VERSION ""

NS_ :

BS_:

BU_: SR_RR SR_RF SR_LR SR_LF DACU

BO_ 277 DACU_EgoMotionRaw_Vic4: 32 DACU
 SG_ EgoMotionRaw_RAxleLeftWSpeed : 72|16@1+ (0.00390625,0) [0|255.99609375] "Km_per_h"  SR_LF,SR_LR,SR_RR,SR_RF
 SG_ EgoMotionRaw_RelLvlRrAxleLeft : 160|16@1+ (0.1,-3200) [-3200|3353.5] "mm"  SR_RF,SR_LR,SR_LF,SR_RR
 SG_ EgoMotionRaw_RelLvlFrAxleRight : 208|16@1+ (0.1,-3200) [-3200|3353.5] "mm"  SR_LF,SR_RF,SR_LR,SR_RR
 SG_ EgoMotionRaw_AccPedalPos : 128|8@1+ (0.4,0) [0|102] "Percent"  SR_RF,SR_LF,SR_RR,SR_LR
 SG_ EgoMotionRaw_BrakePedalPosition : 120|8@1+ (0.4,0) [0|102] "Percent"  SR_LR,SR_RR,SR_RF,SR_LF
 SG_ EgoMotionRaw_FrAxleLeftWSpeed : 24|16@1+ (0.00390625,0) [0|255.99609375] "Km_per_h"  SR_LF,SR_RR,SR_LR,SR_RF
 SG_ EgoMotionRaw_FrontWheelAngle : 56|16@1+ (5E-005,-1.6) [-1.6|1.67675] "rad"  SR_LF,SR_LR,SR_RF,SR_RR
 SG_ EgoMotionRaw_ASREngineA : 152|2@1+ (1,0) [0|0] ""  SR_RR,SR_RF,SR_LF,SR_LR
 SG_ EgoMotionRaw_ASRBrakeA : 156|2@1+ (1,0) [0|0] ""  SR_LR,SR_RR,SR_RF,SR_LF
 SG_ EgoMotionRaw_ABSActive : 144|2@1+ (1,0) [0|0] ""  SR_RR,SR_LR,SR_RF,SR_LF
 SG_ EgoMotionRaw_VDCFullyOperational : 146|2@1+ (1,0) [0|0] ""  SR_LR,SR_RF,SR_RR,SR_LF
 SG_ EgoMotionRaw_ROPEngineActive : 148|2@1+ (1,0) [0|0] ""  SR_LF,SR_LR,SR_RR,SR_RF
 SG_ EgoMotionRaw_YCBrakeActive : 154|2@1+ (1,0) [0|0] ""  SR_LR,SR_RF,SR_RR,SR_LF
 SG_ EgoMotionRaw_GrossCombVehWeight : 224|16@1+ (10,0) [0|655350] "kg"  SR_LF,SR_RF,SR_RR,SR_LR
 SG_ EgoMotionRaw_RelLvlFrAxleLeft : 192|16@1+ (0.1,-3200) [-3200|3353.5] "mm"  SR_RF,SR_LF,SR_LR,SR_RR
 SG_ EgoMotionRaw_Counter : 16|8@1+ (1,0) [0|255] "Count"  SR_RF,SR_RR,SR_LR,SR_LF
 SG_ EgoMotionRaw_RAxleRightWSpeed : 88|16@1+ (0.00390625,0) [0|255.99609375] "Km_per_h"  SR_LF,SR_LR,SR_RF,SR_RR
 SG_ EgoMotionRaw_TrailerConStatus : 240|4@1+ (1,0) [0|0] ""  SR_RF,SR_LR,SR_RR,SR_LF
 SG_ EgoMotionRaw_FrAxleRightWSpeed : 40|16@1+ (0.00390625,0) [0|255.99609375] "Km_per_h"  SR_RF,SR_LR,SR_LF,SR_RR
 SG_ EgoMotionRaw_SteeringWheelAngle : 104|16@1+ (0.0009765625,-31.374) [-31.374|32.6250234375] "rad"  SR_LF,SR_RF,SR_RR,SR_LR
 SG_ EgoMotionRaw_ABSOp : 244|2@1+ (1,0) [0|0] ""  SR_RF,SR_LR,SR_LF,SR_RR
 SG_ EgoMotionRaw_CRC : 0|16@1+ (1,0) [0|65535] "NotApplicable"  SR_RR,SR_RF,SR_LR,SR_LF
 SG_ EgoMotionRaw_ROPBrakeActive : 150|2@1+ (1,0) [0|0] ""  SR_LF,SR_LR,SR_RF,SR_RR
 SG_ EgoMotionRaw_RelLvlRrAxleRight : 176|16@1+ (0.1,-3200) [-3200|3353.5] "mm"  SR_LR,SR_RR,SR_RF,SR_LF
 SG_ EgoMotionRaw_YCEngineActive : 142|2@1+ (1,0) [0|0] ""  SR_LR,SR_RR,SR_RF,SR_LF
 SG_ EgoMotionRaw_SteeringWheelRatio : 136|6@1+ (1,0) [0|63] "NotApplicable"  SR_LF,SR_RF,SR_RR,SR_LR
 SG_ EgoMotionRaw_AccKckDwn : 158|2@1+ (1,0) [0|0] ""  SR_RF,SR_LF,SR_RR,SR_LR

BO_ 1984 DACU_Debug29_Vic4: 64 DACU
 SG_ Debug_29_DACU : 0|512@1+ (1,0) [0|0] "" Vector__XXX

BO_ 1983 DACU_Debug28_Vic4: 64 DACU
 SG_ Debug_28_DACU : 0|512@1+ (1,0) [0|0] "" Vector__XXX

BO_ 1982 DACU_Debug27_Vic4: 64 DACU
 SG_ Debug_27_DACU : 0|512@1+ (1,0) [0|0] "" Vector__XXX

BO_ 1981 DACU_Debug26_Vic4: 64 DACU
 SG_ Debug_26_DACU : 0|512@1+ (1,0) [0|0] "" Vector__XXX

BO_ 1980 DACU_Debug25_Vic4: 64 DACU
 SG_ Debug_25_DACU : 0|512@1+ (1,0) [0|0] "" Vector__XXX

BO_ 1979 DACU_Debug24_Vic4: 64 DACU
 SG_ Debug_24_DACU : 0|512@1+ (1,0) [0|0] "" Vector__XXX

BO_ 1978 DACU_Debug23_Vic4: 64 DACU
 SG_ Debug_23_DACU : 0|512@1+ (1,0) [0|0] "" Vector__XXX

BO_ 1977 DACU_Debug22_Vic4: 64 DACU
 SG_ Debug_22_DACU : 0|512@1+ (1,0) [0|0] "" Vector__XXX

BO_ 1541 DACU_07P_Vic4: 48 DACU
 SG_ Trailer5Data_TotAxleCount : 256|8@1+ (1,0) [0|255] "NotApplicable"  SR_RR,SR_LR,SR_LF,SR_RF
 SG_ Trailer1Data_Validity : 56|2@1+ (1,0) [0|0] ""  SR_LF,SR_RR,SR_LR,SR_RF
 SG_ Trailer4Data_Validity : 248|2@1+ (1,0) [0|0] ""  SR_RR,SR_RF,SR_LF,SR_LR
 SG_ Trailer3Data_FrAxleCount : 136|8@1+ (1,0) [0|255] "NotApplicable"  SR_RR,SR_LF,SR_LR,SR_RF
 SG_ Trailer1Data_Length : 16|8@1+ (0.1,0) [0|25.5] "m"  SR_LF,SR_LR,SR_RR,SR_RF
 SG_ Trailer1Data_Wheelbase : 32|8@1+ (0.1,0) [0|25.5] "m"  SR_RR,SR_LF,SR_RF,SR_LR
 SG_ Trailer2Data_DistToCouplingP : 104|8@1+ (0.1,0) [0|25.5] "m"  SR_RR,SR_LR,SR_RF,SR_LF
 SG_ Trailer4Data_Type : 240|8@1+ (1,0) [0|255] "NotApplicable"  SR_RF,SR_RR,SR_LF,SR_LR
 SG_ Trailer5Data_DistToCouplingP : 296|8@1+ (0.1,0) [0|25.5] "m"  SR_RF,SR_LR,SR_RR,SR_LF
 SG_ Trailer2Data_Wheelbase : 96|8@1+ (0.1,0) [0|25.5] "m"  SR_LR,SR_RF,SR_RR,SR_LF
 SG_ Trailer5Data_Type : 304|8@1+ (1,0) [0|255] "NotApplicable"  SR_RF,SR_LF,SR_RR,SR_LR
 SG_ Trailer4Data_TotAxleCount : 192|8@1+ (1,0) [0|255] "NotApplicable"  SR_LF,SR_RR,SR_LR,SR_RF
 SG_ Trailer4Data_Length : 208|8@1+ (0.1,0) [0|25.5] "m"  SR_LF,SR_LR,SR_RR,SR_RF
 SG_ Trailer5Data_Validity : 312|2@1+ (1,0) [0|0] ""  SR_LR,SR_RR,SR_LF,SR_RF
 SG_ Trailer3Data_Wheelbase : 160|8@1+ (0.1,0) [0|25.5] "m"  SR_LF,SR_LR,SR_RR,SR_RF
 SG_ Trailer3Data_Length : 144|8@1+ (0.1,0) [0|25.5] "m"  SR_RR,SR_RF,SR_LR,SR_LF
 SG_ Trailer3Data_DistToCouplingP : 168|8@1+ (0.1,0) [0|25.5] "m"  SR_LR,SR_RF,SR_LF,SR_RR
 SG_ Trailer3Data_DrawbarLength : 152|8@1+ (0.1,0) [0|25.5] "m"  SR_LF,SR_RR,SR_RF,SR_LR
 SG_ Trailer5Data_FrAxleCount : 264|8@1+ (1,0) [0|255] "NotApplicable"  SR_RR,SR_RF,SR_LF,SR_LR
 SG_ Trailer2Data_DrawbarLength : 88|8@1+ (0.1,0) [0|25.5] "m"  SR_LF,SR_LR,SR_RR,SR_RF
 SG_ Trailer5Data_Wheelbase : 288|8@1+ (0.1,0) [0|25.5] "m"  SR_RR,SR_LR,SR_LF,SR_RF
 SG_ Trailer2Data_TotAxleCount : 64|8@1+ (1,0) [0|255] "NotApplicable"  SR_LF,SR_RF,SR_RR,SR_LR
 SG_ Trailer4Data_Wheelbase : 224|8@1+ (0.1,0) [0|25.5] "m"  SR_RF,SR_LF,SR_LR,SR_RR
 SG_ Trailer3Data_Validity : 184|2@1+ (1,0) [0|0] ""  SR_RR,SR_LR,SR_LF,SR_RF
 SG_ Trailer2Data_Validity : 120|2@1+ (1,0) [0|0] ""  SR_RF,SR_LF,SR_LR,SR_RR
 SG_ Trailer2Data_FrAxleCount : 72|8@1+ (1,0) [0|255] "NotApplicable"  SR_LF,SR_LR,SR_RF,SR_RR
 SG_ Trailer1Data_TotAxleCount : 0|8@1+ (1,0) [0|255] "NotApplicable"  SR_LF,SR_RF,SR_LR,SR_RR
 SG_ Trailer1Data_DistToCouplingP : 40|8@1+ (0.1,0) [0|25.5] "m"  SR_RR,SR_LR,SR_RF,SR_LF
 SG_ Trailer5Data_Length : 272|8@1+ (0.1,0) [0|25.5] "m"  SR_LF,SR_RR,SR_RF,SR_LR
 SG_ Trailer4Data_DistToCouplingP : 232|8@1+ (0.1,0) [0|25.5] "m"  SR_RF,SR_LF,SR_LR,SR_RR
 SG_ Trailer3Data_TotAxleCount : 128|8@1+ (1,0) [0|255] "NotApplicable"  SR_LR,SR_RR,SR_LF,SR_RF
 SG_ Trailer3Data_Type : 176|8@1+ (1,0) [0|255] "NotApplicable"  SR_RF,SR_LF,SR_RR,SR_LR
 SG_ Trailer2Data_Type : 112|8@1+ (1,0) [0|255] "NotApplicable"  SR_RR,SR_LR,SR_LF,SR_RF
 SG_ Trailer1Data_FrAxleCount : 8|8@1+ (1,0) [0|255] "NotApplicable"  SR_RR,SR_LR,SR_LF,SR_RF
 SG_ Trailer5Data_DrawbarLength : 280|8@1+ (0.1,0) [0|25.5] "m"  SR_RR,SR_RF,SR_LR,SR_LF
 SG_ Trailer1Data_Type : 48|8@1+ (1,0) [0|255] "NotApplicable"  SR_LR,SR_RR,SR_LF,SR_RF
 SG_ Trailer1Data_DrawbarLength : 24|8@1+ (0.1,0) [0|25.5] "m"  SR_LF,SR_LR,SR_RF,SR_RR
 SG_ Trailer4Data_FrAxleCount : 200|8@1+ (1,0) [0|255] "NotApplicable"  SR_LF,SR_LR,SR_RR,SR_RF
 SG_ Trailer2Data_Length : 80|8@1+ (0.1,0) [0|25.5] "m"  SR_RF,SR_LF,SR_RR,SR_LR
 SG_ Trailer4Data_DrawbarLength : 216|8@1+ (0.1,0) [0|25.5] "m"  SR_LR,SR_RR,SR_RF,SR_LF

BO_ 1543 DACU_06P_Vic4: 20 DACU
 SG_ VIN_DACU_Byte06 : 48|8@1+ (1,0) [0|0] ""  SR_LR,SR_LF,SR_RR,SR_RF
 SG_ VIN_DACU_Byte08 : 64|8@1+ (1,0) [0|0] ""  SR_RR,SR_LR,SR_LF,SR_RF
 SG_ VIN_DACU_Byte00 : 0|8@1+ (1,0) [0|0] ""  SR_RR,SR_RF,SR_LF,SR_LR
 SG_ VIN_DACU_Byte16 : 128|8@1+ (1,0) [0|0] ""  SR_LF,SR_LR,SR_RF,SR_RR
 SG_ VIN_DACU_Byte04 : 32|8@1+ (1,0) [0|0] ""  SR_RR,SR_LR,SR_RF,SR_LF
 SG_ VIN_DACU_Byte10 : 80|8@1+ (1,0) [0|0] ""  SR_LR,SR_LF,SR_RF,SR_RR
 SG_ VIN_DACU_Byte14 : 112|8@1+ (1,0) [0|0] ""  SR_LF,SR_RR,SR_LR,SR_RF
 SG_ VIN_DACU_Byte12 : 96|8@1+ (1,0) [0|0] ""  SR_LF,SR_RF,SR_LR,SR_RR
 SG_ VIN_DACU_Byte07 : 56|8@1+ (1,0) [0|0] ""  SR_RF,SR_LF,SR_LR,SR_RR
 SG_ VIN_DACU_Byte15 : 120|8@1+ (1,0) [0|0] ""  SR_RR,SR_LR,SR_LF,SR_RF
 SG_ VIN_DACU_Byte09 : 72|8@1+ (1,0) [0|0] ""  SR_LR,SR_RR,SR_LF,SR_RF
 SG_ VIN_DACU_Byte05 : 40|8@1+ (1,0) [0|0] ""  SR_LF,SR_RR,SR_LR,SR_RF
 SG_ VIN_DACU_Byte02 : 16|8@1+ (1,0) [0|0] ""  SR_LR,SR_LF,SR_RR,SR_RF
 SG_ VIN_DACU_Byte11 : 88|8@1+ (1,0) [0|0] ""  SR_LR,SR_RF,SR_LF,SR_RR
 SG_ VIN_DACU_Byte01 : 8|8@1+ (1,0) [0|0] ""  SR_RR,SR_RF,SR_LF,SR_LR
 SG_ VIN_DACU_Byte03 : 24|8@1+ (1,0) [0|0] ""  SR_RF,SR_LF,SR_LR,SR_RR
 SG_ VIN_DACU_Byte13 : 104|8@1+ (1,0) [0|0] ""  SR_LR,SR_RR,SR_LF,SR_RF

BO_ 1265 DACU_04P_Vic4: 48 DACU
 SG_ MinutesUTC : 32|8@1+ (1,0) [0|255] "min"  SR_LR,SR_LF,SR_RF,SR_RR
 SG_ Trailer1GeometricData_Content : 192|8@1+ (1,0) [0|255] ""  SR_RR,SR_LR,SR_RF,SR_LF
 SG_ DayUTC : 16|8@1+ (0.25,0) [0|63.75] "Days"  SR_RR,SR_LR,SR_LF,SR_RF
 SG_ Trailer2GeometricData_Content : 208|8@1+ (1,0) [0|255] ""  SR_RF,SR_LF,SR_RR,SR_LR
 SG_ TotalVehicleDistanceHighRes : 160|32@1+ (5,0) [0|21474836475] "m"  SR_RF,SR_LR,SR_RR,SR_LF
 SG_ Trailer4GeometricData_Content : 240|8@1+ (1,0) [0|255] ""  SR_RR,SR_LF,SR_RF,SR_LR
 SG_ TertiaryDriveAxleLoad_UB : 278|1@1+ (1,0) [0|0] ""  SR_LF,SR_RF,SR_RR,SR_LR
 SG_ FrontAxle2Load_UB : 273|1@1+ (1,0) [0|0] ""  SR_LR,SR_RR,SR_RF,SR_LF
 SG_ PusherAxleLoad : 112|16@1+ (0.5,0) [0|32767.5] "kg"  SR_RF,SR_LF,SR_LR,SR_RR
 SG_ DriveAxleLoad : 80|16@1+ (0.5,0) [0|32767.5] "kg"  SR_LF,SR_RR,SR_RF,SR_LR
 SG_ FrontAxle1Load : 48|16@1+ (0.5,0) [0|32767.5] "kg"  SR_LR,SR_RF,SR_LF,SR_RR
 SG_ TagAxleLoad_UB : 276|1@1+ (1,0) [0|0] ""  SR_LF,SR_LR,SR_RF,SR_RR
 SG_ YearUTC : 0|8@1+ (1,1985) [1985|2240] "Years"  SR_LF,SR_RF,SR_RR,SR_LR
 SG_ TertiaryDriveAxleLoad : 288|16@1+ (0.5,0) [0|32767.5] "kg"  SR_LF,SR_RR,SR_RF,SR_LR
 SG_ SecondsUTC : 40|8@1+ (0.25,0) [0|63.75] "s"  SR_RR,SR_LF,SR_LR,SR_RF
 SG_ Trailer1GeometricData_Index : 200|8@1+ (1,0) [0|0] ""  SR_RF,SR_LR,SR_LF,SR_RR
 SG_ DriveAxleLoad_UB : 274|1@1+ (1,0) [0|0] ""  SR_RF,SR_LR,SR_LF,SR_RR
 SG_ HoursUTC : 24|8@1+ (1,0) [0|255] "h"  SR_RF,SR_LF,SR_LR,SR_RR
 SG_ FrontAxle2Load : 64|16@1+ (0.5,0) [0|32767.5] "kg"  SR_RR,SR_RF,SR_LF,SR_LR
 SG_ MonthUTC : 8|8@1+ (1,0) [0|255] "Months"  SR_RR,SR_LF,SR_RF,SR_LR
 SG_ Trailer5GeometricData_Index : 264|8@1+ (1,0) [0|0] ""  SR_LR,SR_LF,SR_RR,SR_RF
 SG_ FrontAxle1Load_UB : 272|1@1+ (1,0) [0|0] ""  SR_RF,SR_RR,SR_LF,SR_LR
 SG_ Trailer3GeometricData_Content : 232|8@1+ (1,0) [0|255] ""  SR_RF,SR_LF,SR_RR,SR_LR
 SG_ Trailer5GeometricData_Content : 256|8@1+ (1,0) [0|255] ""  SR_LF,SR_RF,SR_LR,SR_RR
 SG_ TagAxleLoad : 128|16@1+ (0.5,0) [0|32767.5] "kg"  SR_LR,SR_LF,SR_RR,SR_RF
 SG_ AmbientAirTemperature : 144|16@1+ (0.03125,-273) [-273|1774.96875] "DegreeC"  SR_RR,SR_LF,SR_LR,SR_RF
 SG_ Trailer4GeometricData_Index : 248|8@1+ (1,0) [0|0] ""  SR_RF,SR_LR,SR_RR,SR_LF
 SG_ SecondaryDriveAxleLoad_UB : 275|1@1+ (1,0) [0|0] ""  SR_RF,SR_RR,SR_LR,SR_LF
 SG_ Trailer2GeometricData_Index : 216|8@1+ (1,0) [0|0] ""  SR_LF,SR_RF,SR_LR,SR_RR
 SG_ SecondaryDriveAxleLoad : 96|16@1+ (0.5,0) [0|32767.5] "kg"  SR_RR,SR_LR,SR_RF,SR_LF
 SG_ BendingAngle : 280|8@1+ (0.5,-62.5) [-62.5|65] "deg"  SR_RF,SR_LF,SR_RR,SR_LR
 SG_ PusherAxleLoad_UB : 277|1@1+ (1,0) [0|0] ""  SR_RF,SR_LR,SR_RR,SR_LF
 SG_ Trailer3GeometricData_Index : 224|8@1+ (1,0) [0|0] ""  SR_LF,SR_RF,SR_RR,SR_LR

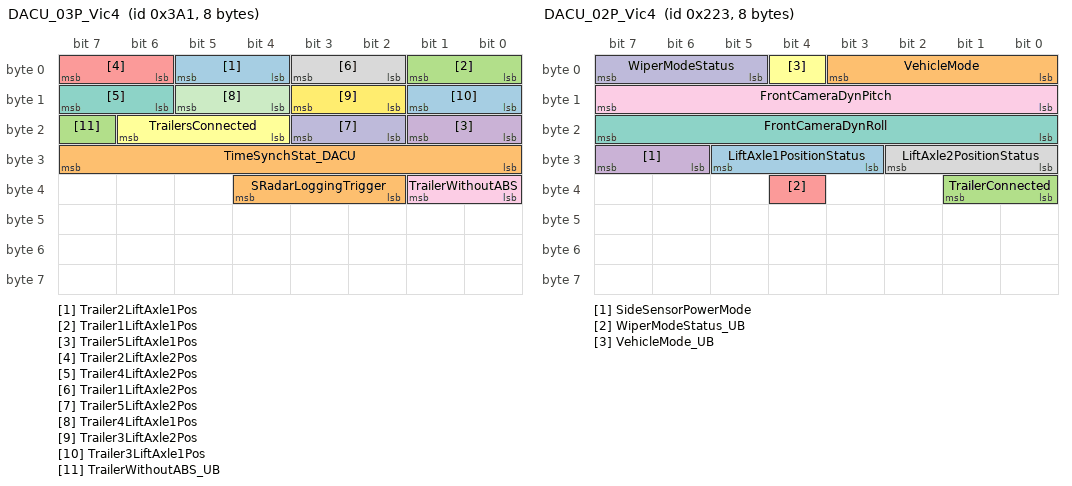
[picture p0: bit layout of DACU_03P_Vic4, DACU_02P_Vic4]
BO_ 929 DACU_03P_Vic4: 8 DACU
 SG_ Trailer2LiftAxle1Pos : 4|2@1+ (1,0) [0|0] ""  SR_RR,SR_LF,SR_RF,SR_LR
 SG_ TimeSynchStat_DACU : 24|8@1+ (1,0) [0|0] ""  SR_LF,SR_RR,SR_LR,SR_RF
 SG_ Trailer1LiftAxle1Pos : 0|2@1+ (1,0) [0|0] ""  SR_LR,SR_RR,SR_RF,SR_LF
 SG_ Trailer5LiftAxle1Pos : 16|2@1+ (1,0) [0|0] ""  SR_LR,SR_LF,SR_RF,SR_RR
 SG_ Trailer2LiftAxle2Pos : 6|2@1+ (1,0) [0|0] ""  SR_RR,SR_RF,SR_LR,SR_LF
 SG_ TrailersConnected : 20|3@1+ (1,0) [0|7] "Count"  SR_RR,SR_LR,SR_RF,SR_LF
 SG_ Trailer4LiftAxle2Pos : 14|2@1+ (1,0) [0|0] ""  SR_RF,SR_RR,SR_LR,SR_LF
 SG_ Trailer1LiftAxle2Pos : 2|2@1+ (1,0) [0|0] ""  SR_LR,SR_LF,SR_RF,SR_RR
 SG_ TrailerWithoutABS : 32|2@1+ (1,0) [0|0] ""  SR_LR,SR_LF,SR_RF,SR_RR
 SG_ Trailer5LiftAxle2Pos : 18|2@1+ (1,0) [0|0] ""  SR_RR,SR_LR,SR_LF,SR_RF
 SG_ Trailer4LiftAxle1Pos : 12|2@1+ (1,0) [0|0] ""  SR_LR,SR_RF,SR_LF,SR_RR
 SG_ Trailer3LiftAxle2Pos : 10|2@1+ (1,0) [0|0] ""  SR_RF,SR_LF,SR_LR,SR_RR
 SG_ Trailer3LiftAxle1Pos : 8|2@1+ (1,0) [0|0] ""  SR_RR,SR_LR,SR_LF,SR_RF
 SG_ SRadarLoggingTrigger : 34|3@1+ (1,0) [0|0] ""  SR_RR,SR_RF,SR_LR,SR_LF
 SG_ TrailerWithoutABS_UB : 23|1@1+ (1,0) [0|0] ""  SR_RR,SR_LF,SR_LR,SR_RF

BO_ 547 DACU_02P_Vic4: 8 DACU
 SG_ LiftAxle1PositionStatus : 27|3@1+ (1,0) [0|0] ""  SR_RF,SR_RR,SR_LR,SR_LF
 SG_ VehicleMode : 0|4@1+ (1,0) [0|0] ""  SR_RF,SR_LR,SR_LF,SR_RR
 SG_ TrailerConnected : 32|2@1+ (1,0) [0|0] ""  SR_LF,SR_RF,SR_LR,SR_RR
 SG_ SideSensorPowerMode : 30|2@1+ (1,0) [0|0] ""  SR_LR,SR_RF,SR_LF,SR_RR
 SG_ WiperModeStatus_UB : 36|1@1+ (1,0) [0|0] ""  SR_LF,SR_LR,SR_RR,SR_RF
 SG_ VehicleMode_UB : 4|1@1+ (1,0) [0|0] ""  SR_LR,SR_RR,SR_RF,SR_LF
 SG_ FrontCameraDynRoll : 16|8@1+ (0.0013,-0.12) [-0.12|0.2115] "rad"  SR_RF,SR_RR,SR_LR,SR_LF
 SG_ LiftAxle2PositionStatus : 24|3@1+ (1,0) [0|0] ""  SR_RF,SR_RR,SR_LR,SR_LF
 SG_ FrontCameraDynPitch : 8|8@1+ (0.0013,-0.12) [-0.12|0.2115] "rad"  SR_RF,SR_LF,SR_RR,SR_LR
 SG_ WiperModeStatus : 5|3@1+ (1,0) [0|0] ""  SR_LR,SR_RF,SR_RR,SR_LF

BO_ 1552 DACUSwVersion_Vic4: 64 DACU
 SG_ DACUSwVersion_Substring3 : 192|64@1+ (1,0) [0|0] ""  SR_RR,SR_LF,SR_RF,SR_LR
 SG_ DACUSwVersion_Substring1 : 64|64@1+ (1,0) [0|0] ""  SR_RR,SR_LR,SR_LF,SR_RF
 SG_ DACUSwVersion_Substring4 : 256|64@1+ (1,0) [0|0] ""  SR_RF,SR_LF,SR_RR,SR_LR
 SG_ DACUSwVersion_Substring7 : 448|64@1+ (1,0) [0|0] ""  SR_LR,SR_LF,SR_RR,SR_RF
 SG_ DACUSwVersion_Substring0 : 0|64@1+ (1,0) [0|0] ""  SR_LF,SR_RF,SR_LR,SR_RR
 SG_ DACUSwVersion_Substring6 : 384|64@1+ (1,0) [0|0] ""  SR_LR,SR_RF,SR_LF,SR_RR
 SG_ DACUSwVersion_Substring2 : 128|64@1+ (1,0) [0|0] ""  SR_LF,SR_RF,SR_LR,SR_RR
 SG_ DACUSwVersion_Substring5 : 320|64@1+ (1,0) [0|0] ""  SR_RF,SR_LR,SR_RR,SR_LF

CM_ BO_ 277 "Default 20 msec. TriggeredBy Application";
CM_ SG_ 1265 MinutesUTC "254 Error ; 255 Not available";
CM_ SG_ 1265 Trailer1GeometricData_Content "254 Error ; 255 Not Available";
CM_ SG_ 1265 DayUTC "254 Error ; 255 Not available";
CM_ SG_ 1265 Trailer2GeometricData_Content "254 Error ; 255 Not Available";
CM_ SG_ 1265 TotalVehicleDistanceHighRes "4261412864 - 4278190079 Error ; 4278190080 - 4294967295 Not available";
CM_ SG_ 1265 Trailer4GeometricData_Content "254 Error ; 255 Not Available";
CM_ SG_ 1265 PusherAxleLoad "65024 - 65279 Error ; 65280 - 65535 Not available";
CM_ SG_ 1265 DriveAxleLoad "65024 - 65279 Error ; 65280 - 65535 Not available";
CM_ SG_ 1265 FrontAxle1Load "65024 - 65279 Error ; 65280 - 65535 Not available";
CM_ SG_ 1265 YearUTC "254 Error ; 255 Not available";
CM_ SG_ 1265 SecondsUTC "254 Error ; 255 Not available";
CM_ SG_ 1265 HoursUTC "254 Error ; 255 Not available";
CM_ SG_ 1265 FrontAxle2Load "65024 - 65279 Error ; 65280 - 65535 Not available";
CM_ SG_ 1265 MonthUTC "254 Error ; 255 Not available";
CM_ SG_ 1265 Trailer3GeometricData_Content "254 Error ; 255 Not Available";
CM_ SG_ 1265 Trailer5GeometricData_Content "254 Error ; 255 Not Available";
CM_ SG_ 1265 TagAxleLoad "65024 - 65279 Error ; 65280 - 65535 Not available";
CM_ SG_ 1265 AmbientAirTemperature "65024 - 65279 Error ; 65280 - 65535 Not available";
CM_ SG_ 1265 SecondaryDriveAxleLoad "65024 - 65279 Error ; 65280 - 65535 Not available";
CM_ SG_ 929 TrailersConnected "6 Error ; 7 Not available";
BA_DEF_ BO_  "GenMsgStartDelayTime" INT 0 0;
BA_DEF_ BO_  "GenMsgDelayTime" INT 0 0;
BA_DEF_ BO_  "GenMsgCycleTime" INT 0 0;
BA_DEF_ BO_  "GenMsgSendType" ENUM  "Cyclic","NotUsed","NotUsed","NotUsed","NotUsed","NotUsed","NotUsed","IfActive","NoMsgSendType","NotUsed";
BA_DEF_ SG_  "GenSigStartValue" INT 0 0;
BA_DEF_ SG_  "GenSigCycleTimeActive" INT 0 0;
BA_DEF_ SG_  "GenSigCycleTime" INT 0 0;
BA_DEF_ SG_  "GenSigSendType" ENUM  "Cyclic","OnWrite","OnWriteWithRepetition","OnChange","OnChangeWithRepetition","IfActive","IfActiveWithRepetition","NoSigSendType","NotUsed","NotUsed","NotUsed","NotUsed","NotUsed";
BA_DEF_ BO_  "VFrameFormat" ENUM  "StandardCAN","ExtendedCAN","reserved","J1939PG","reserved","reserved","reserved","reserved","reserved","reserved","reserved","reserved","reserved","reserved","StandardCAN_FD","ExtendedCAN_FD";
BA_DEF_ SG_  "SigType" ENUM  "Default","Range","RangeSigned","ASCII","Discrete","Control","ReferencePGN","DTC","StringDelimiter","StringLength","StringLengthControl";
BA_DEF_ SG_  "SeToolVersion_SIGNAL" STRING ;
BA_DEF_ SG_  "SeToolUniqueID_SIGNAL" STRING ;
BA_DEF_ SG_  "SeToolName_SIGNAL" STRING ;
BA_DEF_ SG_  "SeToolItemID_SIGNAL" STRING ;
BA_DEF_ SG_  "SeToolAncestorID_SIGNAL" STRING ;
BA_DEF_ SG_  "Platform_VMCU1_Sig" ENUM  "No","Yes";
BA_DEF_ SG_  "NeedsUpdateBit" ENUM  "No","Yes";
BA_DEF_ SG_  "GenSigMaxLatency" INT 0 65535;
BA_DEF_ SG_  "GenSigILSupport" ENUM  "Yes","No";
BA_DEF_ BO_  "GenMsgILSupport" ENUM  "No","Yes";
BA_DEF_ SG_  "E2EProfile" STRING ;
BA_DEF_ SG_  "E2EDataLength" INT 0 65535;
BA_DEF_ SG_  "E2EDataId" INT 0 65535;
BA_DEF_ BO_  "DiagUUDTResponse" ENUM  "No","Yes";
BA_DEF_ BO_  "DiagState" ENUM  "No","Yes";
BA_DEF_ BO_  "DiagResponse" ENUM  "No","Yes";
BA_DEF_ BO_  "DiagRequest" ENUM  "No","Yes";
BA_DEF_ BO_  "DiagConnection" HEX 0 65535;
BA_DEF_ BO_  "CanTpFcFrameId" HEX 0 2147483647;
BA_DEF_ BO_  "CanTpBs" INT 0 255;
BA_DEF_ BO_  "CANFD_BRS" ENUM  "0","1";
BA_DEF_REL_ BU_SG_REL_  "GenSigTimeoutTime" INT 0 65535;
BA_DEF_REL_ BU_SG_REL_  "GenSigFirstTimeoutTime" INT 0 65535;
BA_DEF_DEF_  "GenMsgStartDelayTime" 0;
BA_DEF_DEF_  "GenMsgDelayTime" 0;
BA_DEF_DEF_  "GenMsgCycleTime" 0;
BA_DEF_DEF_  "GenMsgSendType" "Cyclic";
BA_DEF_DEF_  "GenSigStartValue" 0;
BA_DEF_DEF_  "GenSigCycleTimeActive" 0;
BA_DEF_DEF_  "GenSigCycleTime" 0;
BA_DEF_DEF_  "GenSigSendType" "Cyclic";
BA_DEF_DEF_  "VFrameFormat" "ExtendedCAN";
BA_DEF_DEF_  "SigType" "Default";
BA_DEF_DEF_  "SeToolVersion_SIGNAL" "";
BA_DEF_DEF_  "SeToolUniqueID_SIGNAL" "";
BA_DEF_DEF_  "SeToolName_SIGNAL" "";
BA_DEF_DEF_  "SeToolItemID_SIGNAL" "";
BA_DEF_DEF_  "SeToolAncestorID_SIGNAL" "";
BA_DEF_DEF_  "Platform_VMCU1_Sig" "No";
BA_DEF_DEF_  "NeedsUpdateBit" "No";
BA_DEF_DEF_  "GenSigMaxLatency" 0;
BA_DEF_DEF_  "GenSigILSupport" "Yes";
BA_DEF_DEF_  "GenMsgILSupport" "Yes";
BA_DEF_DEF_  "E2EProfile" "none";
BA_DEF_DEF_  "E2EDataLength" 0;
BA_DEF_DEF_  "E2EDataId" 0;
BA_DEF_DEF_  "DiagUUDTResponse" "No";
BA_DEF_DEF_  "DiagState" "No";
BA_DEF_DEF_  "DiagResponse" "No";
BA_DEF_DEF_  "DiagRequest" "No";
BA_DEF_DEF_  "DiagConnection" 0;
BA_DEF_DEF_  "CanTpFcFrameId" 2147483647;
BA_DEF_DEF_  "CanTpBs" 255;
BA_DEF_DEF_  "CANFD_BRS" "0";
BA_DEF_DEF_REL_ "GenSigTimeoutTime" 0;
BA_DEF_DEF_REL_ "GenSigFirstTimeoutTime" 0;
BA_ "CANFD_BRS" BO_ 277 1;
BA_ "GenMsgSendType" BO_ 277 8;
BA_ "GenMsgStartDelayTime" BO_ 277 10;
BA_ "VFrameFormat" BO_ 277 14;
BA_ "CANFD_BRS" BO_ 1984 1;
BA_ "GenMsgSendType" BO_ 1984 8;
BA_ "GenMsgDelayTime" BO_ 1984 10;
BA_ "VFrameFormat" BO_ 1984 14;
BA_ "CANFD_BRS" BO_ 1983 1;
BA_ "GenMsgSendType" BO_ 1983 8;
BA_ "GenMsgDelayTime" BO_ 1983 10;
BA_ "VFrameFormat" BO_ 1983 14;
BA_ "CANFD_BRS" BO_ 1982 1;
BA_ "GenMsgSendType" BO_ 1982 8;
BA_ "GenMsgDelayTime" BO_ 1982 10;
BA_ "VFrameFormat" BO_ 1982 14;
BA_ "CANFD_BRS" BO_ 1981 1;
BA_ "GenMsgSendType" BO_ 1981 8;
BA_ "GenMsgDelayTime" BO_ 1981 10;
BA_ "VFrameFormat" BO_ 1981 14;
BA_ "CANFD_BRS" BO_ 1980 1;
BA_ "GenMsgSendType" BO_ 1980 8;
BA_ "GenMsgDelayTime" BO_ 1980 10;
BA_ "VFrameFormat" BO_ 1980 14;
BA_ "CANFD_BRS" BO_ 1979 1;
BA_ "GenMsgSendType" BO_ 1979 8;
BA_ "GenMsgDelayTime" BO_ 1979 10;
BA_ "VFrameFormat" BO_ 1979 14;
BA_ "CANFD_BRS" BO_ 1978 1;
BA_ "GenMsgSendType" BO_ 1978 8;
BA_ "GenMsgDelayTime" BO_ 1978 10;
BA_ "VFrameFormat" BO_ 1978 14;
BA_ "CANFD_BRS" BO_ 1977 1;
BA_ "GenMsgSendType" BO_ 1977 8;
BA_ "GenMsgDelayTime" BO_ 1977 10;
BA_ "VFrameFormat" BO_ 1977 14;
BA_ "CANFD_BRS" BO_ 1541 1;
BA_ "GenMsgCycleTime" BO_ 1541 5000;
BA_ "GenMsgStartDelayTime" BO_ 1541 230;
BA_ "VFrameFormat" BO_ 1541 14;
BA_ "CANFD_BRS" BO_ 1543 1;
BA_ "GenMsgCycleTime" BO_ 1543 5000;
BA_ "GenMsgStartDelayTime" BO_ 1543 115;
BA_ "VFrameFormat" BO_ 1543 14;
BA_ "CANFD_BRS" BO_ 1265 1;
BA_ "GenMsgCycleTime" BO_ 1265 250;
BA_ "GenMsgStartDelayTime" BO_ 1265 45;
BA_ "VFrameFormat" BO_ 1265 14;
BA_ "CANFD_BRS" BO_ 929 1;
BA_ "GenMsgCycleTime" BO_ 929 100;
BA_ "GenMsgStartDelayTime" BO_ 929 15;
BA_ "VFrameFormat" BO_ 929 14;
BA_ "CANFD_BRS" BO_ 547 1;
BA_ "GenMsgCycleTime" BO_ 547 20;
BA_ "GenMsgStartDelayTime" BO_ 547 5;
BA_ "VFrameFormat" BO_ 547 14;
BA_ "CANFD_BRS" BO_ 1552 1;
BA_ "GenMsgCycleTime" BO_ 1552 10000;
BA_ "GenMsgStartDelayTime" BO_ 1552 530;
BA_ "VFrameFormat" BO_ 1552 14;
BA_ "GenSigSendType" SG_ 277 EgoMotionRaw_RAxleLeftWSpeed 1;
BA_ "GenSigStartValue" SG_ 277 EgoMotionRaw_RAxleLeftWSpeed 65535;
BA_ "GenSigSendType" SG_ 277 EgoMotionRaw_RelLvlRrAxleLeft 1;
BA_ "GenSigStartValue" SG_ 277 EgoMotionRaw_RelLvlRrAxleLeft 65535;
BA_ "GenSigSendType" SG_ 277 EgoMotionRaw_RelLvlFrAxleRight 1;
BA_ "GenSigStartValue" SG_ 277 EgoMotionRaw_RelLvlFrAxleRight 65535;
BA_ "GenSigSendType" SG_ 277 EgoMotionRaw_AccPedalPos 1;
BA_ "GenSigStartValue" SG_ 277 EgoMotionRaw_AccPedalPos 255;
BA_ "GenSigSendType" SG_ 277 EgoMotionRaw_BrakePedalPosition 1;
BA_ "GenSigStartValue" SG_ 277 EgoMotionRaw_BrakePedalPosition 255;
BA_ "GenSigSendType" SG_ 277 EgoMotionRaw_FrAxleLeftWSpeed 1;
BA_ "GenSigStartValue" SG_ 277 EgoMotionRaw_FrAxleLeftWSpeed 65535;
BA_ "GenSigSendType" SG_ 277 EgoMotionRaw_FrontWheelAngle 1;
BA_ "GenSigStartValue" SG_ 277 EgoMotionRaw_FrontWheelAngle 65535;
BA_ "GenSigSendType" SG_ 277 EgoMotionRaw_ASREngineA 1;
BA_ "GenSigStartValue" SG_ 277 EgoMotionRaw_ASREngineA 3;
BA_ "GenSigSendType" SG_ 277 EgoMotionRaw_ASRBrakeA 1;
BA_ "GenSigStartValue" SG_ 277 EgoMotionRaw_ASRBrakeA 3;
BA_ "GenSigSendType" SG_ 277 EgoMotionRaw_ABSActive 1;
BA_ "GenSigStartValue" SG_ 277 EgoMotionRaw_ABSActive 3;
BA_ "GenSigSendType" SG_ 277 EgoMotionRaw_VDCFullyOperational 1;
BA_ "GenSigStartValue" SG_ 277 EgoMotionRaw_VDCFullyOperational 3;
BA_ "GenSigSendType" SG_ 277 EgoMotionRaw_ROPEngineActive 1;
BA_ "GenSigStartValue" SG_ 277 EgoMotionRaw_ROPEngineActive 3;
BA_ "GenSigSendType" SG_ 277 EgoMotionRaw_YCBrakeActive 1;
BA_ "GenSigStartValue" SG_ 277 EgoMotionRaw_YCBrakeActive 3;
BA_ "GenSigSendType" SG_ 277 EgoMotionRaw_GrossCombVehWeight 1;
BA_ "GenSigStartValue" SG_ 277 EgoMotionRaw_GrossCombVehWeight 65535;
BA_ "GenSigSendType" SG_ 277 EgoMotionRaw_RelLvlFrAxleLeft 1;
BA_ "GenSigStartValue" SG_ 277 EgoMotionRaw_RelLvlFrAxleLeft 65535;
BA_ "GenSigSendType" SG_ 277 EgoMotionRaw_Counter 1;
BA_ "GenSigStartValue" SG_ 277 EgoMotionRaw_Counter 255;
BA_ "GenSigSendType" SG_ 277 EgoMotionRaw_RAxleRightWSpeed 1;
BA_ "GenSigStartValue" SG_ 277 EgoMotionRaw_RAxleRightWSpeed 65535;
BA_ "GenSigSendType" SG_ 277 EgoMotionRaw_TrailerConStatus 1;
BA_ "GenSigStartValue" SG_ 277 EgoMotionRaw_TrailerConStatus 15;
BA_ "GenSigSendType" SG_ 277 EgoMotionRaw_FrAxleRightWSpeed 1;
BA_ "GenSigStartValue" SG_ 277 EgoMotionRaw_FrAxleRightWSpeed 65535;
BA_ "GenSigSendType" SG_ 277 EgoMotionRaw_SteeringWheelAngle 1;
BA_ "GenSigStartValue" SG_ 277 EgoMotionRaw_SteeringWheelAngle 65535;
BA_ "GenSigSendType" SG_ 277 EgoMotionRaw_ABSOp 1;
BA_ "GenSigStartValue" SG_ 277 EgoMotionRaw_ABSOp 3;
BA_ "GenSigSendType" SG_ 277 EgoMotionRaw_CRC 1;
BA_ "GenSigStartValue" SG_ 277 EgoMotionRaw_CRC 65535;
BA_ "E2EDataId" SG_ 277 EgoMotionRaw_CRC 74;
BA_ "E2EDataLength" SG_ 277 EgoMotionRaw_CRC 248;
BA_ "E2EProfile" SG_ 277 EgoMotionRaw_CRC "P05";
BA_ "GenSigSendType" SG_ 277 EgoMotionRaw_ROPBrakeActive 1;
BA_ "GenSigStartValue" SG_ 277 EgoMotionRaw_ROPBrakeActive 3;
BA_ "GenSigSendType" SG_ 277 EgoMotionRaw_RelLvlRrAxleRight 1;
BA_ "GenSigStartValue" SG_ 277 EgoMotionRaw_RelLvlRrAxleRight 65535;
BA_ "GenSigSendType" SG_ 277 EgoMotionRaw_YCEngineActive 1;
BA_ "GenSigStartValue" SG_ 277 EgoMotionRaw_YCEngineActive 3;
BA_ "GenSigSendType" SG_ 277 EgoMotionRaw_SteeringWheelRatio 1;
BA_ "GenSigStartValue" SG_ 277 EgoMotionRaw_SteeringWheelRatio 63;
BA_ "GenSigSendType" SG_ 277 EgoMotionRaw_AccKckDwn 1;
BA_ "GenSigStartValue" SG_ 277 EgoMotionRaw_AccKckDwn 3;
BA_ "GenSigSendType" SG_ 1984 Debug_29_DACU 1;
BA_ "GenSigSendType" SG_ 1983 Debug_28_DACU 1;
BA_ "GenSigSendType" SG_ 1982 Debug_27_DACU 1;
BA_ "GenSigSendType" SG_ 1981 Debug_26_DACU 1;
BA_ "GenSigSendType" SG_ 1980 Debug_25_DACU 1;
BA_ "GenSigSendType" SG_ 1979 Debug_24_DACU 1;
BA_ "GenSigSendType" SG_ 1978 Debug_23_DACU 1;
BA_ "GenSigSendType" SG_ 1977 Debug_22_DACU 1;
BA_ "GenSigCycleTime" SG_ 1541 Trailer5Data_TotAxleCount 100;
BA_ "GenSigCycleTimeActive" SG_ 1541 Trailer5Data_TotAxleCount 100;
BA_ "GenSigStartValue" SG_ 1541 Trailer5Data_TotAxleCount 255;
BA_ "GenSigCycleTime" SG_ 1541 Trailer1Data_Validity 100;
BA_ "GenSigCycleTimeActive" SG_ 1541 Trailer1Data_Validity 100;
BA_ "GenSigStartValue" SG_ 1541 Trailer1Data_Validity 3;
BA_ "GenSigCycleTime" SG_ 1541 Trailer4Data_Validity 100;
BA_ "GenSigCycleTimeActive" SG_ 1541 Trailer4Data_Validity 100;
BA_ "GenSigStartValue" SG_ 1541 Trailer4Data_Validity 3;
BA_ "GenSigCycleTime" SG_ 1541 Trailer3Data_FrAxleCount 100;
BA_ "GenSigCycleTimeActive" SG_ 1541 Trailer3Data_FrAxleCount 100;
BA_ "GenSigStartValue" SG_ 1541 Trailer3Data_FrAxleCount 255;
BA_ "GenSigCycleTime" SG_ 1541 Trailer1Data_Length 100;
BA_ "GenSigCycleTimeActive" SG_ 1541 Trailer1Data_Length 100;
BA_ "GenSigStartValue" SG_ 1541 Trailer1Data_Length 255;
BA_ "GenSigCycleTime" SG_ 1541 Trailer1Data_Wheelbase 100;
BA_ "GenSigCycleTimeActive" SG_ 1541 Trailer1Data_Wheelbase 100;
BA_ "GenSigStartValue" SG_ 1541 Trailer1Data_Wheelbase 255;
BA_ "GenSigCycleTime" SG_ 1541 Trailer2Data_DistToCouplingP 100;
BA_ "GenSigCycleTimeActive" SG_ 1541 Trailer2Data_DistToCouplingP 100;
BA_ "GenSigStartValue" SG_ 1541 Trailer2Data_DistToCouplingP 255;
BA_ "GenSigCycleTime" SG_ 1541 Trailer4Data_Type 100;
BA_ "GenSigCycleTimeActive" SG_ 1541 Trailer4Data_Type 100;
BA_ "GenSigStartValue" SG_ 1541 Trailer4Data_Type 255;
BA_ "GenSigCycleTime" SG_ 1541 Trailer5Data_DistToCouplingP 100;
BA_ "GenSigCycleTimeActive" SG_ 1541 Trailer5Data_DistToCouplingP 100;
BA_ "GenSigStartValue" SG_ 1541 Trailer5Data_DistToCouplingP 255;
BA_ "GenSigCycleTime" SG_ 1541 Trailer2Data_Wheelbase 100;
BA_ "GenSigCycleTimeActive" SG_ 1541 Trailer2Data_Wheelbase 100;
BA_ "GenSigStartValue" SG_ 1541 Trailer2Data_Wheelbase 255;
BA_ "GenSigCycleTime" SG_ 1541 Trailer5Data_Type 100;
BA_ "GenSigCycleTimeActive" SG_ 1541 Trailer5Data_Type 100;
BA_ "GenSigStartValue" SG_ 1541 Trailer5Data_Type 255;
BA_ "GenSigCycleTime" SG_ 1541 Trailer4Data_TotAxleCount 100;
BA_ "GenSigCycleTimeActive" SG_ 1541 Trailer4Data_TotAxleCount 100;
BA_ "GenSigStartValue" SG_ 1541 Trailer4Data_TotAxleCount 255;
BA_ "GenSigCycleTime" SG_ 1541 Trailer4Data_Length 100;
BA_ "GenSigCycleTimeActive" SG_ 1541 Trailer4Data_Length 100;
BA_ "GenSigStartValue" SG_ 1541 Trailer4Data_Length 255;
BA_ "GenSigCycleTime" SG_ 1541 Trailer5Data_Validity 100;
BA_ "GenSigCycleTimeActive" SG_ 1541 Trailer5Data_Validity 100;
BA_ "GenSigStartValue" SG_ 1541 Trailer5Data_Validity 3;
BA_ "GenSigCycleTime" SG_ 1541 Trailer3Data_Wheelbase 100;
BA_ "GenSigCycleTimeActive" SG_ 1541 Trailer3Data_Wheelbase 100;
BA_ "GenSigStartValue" SG_ 1541 Trailer3Data_Wheelbase 255;
BA_ "GenSigCycleTime" SG_ 1541 Trailer3Data_Length 100;
BA_ "GenSigCycleTimeActive" SG_ 1541 Trailer3Data_Length 100;
BA_ "GenSigStartValue" SG_ 1541 Trailer3Data_Length 255;
BA_ "GenSigCycleTime" SG_ 1541 Trailer3Data_DistToCouplingP 100;
BA_ "GenSigCycleTimeActive" SG_ 1541 Trailer3Data_DistToCouplingP 100;
BA_ "GenSigStartValue" SG_ 1541 Trailer3Data_DistToCouplingP 255;
BA_ "GenSigCycleTime" SG_ 1541 Trailer3Data_DrawbarLength 100;
BA_ "GenSigCycleTimeActive" SG_ 1541 Trailer3Data_DrawbarLength 100;
BA_ "GenSigStartValue" SG_ 1541 Trailer3Data_DrawbarLength 255;
BA_ "GenSigCycleTime" SG_ 1541 Trailer5Data_FrAxleCount 100;
BA_ "GenSigCycleTimeActive" SG_ 1541 Trailer5Data_FrAxleCount 100;
BA_ "GenSigStartValue" SG_ 1541 Trailer5Data_FrAxleCount 255;
BA_ "GenSigCycleTime" SG_ 1541 Trailer2Data_DrawbarLength 100;
BA_ "GenSigCycleTimeActive" SG_ 1541 Trailer2Data_DrawbarLength 100;
BA_ "GenSigStartValue" SG_ 1541 Trailer2Data_DrawbarLength 255;
BA_ "GenSigCycleTime" SG_ 1541 Trailer5Data_Wheelbase 100;
BA_ "GenSigCycleTimeActive" SG_ 1541 Trailer5Data_Wheelbase 100;
BA_ "GenSigStartValue" SG_ 1541 Trailer5Data_Wheelbase 255;
BA_ "GenSigCycleTime" SG_ 1541 Trailer2Data_TotAxleCount 100;
BA_ "GenSigCycleTimeActive" SG_ 1541 Trailer2Data_TotAxleCount 100;
BA_ "GenSigStartValue" SG_ 1541 Trailer2Data_TotAxleCount 255;
BA_ "GenSigCycleTime" SG_ 1541 Trailer4Data_Wheelbase 100;
BA_ "GenSigCycleTimeActive" SG_ 1541 Trailer4Data_Wheelbase 100;
BA_ "GenSigStartValue" SG_ 1541 Trailer4Data_Wheelbase 255;
BA_ "GenSigCycleTime" SG_ 1541 Trailer3Data_Validity 100;
BA_ "GenSigCycleTimeActive" SG_ 1541 Trailer3Data_Validity 100;
BA_ "GenSigStartValue" SG_ 1541 Trailer3Data_Validity 3;
BA_ "GenSigCycleTime" SG_ 1541 Trailer2Data_Validity 100;
BA_ "GenSigCycleTimeActive" SG_ 1541 Trailer2Data_Validity 100;
BA_ "GenSigStartValue" SG_ 1541 Trailer2Data_Validity 3;
BA_ "GenSigCycleTime" SG_ 1541 Trailer2Data_FrAxleCount 100;
BA_ "GenSigCycleTimeActive" SG_ 1541 Trailer2Data_FrAxleCount 100;
BA_ "GenSigStartValue" SG_ 1541 Trailer2Data_FrAxleCount 255;
BA_ "GenSigCycleTime" SG_ 1541 Trailer1Data_TotAxleCount 100;
BA_ "GenSigCycleTimeActive" SG_ 1541 Trailer1Data_TotAxleCount 100;
BA_ "GenSigStartValue" SG_ 1541 Trailer1Data_TotAxleCount 255;
BA_ "GenSigCycleTime" SG_ 1541 Trailer1Data_DistToCouplingP 100;
BA_ "GenSigCycleTimeActive" SG_ 1541 Trailer1Data_DistToCouplingP 100;
BA_ "GenSigStartValue" SG_ 1541 Trailer1Data_DistToCouplingP 255;
BA_ "GenSigCycleTime" SG_ 1541 Trailer5Data_Length 100;
BA_ "GenSigCycleTimeActive" SG_ 1541 Trailer5Data_Length 100;
BA_ "GenSigStartValue" SG_ 1541 Trailer5Data_Length 255;
BA_ "GenSigCycleTime" SG_ 1541 Trailer4Data_DistToCouplingP 100;
BA_ "GenSigCycleTimeActive" SG_ 1541 Trailer4Data_DistToCouplingP 100;
BA_ "GenSigStartValue" SG_ 1541 Trailer4Data_DistToCouplingP 255;
BA_ "GenSigCycleTime" SG_ 1541 Trailer3Data_TotAxleCount 100;
BA_ "GenSigCycleTimeActive" SG_ 1541 Trailer3Data_TotAxleCount 100;
BA_ "GenSigStartValue" SG_ 1541 Trailer3Data_TotAxleCount 255;
BA_ "GenSigCycleTime" SG_ 1541 Trailer3Data_Type 100;
BA_ "GenSigCycleTimeActive" SG_ 1541 Trailer3Data_Type 100;
BA_ "GenSigStartValue" SG_ 1541 Trailer3Data_Type 255;
BA_ "GenSigCycleTime" SG_ 1541 Trailer2Data_Type 100;
BA_ "GenSigCycleTimeActive" SG_ 1541 Trailer2Data_Type 100;
BA_ "GenSigStartValue" SG_ 1541 Trailer2Data_Type 255;
BA_ "GenSigCycleTime" SG_ 1541 Trailer1Data_FrAxleCount 100;
BA_ "GenSigCycleTimeActive" SG_ 1541 Trailer1Data_FrAxleCount 100;
BA_ "GenSigStartValue" SG_ 1541 Trailer1Data_FrAxleCount 255;
BA_ "GenSigCycleTime" SG_ 1541 Trailer5Data_DrawbarLength 100;
BA_ "GenSigCycleTimeActive" SG_ 1541 Trailer5Data_DrawbarLength 100;
BA_ "GenSigStartValue" SG_ 1541 Trailer5Data_DrawbarLength 255;
BA_ "GenSigCycleTime" SG_ 1541 Trailer1Data_Type 100;
BA_ "GenSigCycleTimeActive" SG_ 1541 Trailer1Data_Type 100;
BA_ "GenSigStartValue" SG_ 1541 Trailer1Data_Type 255;
BA_ "GenSigCycleTime" SG_ 1541 Trailer1Data_DrawbarLength 100;
BA_ "GenSigCycleTimeActive" SG_ 1541 Trailer1Data_DrawbarLength 100;
BA_ "GenSigStartValue" SG_ 1541 Trailer1Data_DrawbarLength 255;
BA_ "GenSigCycleTime" SG_ 1541 Trailer4Data_FrAxleCount 100;
BA_ "GenSigCycleTimeActive" SG_ 1541 Trailer4Data_FrAxleCount 100;
BA_ "GenSigStartValue" SG_ 1541 Trailer4Data_FrAxleCount 255;
BA_ "GenSigCycleTime" SG_ 1541 Trailer2Data_Length 100;
BA_ "GenSigCycleTimeActive" SG_ 1541 Trailer2Data_Length 100;
BA_ "GenSigStartValue" SG_ 1541 Trailer2Data_Length 255;
BA_ "GenSigCycleTime" SG_ 1541 Trailer4Data_DrawbarLength 100;
BA_ "GenSigCycleTimeActive" SG_ 1541 Trailer4Data_DrawbarLength 100;
BA_ "GenSigStartValue" SG_ 1541 Trailer4Data_DrawbarLength 255;
BA_ "GenSigCycleTime" SG_ 1543 VIN_DACU_Byte06 100;
BA_ "GenSigCycleTimeActive" SG_ 1543 VIN_DACU_Byte06 100;
BA_ "GenSigCycleTime" SG_ 1543 VIN_DACU_Byte08 100;
BA_ "GenSigCycleTimeActive" SG_ 1543 VIN_DACU_Byte08 100;
BA_ "GenSigCycleTime" SG_ 1543 VIN_DACU_Byte00 100;
BA_ "GenSigCycleTimeActive" SG_ 1543 VIN_DACU_Byte00 100;
BA_ "GenSigCycleTime" SG_ 1543 VIN_DACU_Byte16 100;
BA_ "GenSigCycleTimeActive" SG_ 1543 VIN_DACU_Byte16 100;
BA_ "GenSigCycleTime" SG_ 1543 VIN_DACU_Byte04 100;
BA_ "GenSigCycleTimeActive" SG_ 1543 VIN_DACU_Byte04 100;
BA_ "GenSigCycleTime" SG_ 1543 VIN_DACU_Byte10 100;
BA_ "GenSigCycleTimeActive" SG_ 1543 VIN_DACU_Byte10 100;
BA_ "GenSigCycleTime" SG_ 1543 VIN_DACU_Byte14 100;
BA_ "GenSigCycleTimeActive" SG_ 1543 VIN_DACU_Byte14 100;
BA_ "GenSigCycleTime" SG_ 1543 VIN_DACU_Byte12 100;
BA_ "GenSigCycleTimeActive" SG_ 1543 VIN_DACU_Byte12 100;
BA_ "GenSigCycleTime" SG_ 1543 VIN_DACU_Byte07 100;
BA_ "GenSigCycleTimeActive" SG_ 1543 VIN_DACU_Byte07 100;
BA_ "GenSigCycleTime" SG_ 1543 VIN_DACU_Byte15 100;
BA_ "GenSigCycleTimeActive" SG_ 1543 VIN_DACU_Byte15 100;
BA_ "GenSigCycleTime" SG_ 1543 VIN_DACU_Byte09 100;
BA_ "GenSigCycleTimeActive" SG_ 1543 VIN_DACU_Byte09 100;
BA_ "GenSigCycleTime" SG_ 1543 VIN_DACU_Byte05 100;
BA_ "GenSigCycleTimeActive" SG_ 1543 VIN_DACU_Byte05 100;
BA_ "GenSigCycleTime" SG_ 1543 VIN_DACU_Byte02 100;
BA_ "GenSigCycleTimeActive" SG_ 1543 VIN_DACU_Byte02 100;
BA_ "GenSigCycleTime" SG_ 1543 VIN_DACU_Byte11 100;
BA_ "GenSigCycleTimeActive" SG_ 1543 VIN_DACU_Byte11 100;
BA_ "GenSigCycleTime" SG_ 1543 VIN_DACU_Byte01 100;
BA_ "GenSigCycleTimeActive" SG_ 1543 VIN_DACU_Byte01 100;
BA_ "GenSigCycleTime" SG_ 1543 VIN_DACU_Byte03 100;
BA_ "GenSigCycleTimeActive" SG_ 1543 VIN_DACU_Byte03 100;
BA_ "GenSigCycleTime" SG_ 1543 VIN_DACU_Byte13 100;
BA_ "GenSigCycleTimeActive" SG_ 1543 VIN_DACU_Byte13 100;
BA_ "GenSigCycleTime" SG_ 1265 MinutesUTC 100;
BA_ "GenSigCycleTimeActive" SG_ 1265 MinutesUTC 100;
BA_ "GenSigStartValue" SG_ 1265 MinutesUTC 255;
BA_ "GenSigMaxLatency" SG_ 1265 MinutesUTC 250;
BA_ "SeToolAncestorID_SIGNAL" SG_ 1265 MinutesUTC "x0000001D0412FAC0";
BA_ "SeToolItemID_SIGNAL" SG_ 1265 MinutesUTC "x0000001D041EBD29";
BA_ "SeToolName_SIGNAL" SG_ 1265 MinutesUTC "MinutesUTC";
BA_ "SeToolVersion_SIGNAL" SG_ 1265 MinutesUTC "2";
BA_ "GenSigCycleTime" SG_ 1265 Trailer1GeometricData_Content 100;
BA_ "GenSigCycleTimeActive" SG_ 1265 Trailer1GeometricData_Content 100;
BA_ "GenSigStartValue" SG_ 1265 Trailer1GeometricData_Content 255;
BA_ "GenSigMaxLatency" SG_ 1265 Trailer1GeometricData_Content 250;
BA_ "GenSigCycleTime" SG_ 1265 DayUTC 100;
BA_ "GenSigCycleTimeActive" SG_ 1265 DayUTC 100;
BA_ "GenSigStartValue" SG_ 1265 DayUTC 255;
BA_ "GenSigMaxLatency" SG_ 1265 DayUTC 250;
BA_ "SeToolAncestorID_SIGNAL" SG_ 1265 DayUTC "x0000001D0412FAC4";
BA_ "SeToolItemID_SIGNAL" SG_ 1265 DayUTC "x0000001D041EBD81";
BA_ "SeToolName_SIGNAL" SG_ 1265 DayUTC "DayUTC";
BA_ "SeToolVersion_SIGNAL" SG_ 1265 DayUTC "2";
BA_ "GenSigCycleTime" SG_ 1265 Trailer2GeometricData_Content 100;
BA_ "GenSigCycleTimeActive" SG_ 1265 Trailer2GeometricData_Content 100;
BA_ "GenSigStartValue" SG_ 1265 Trailer2GeometricData_Content 255;
BA_ "GenSigMaxLatency" SG_ 1265 Trailer2GeometricData_Content 250;
BA_ "GenSigCycleTime" SG_ 1265 TotalVehicleDistanceHighRes 100;
BA_ "GenSigCycleTimeActive" SG_ 1265 TotalVehicleDistanceHighRes 100;
BA_ "GenSigStartValue" SG_ 1265 TotalVehicleDistanceHighRes 4294967295;
BA_ "GenSigMaxLatency" SG_ 1265 TotalVehicleDistanceHighRes 250;
BA_ "SeToolAncestorID_SIGNAL" SG_ 1265 TotalVehicleDistanceHighRes "x0000001D04109E2B";
BA_ "SeToolItemID_SIGNAL" SG_ 1265 TotalVehicleDistanceHighRes "x0000001D04109E2B";
BA_ "SeToolName_SIGNAL" SG_ 1265 TotalVehicleDistanceHighRes "HighResolutionTotalVehicleDistance";
BA_ "SeToolVersion_SIGNAL" SG_ 1265 TotalVehicleDistanceHighRes "1";
BA_ "GenSigCycleTime" SG_ 1265 Trailer4GeometricData_Content 100;
BA_ "GenSigCycleTimeActive" SG_ 1265 Trailer4GeometricData_Content 100;
BA_ "GenSigStartValue" SG_ 1265 Trailer4GeometricData_Content 255;
BA_ "GenSigMaxLatency" SG_ 1265 Trailer4GeometricData_Content 250;
BA_ "GenSigSendType" SG_ 1265 TertiaryDriveAxleLoad_UB 7;
BA_ "GenSigSendType" SG_ 1265 FrontAxle2Load_UB 7;
BA_ "GenSigMaxLatency" SG_ 1265 FrontAxle2Load_UB 250;
BA_ "GenSigCycleTime" SG_ 1265 PusherAxleLoad 100;
BA_ "GenSigCycleTimeActive" SG_ 1265 PusherAxleLoad 100;
BA_ "GenSigStartValue" SG_ 1265 PusherAxleLoad 65535;
BA_ "GenSigMaxLatency" SG_ 1265 PusherAxleLoad 250;
BA_ "NeedsUpdateBit" SG_ 1265 PusherAxleLoad 1;
BA_ "SeToolAncestorID_SIGNAL" SG_ 1265 PusherAxleLoad "x0000001D0412EB1E";
BA_ "SeToolItemID_SIGNAL" SG_ 1265 PusherAxleLoad "x0000001D04274C69";
BA_ "SeToolName_SIGNAL" SG_ 1265 PusherAxleLoad "PusherAxleLoad";
BA_ "SeToolVersion_SIGNAL" SG_ 1265 PusherAxleLoad "3";
BA_ "GenSigCycleTime" SG_ 1265 DriveAxleLoad 100;
BA_ "GenSigCycleTimeActive" SG_ 1265 DriveAxleLoad 100;
BA_ "GenSigStartValue" SG_ 1265 DriveAxleLoad 65535;
BA_ "GenSigMaxLatency" SG_ 1265 DriveAxleLoad 250;
BA_ "NeedsUpdateBit" SG_ 1265 DriveAxleLoad 1;
BA_ "SeToolAncestorID_SIGNAL" SG_ 1265 DriveAxleLoad "x0000001D0412EB1E";
BA_ "SeToolItemID_SIGNAL" SG_ 1265 DriveAxleLoad "x0000001D04274C69";
BA_ "SeToolName_SIGNAL" SG_ 1265 DriveAxleLoad "DriveAxleLoad";
BA_ "SeToolVersion_SIGNAL" SG_ 1265 DriveAxleLoad "3";
BA_ "GenSigCycleTime" SG_ 1265 FrontAxle1Load 100;
BA_ "GenSigCycleTimeActive" SG_ 1265 FrontAxle1Load 100;
BA_ "GenSigStartValue" SG_ 1265 FrontAxle1Load 65535;
BA_ "GenSigMaxLatency" SG_ 1265 FrontAxle1Load 250;
BA_ "NeedsUpdateBit" SG_ 1265 FrontAxle1Load 1;
BA_ "SeToolAncestorID_SIGNAL" SG_ 1265 FrontAxle1Load "x0000001D0412EB1E";
BA_ "SeToolItemID_SIGNAL" SG_ 1265 FrontAxle1Load "x0000001D04274C69";
BA_ "SeToolName_SIGNAL" SG_ 1265 FrontAxle1Load "FrontAxle1Load";
BA_ "SeToolVersion_SIGNAL" SG_ 1265 FrontAxle1Load "3";
BA_ "GenSigSendType" SG_ 1265 TagAxleLoad_UB 7;
BA_ "GenSigMaxLatency" SG_ 1265 TagAxleLoad_UB 250;
BA_ "GenSigCycleTime" SG_ 1265 YearUTC 100;
BA_ "GenSigCycleTimeActive" SG_ 1265 YearUTC 100;
BA_ "GenSigStartValue" SG_ 1265 YearUTC 255;
BA_ "GenSigMaxLatency" SG_ 1265 YearUTC 250;
BA_ "SeToolAncestorID_SIGNAL" SG_ 1265 YearUTC "x0000001D0412FACB";
BA_ "SeToolItemID_SIGNAL" SG_ 1265 YearUTC "x0000001D041EBCEF";
BA_ "SeToolName_SIGNAL" SG_ 1265 YearUTC "YearUTC";
BA_ "SeToolVersion_SIGNAL" SG_ 1265 YearUTC "2";
BA_ "GenSigCycleTime" SG_ 1265 TertiaryDriveAxleLoad 100;
BA_ "GenSigCycleTimeActive" SG_ 1265 TertiaryDriveAxleLoad 100;
BA_ "GenSigStartValue" SG_ 1265 TertiaryDriveAxleLoad 65535;
BA_ "NeedsUpdateBit" SG_ 1265 TertiaryDriveAxleLoad 1;
BA_ "GenSigCycleTime" SG_ 1265 SecondsUTC 100;
BA_ "GenSigCycleTimeActive" SG_ 1265 SecondsUTC 100;
BA_ "GenSigStartValue" SG_ 1265 SecondsUTC 255;
BA_ "GenSigMaxLatency" SG_ 1265 SecondsUTC 250;
BA_ "SeToolAncestorID_SIGNAL" SG_ 1265 SecondsUTC "x0000001D0412FABE";
BA_ "SeToolItemID_SIGNAL" SG_ 1265 SecondsUTC "x0000001D041EBD32";
BA_ "SeToolName_SIGNAL" SG_ 1265 SecondsUTC "SecondsUTC";
BA_ "SeToolVersion_SIGNAL" SG_ 1265 SecondsUTC "2";
BA_ "GenSigCycleTime" SG_ 1265 Trailer1GeometricData_Index 100;
BA_ "GenSigCycleTimeActive" SG_ 1265 Trailer1GeometricData_Index 100;
BA_ "GenSigStartValue" SG_ 1265 Trailer1GeometricData_Index 255;
BA_ "GenSigMaxLatency" SG_ 1265 Trailer1GeometricData_Index 250;
BA_ "GenSigSendType" SG_ 1265 DriveAxleLoad_UB 7;
BA_ "GenSigMaxLatency" SG_ 1265 DriveAxleLoad_UB 250;
BA_ "GenSigCycleTime" SG_ 1265 HoursUTC 100;
BA_ "GenSigCycleTimeActive" SG_ 1265 HoursUTC 100;
BA_ "GenSigStartValue" SG_ 1265 HoursUTC 255;
BA_ "GenSigMaxLatency" SG_ 1265 HoursUTC 250;
BA_ "SeToolAncestorID_SIGNAL" SG_ 1265 HoursUTC "x0000001D0412FAC2";
BA_ "SeToolItemID_SIGNAL" SG_ 1265 HoursUTC "x0000001D041EBD20";
BA_ "SeToolName_SIGNAL" SG_ 1265 HoursUTC "HoursUTC";
BA_ "SeToolVersion_SIGNAL" SG_ 1265 HoursUTC "2";
BA_ "GenSigCycleTime" SG_ 1265 FrontAxle2Load 100;
BA_ "GenSigCycleTimeActive" SG_ 1265 FrontAxle2Load 100;
BA_ "GenSigStartValue" SG_ 1265 FrontAxle2Load 65535;
BA_ "GenSigMaxLatency" SG_ 1265 FrontAxle2Load 250;
BA_ "NeedsUpdateBit" SG_ 1265 FrontAxle2Load 1;
BA_ "SeToolAncestorID_SIGNAL" SG_ 1265 FrontAxle2Load "x0000001D0412EB1E";
BA_ "SeToolItemID_SIGNAL" SG_ 1265 FrontAxle2Load "x0000001D04274C69";
BA_ "SeToolName_SIGNAL" SG_ 1265 FrontAxle2Load "FrontAxle2Load";
BA_ "SeToolVersion_SIGNAL" SG_ 1265 FrontAxle2Load "3";
BA_ "GenSigCycleTime" SG_ 1265 MonthUTC 100;
BA_ "GenSigCycleTimeActive" SG_ 1265 MonthUTC 100;
BA_ "GenSigStartValue" SG_ 1265 MonthUTC 255;
BA_ "GenSigMaxLatency" SG_ 1265 MonthUTC 250;
BA_ "SeToolAncestorID_SIGNAL" SG_ 1265 MonthUTC "x0000001D0412FAC9";
BA_ "SeToolItemID_SIGNAL" SG_ 1265 MonthUTC "x0000001D041EBD16";
BA_ "SeToolName_SIGNAL" SG_ 1265 MonthUTC "MonthUTC";
BA_ "SeToolVersion_SIGNAL" SG_ 1265 MonthUTC "2";
BA_ "GenSigCycleTime" SG_ 1265 Trailer5GeometricData_Index 100;
BA_ "GenSigCycleTimeActive" SG_ 1265 Trailer5GeometricData_Index 100;
BA_ "GenSigStartValue" SG_ 1265 Trailer5GeometricData_Index 255;
BA_ "GenSigMaxLatency" SG_ 1265 Trailer5GeometricData_Index 250;
BA_ "GenSigSendType" SG_ 1265 FrontAxle1Load_UB 7;
BA_ "GenSigMaxLatency" SG_ 1265 FrontAxle1Load_UB 250;
BA_ "GenSigCycleTime" SG_ 1265 Trailer3GeometricData_Content 100;
BA_ "GenSigCycleTimeActive" SG_ 1265 Trailer3GeometricData_Content 100;
BA_ "GenSigStartValue" SG_ 1265 Trailer3GeometricData_Content 255;
BA_ "GenSigMaxLatency" SG_ 1265 Trailer3GeometricData_Content 250;
BA_ "GenSigCycleTime" SG_ 1265 Trailer5GeometricData_Content 100;
BA_ "GenSigCycleTimeActive" SG_ 1265 Trailer5GeometricData_Content 100;
BA_ "GenSigStartValue" SG_ 1265 Trailer5GeometricData_Content 255;
BA_ "GenSigMaxLatency" SG_ 1265 Trailer5GeometricData_Content 250;
BA_ "GenSigCycleTime" SG_ 1265 TagAxleLoad 100;
BA_ "GenSigCycleTimeActive" SG_ 1265 TagAxleLoad 100;
BA_ "GenSigStartValue" SG_ 1265 TagAxleLoad 65535;
BA_ "GenSigMaxLatency" SG_ 1265 TagAxleLoad 250;
BA_ "NeedsUpdateBit" SG_ 1265 TagAxleLoad 1;
BA_ "SeToolAncestorID_SIGNAL" SG_ 1265 TagAxleLoad "x0000001D0412EB1E";
BA_ "SeToolItemID_SIGNAL" SG_ 1265 TagAxleLoad "x0000001D04274C69";
BA_ "SeToolName_SIGNAL" SG_ 1265 TagAxleLoad "TagAxleLoad";
BA_ "SeToolVersion_SIGNAL" SG_ 1265 TagAxleLoad "3";
BA_ "GenSigCycleTime" SG_ 1265 AmbientAirTemperature 100;
BA_ "GenSigCycleTimeActive" SG_ 1265 AmbientAirTemperature 100;
BA_ "GenSigStartValue" SG_ 1265 AmbientAirTemperature 65535;
BA_ "GenSigMaxLatency" SG_ 1265 AmbientAirTemperature 250;
BA_ "SeToolAncestorID_SIGNAL" SG_ 1265 AmbientAirTemperature "x0000001D040FEBC8";
BA_ "SeToolItemID_SIGNAL" SG_ 1265 AmbientAirTemperature "x0000001D040FEBC8";
BA_ "SeToolName_SIGNAL" SG_ 1265 AmbientAirTemperature "AmbientAirTemperature";
BA_ "SeToolVersion_SIGNAL" SG_ 1265 AmbientAirTemperature "1";
BA_ "GenSigCycleTime" SG_ 1265 Trailer4GeometricData_Index 100;
BA_ "GenSigCycleTimeActive" SG_ 1265 Trailer4GeometricData_Index 100;
BA_ "GenSigStartValue" SG_ 1265 Trailer4GeometricData_Index 255;
BA_ "GenSigMaxLatency" SG_ 1265 Trailer4GeometricData_Index 250;
BA_ "GenSigSendType" SG_ 1265 SecondaryDriveAxleLoad_UB 7;
BA_ "GenSigMaxLatency" SG_ 1265 SecondaryDriveAxleLoad_UB 250;
BA_ "GenSigCycleTime" SG_ 1265 Trailer2GeometricData_Index 100;
BA_ "GenSigCycleTimeActive" SG_ 1265 Trailer2GeometricData_Index 100;
BA_ "GenSigStartValue" SG_ 1265 Trailer2GeometricData_Index 255;
BA_ "GenSigMaxLatency" SG_ 1265 Trailer2GeometricData_Index 250;
BA_ "GenSigCycleTime" SG_ 1265 SecondaryDriveAxleLoad 100;
BA_ "GenSigCycleTimeActive" SG_ 1265 SecondaryDriveAxleLoad 100;
BA_ "GenSigStartValue" SG_ 1265 SecondaryDriveAxleLoad 65535;
BA_ "GenSigMaxLatency" SG_ 1265 SecondaryDriveAxleLoad 250;
BA_ "NeedsUpdateBit" SG_ 1265 SecondaryDriveAxleLoad 1;
BA_ "SeToolAncestorID_SIGNAL" SG_ 1265 SecondaryDriveAxleLoad "x0000001D0412EB1E";
BA_ "SeToolItemID_SIGNAL" SG_ 1265 SecondaryDriveAxleLoad "x0000001D04274C69";
BA_ "SeToolName_SIGNAL" SG_ 1265 SecondaryDriveAxleLoad "SecondaryDriveAxleLoad";
BA_ "SeToolVersion_SIGNAL" SG_ 1265 SecondaryDriveAxleLoad "3";
BA_ "GenSigCycleTime" SG_ 1265 BendingAngle 100;
BA_ "GenSigCycleTimeActive" SG_ 1265 BendingAngle 100;
BA_ "GenSigStartValue" SG_ 1265 BendingAngle 255;
BA_ "GenSigSendType" SG_ 1265 PusherAxleLoad_UB 7;
BA_ "GenSigMaxLatency" SG_ 1265 PusherAxleLoad_UB 250;
BA_ "GenSigCycleTime" SG_ 1265 Trailer3GeometricData_Index 100;
BA_ "GenSigCycleTimeActive" SG_ 1265 Trailer3GeometricData_Index 100;
BA_ "GenSigStartValue" SG_ 1265 Trailer3GeometricData_Index 255;
BA_ "GenSigMaxLatency" SG_ 1265 Trailer3GeometricData_Index 250;
BA_ "GenSigCycleTime" SG_ 929 Trailer2LiftAxle1Pos 100;
BA_ "GenSigCycleTimeActive" SG_ 929 Trailer2LiftAxle1Pos 100;
BA_ "GenSigStartValue" SG_ 929 Trailer2LiftAxle1Pos 3;
BA_ "GenSigMaxLatency" SG_ 929 Trailer2LiftAxle1Pos 100;
BA_ "GenSigCycleTime" SG_ 929 TimeSynchStat_DACU 100;
BA_ "GenSigCycleTimeActive" SG_ 929 TimeSynchStat_DACU 100;
BA_ "GenSigCycleTime" SG_ 929 Trailer1LiftAxle1Pos 100;
BA_ "GenSigCycleTimeActive" SG_ 929 Trailer1LiftAxle1Pos 100;
BA_ "GenSigStartValue" SG_ 929 Trailer1LiftAxle1Pos 3;
BA_ "GenSigMaxLatency" SG_ 929 Trailer1LiftAxle1Pos 100;
BA_ "GenSigCycleTime" SG_ 929 Trailer5LiftAxle1Pos 100;
BA_ "GenSigCycleTimeActive" SG_ 929 Trailer5LiftAxle1Pos 100;
BA_ "GenSigStartValue" SG_ 929 Trailer5LiftAxle1Pos 3;
BA_ "GenSigMaxLatency" SG_ 929 Trailer5LiftAxle1Pos 100;
BA_ "GenSigCycleTime" SG_ 929 Trailer2LiftAxle2Pos 100;
BA_ "GenSigCycleTimeActive" SG_ 929 Trailer2LiftAxle2Pos 100;
BA_ "GenSigStartValue" SG_ 929 Trailer2LiftAxle2Pos 3;
BA_ "GenSigMaxLatency" SG_ 929 Trailer2LiftAxle2Pos 100;
BA_ "GenSigCycleTime" SG_ 929 TrailersConnected 100;
BA_ "GenSigCycleTimeActive" SG_ 929 TrailersConnected 100;
BA_ "GenSigStartValue" SG_ 929 TrailersConnected 7;
BA_ "GenSigMaxLatency" SG_ 929 TrailersConnected 100;
BA_ "GenSigCycleTime" SG_ 929 Trailer4LiftAxle2Pos 100;
BA_ "GenSigCycleTimeActive" SG_ 929 Trailer4LiftAxle2Pos 100;
BA_ "GenSigStartValue" SG_ 929 Trailer4LiftAxle2Pos 3;
BA_ "GenSigMaxLatency" SG_ 929 Trailer4LiftAxle2Pos 100;
BA_ "GenSigCycleTime" SG_ 929 Trailer1LiftAxle2Pos 100;
BA_ "GenSigCycleTimeActive" SG_ 929 Trailer1LiftAxle2Pos 100;
BA_ "GenSigStartValue" SG_ 929 Trailer1LiftAxle2Pos 3;
BA_ "GenSigMaxLatency" SG_ 929 Trailer1LiftAxle2Pos 100;
BA_ "GenSigCycleTime" SG_ 929 TrailerWithoutABS 100;
BA_ "GenSigCycleTimeActive" SG_ 929 TrailerWithoutABS 100;
BA_ "GenSigStartValue" SG_ 929 TrailerWithoutABS 3;
BA_ "SeToolAncestorID_SIGNAL" SG_ 929 TrailerWithoutABS "x0000001D0410CF7C";
BA_ "SeToolItemID_SIGNAL" SG_ 929 TrailerWithoutABS "x0000001D0410CF7C";
BA_ "SeToolName_SIGNAL" SG_ 929 TrailerWithoutABS "TrailerWithoutABS";
BA_ "SeToolVersion_SIGNAL" SG_ 929 TrailerWithoutABS "1";
BA_ "GenSigCycleTime" SG_ 929 Trailer5LiftAxle2Pos 100;
BA_ "GenSigCycleTimeActive" SG_ 929 Trailer5LiftAxle2Pos 100;
BA_ "GenSigStartValue" SG_ 929 Trailer5LiftAxle2Pos 3;
BA_ "GenSigMaxLatency" SG_ 929 Trailer5LiftAxle2Pos 100;
BA_ "GenSigCycleTime" SG_ 929 Trailer4LiftAxle1Pos 100;
BA_ "GenSigCycleTimeActive" SG_ 929 Trailer4LiftAxle1Pos 100;
BA_ "GenSigStartValue" SG_ 929 Trailer4LiftAxle1Pos 3;
BA_ "GenSigMaxLatency" SG_ 929 Trailer4LiftAxle1Pos 100;
BA_ "GenSigCycleTime" SG_ 929 Trailer3LiftAxle2Pos 100;
BA_ "GenSigCycleTimeActive" SG_ 929 Trailer3LiftAxle2Pos 100;
BA_ "GenSigStartValue" SG_ 929 Trailer3LiftAxle2Pos 3;
BA_ "GenSigMaxLatency" SG_ 929 Trailer3LiftAxle2Pos 100;
BA_ "GenSigCycleTime" SG_ 929 Trailer3LiftAxle1Pos 100;
BA_ "GenSigCycleTimeActive" SG_ 929 Trailer3LiftAxle1Pos 100;
BA_ "GenSigStartValue" SG_ 929 Trailer3LiftAxle1Pos 3;
BA_ "GenSigMaxLatency" SG_ 929 Trailer3LiftAxle1Pos 100;
BA_ "GenSigCycleTime" SG_ 929 SRadarLoggingTrigger 100;
BA_ "GenSigCycleTimeActive" SG_ 929 SRadarLoggingTrigger 100;
BA_ "GenSigStartValue" SG_ 929 SRadarLoggingTrigger 7;
BA_ "GenSigSendType" SG_ 929 TrailerWithoutABS_UB 7;
BA_ "GenSigCycleTime" SG_ 547 LiftAxle1PositionStatus 100;
BA_ "GenSigCycleTimeActive" SG_ 547 LiftAxle1PositionStatus 100;
BA_ "GenSigStartValue" SG_ 547 LiftAxle1PositionStatus 7;
BA_ "GenSigMaxLatency" SG_ 547 LiftAxle1PositionStatus 20;
BA_ "SeToolAncestorID_SIGNAL" SG_ 547 LiftAxle1PositionStatus "x0000001D04131A08";
BA_ "SeToolItemID_SIGNAL" SG_ 547 LiftAxle1PositionStatus "x0000001D0423C412";
BA_ "SeToolName_SIGNAL" SG_ 547 LiftAxle1PositionStatus "LiftAxle1PositionStatus";
BA_ "SeToolVersion_SIGNAL" SG_ 547 LiftAxle1PositionStatus "2";
BA_ "GenSigCycleTime" SG_ 547 VehicleMode 100;
BA_ "GenSigCycleTimeActive" SG_ 547 VehicleMode 100;
BA_ "GenSigStartValue" SG_ 547 VehicleMode 15;
BA_ "GenSigMaxLatency" SG_ 547 VehicleMode 20;
BA_ "NeedsUpdateBit" SG_ 547 VehicleMode 1;
BA_ "GenSigCycleTime" SG_ 547 TrailerConnected 100;
BA_ "GenSigCycleTimeActive" SG_ 547 TrailerConnected 100;
BA_ "GenSigStartValue" SG_ 547 TrailerConnected 3;
BA_ "GenSigMaxLatency" SG_ 547 TrailerConnected 20;
BA_ "GenSigCycleTime" SG_ 547 SideSensorPowerMode 100;
BA_ "GenSigCycleTimeActive" SG_ 547 SideSensorPowerMode 100;
BA_ "GenSigStartValue" SG_ 547 SideSensorPowerMode 3;
BA_ "GenSigMaxLatency" SG_ 547 SideSensorPowerMode 20;
BA_ "GenSigSendType" SG_ 547 WiperModeStatus_UB 7;
BA_ "GenSigMaxLatency" SG_ 547 WiperModeStatus_UB 20;
BA_ "GenSigSendType" SG_ 547 VehicleMode_UB 7;
BA_ "GenSigMaxLatency" SG_ 547 VehicleMode_UB 20;
BA_ "GenSigCycleTime" SG_ 547 FrontCameraDynRoll 100;
BA_ "GenSigCycleTimeActive" SG_ 547 FrontCameraDynRoll 100;
BA_ "GenSigStartValue" SG_ 547 FrontCameraDynRoll 255;
BA_ "GenSigCycleTime" SG_ 547 LiftAxle2PositionStatus 100;
BA_ "GenSigCycleTimeActive" SG_ 547 LiftAxle2PositionStatus 100;
BA_ "GenSigStartValue" SG_ 547 LiftAxle2PositionStatus 7;
BA_ "GenSigMaxLatency" SG_ 547 LiftAxle2PositionStatus 20;
BA_ "SeToolAncestorID_SIGNAL" SG_ 547 LiftAxle2PositionStatus "x0000001D04131A0A";
BA_ "SeToolItemID_SIGNAL" SG_ 547 LiftAxle2PositionStatus "x0000001D04295880";
BA_ "SeToolName_SIGNAL" SG_ 547 LiftAxle2PositionStatus "LiftAxle2PositionStatus";
BA_ "SeToolVersion_SIGNAL" SG_ 547 LiftAxle2PositionStatus "3";
BA_ "GenSigCycleTime" SG_ 547 FrontCameraDynPitch 100;
BA_ "GenSigCycleTimeActive" SG_ 547 FrontCameraDynPitch 100;
BA_ "GenSigStartValue" SG_ 547 FrontCameraDynPitch 255;
BA_ "GenSigCycleTime" SG_ 547 WiperModeStatus 100;
BA_ "GenSigCycleTimeActive" SG_ 547 WiperModeStatus 100;
BA_ "GenSigStartValue" SG_ 547 WiperModeStatus 7;
BA_ "GenSigMaxLatency" SG_ 547 WiperModeStatus 20;
BA_ "SeToolAncestorID_SIGNAL" SG_ 547 WiperModeStatus "x0000001D0410D271";
BA_ "SeToolItemID_SIGNAL" SG_ 547 WiperModeStatus "x0000001D0410D271";
BA_ "SeToolName_SIGNAL" SG_ 547 WiperModeStatus "WiperModeStatus";
BA_ "SeToolVersion_SIGNAL" SG_ 547 WiperModeStatus "1";
BA_ "GenSigCycleTime" SG_ 1552 DACUSwVersion_Substring3 100;
BA_ "GenSigCycleTimeActive" SG_ 1552 DACUSwVersion_Substring3 100;
BA_ "GenSigCycleTime" SG_ 1552 DACUSwVersion_Substring1 100;
BA_ "GenSigCycleTimeActive" SG_ 1552 DACUSwVersion_Substring1 100;
BA_ "GenSigCycleTime" SG_ 1552 DACUSwVersion_Substring4 100;
BA_ "GenSigCycleTimeActive" SG_ 1552 DACUSwVersion_Substring4 100;
BA_ "GenSigCycleTime" SG_ 1552 DACUSwVersion_Substring7 100;
BA_ "GenSigCycleTimeActive" SG_ 1552 DACUSwVersion_Substring7 100;
BA_ "GenSigCycleTime" SG_ 1552 DACUSwVersion_Substring0 100;
BA_ "GenSigCycleTimeActive" SG_ 1552 DACUSwVersion_Substring0 100;
BA_ "GenSigCycleTime" SG_ 1552 DACUSwVersion_Substring6 100;
BA_ "GenSigCycleTimeActive" SG_ 1552 DACUSwVersion_Substring6 100;
BA_ "GenSigCycleTime" SG_ 1552 DACUSwVersion_Substring2 100;
BA_ "GenSigCycleTimeActive" SG_ 1552 DACUSwVersion_Substring2 100;
BA_ "GenSigCycleTime" SG_ 1552 DACUSwVersion_Substring5 100;
BA_ "GenSigCycleTimeActive" SG_ 1552 DACUSwVersion_Substring5 100;
BA_REL_ "GenSigFirstTimeoutTime" BU_SG_REL_ SR_LF SG_ 277 EgoMotionRaw_RAxleLeftWSpeed 3000;
BA_REL_ "GenSigTimeoutTime" BU_SG_REL_ SR_LF SG_ 277 EgoMotionRaw_RAxleLeftWSpeed 100;
BA_REL_ "GenSigFirstTimeoutTime" BU_SG_REL_ SR_LR SG_ 277 EgoMotionRaw_RAxleLeftWSpeed 3000;
BA_REL_ "GenSigTimeoutTime" BU_SG_REL_ SR_LR SG_ 277 EgoMotionRaw_RAxleLeftWSpeed 100;
BA_REL_ "GenSigFirstTimeoutTime" BU_SG_REL_ SR_RR SG_ 277 EgoMotionRaw_RAxleLeftWSpeed 3000;
BA_REL_ "GenSigTimeoutTime" BU_SG_REL_ SR_RR SG_ 277 EgoMotionRaw_RAxleLeftWSpeed 100;
BA_REL_ "GenSigFirstTimeoutTime" BU_SG_REL_ SR_RF SG_ 277 EgoMotionRaw_RAxleLeftWSpeed 3000;
BA_REL_ "GenSigTimeoutTime" BU_SG_REL_ SR_RF SG_ 277 EgoMotionRaw_RAxleLeftWSpeed 100;
BA_REL_ "GenSigFirstTimeoutTime" BU_SG_REL_ SR_RF SG_ 277 EgoMotionRaw_RelLvlRrAxleLeft 3000;
BA_REL_ "GenSigTimeoutTime" BU_SG_REL_ SR_RF SG_ 277 EgoMotionRaw_RelLvlRrAxleLeft 100;
BA_REL_ "GenSigFirstTimeoutTime" BU_SG_REL_ SR_LR SG_ 277 EgoMotionRaw_RelLvlRrAxleLeft 3000;
BA_REL_ "GenSigTimeoutTime" BU_SG_REL_ SR_LR SG_ 277 EgoMotionRaw_RelLvlRrAxleLeft 100;
BA_REL_ "GenSigFirstTimeoutTime" BU_SG_REL_ SR_LF SG_ 277 EgoMotionRaw_RelLvlRrAxleLeft 3000;
BA_REL_ "GenSigTimeoutTime" BU_SG_REL_ SR_LF SG_ 277 EgoMotionRaw_RelLvlRrAxleLeft 100;
BA_REL_ "GenSigFirstTimeoutTime" BU_SG_REL_ SR_RR SG_ 277 EgoMotionRaw_RelLvlRrAxleLeft 3000;
BA_REL_ "GenSigTimeoutTime" BU_SG_REL_ SR_RR SG_ 277 EgoMotionRaw_RelLvlRrAxleLeft 100;
BA_REL_ "GenSigFirstTimeoutTime" BU_SG_REL_ SR_LF SG_ 277 EgoMotionRaw_RelLvlFrAxleRight 3000;
BA_REL_ "GenSigTimeoutTime" BU_SG_REL_ SR_LF SG_ 277 EgoMotionRaw_RelLvlFrAxleRight 100;
BA_REL_ "GenSigFirstTimeoutTime" BU_SG_REL_ SR_RF SG_ 277 EgoMotionRaw_RelLvlFrAxleRight 3000;
BA_REL_ "GenSigTimeoutTime" BU_SG_REL_ SR_RF SG_ 277 EgoMotionRaw_RelLvlFrAxleRight 100;
BA_REL_ "GenSigFirstTimeoutTime" BU_SG_REL_ SR_LR SG_ 277 EgoMotionRaw_RelLvlFrAxleRight 3000;
BA_REL_ "GenSigTimeoutTime" BU_SG_REL_ SR_LR SG_ 277 EgoMotionRaw_RelLvlFrAxleRight 100;
BA_REL_ "GenSigFirstTimeoutTime" BU_SG_REL_ SR_RR SG_ 277 EgoMotionRaw_RelLvlFrAxleRight 3000;
BA_REL_ "GenSigTimeoutTime" BU_SG_REL_ SR_RR SG_ 277 EgoMotionRaw_RelLvlFrAxleRight 100;
BA_REL_ "GenSigFirstTimeoutTime" BU_SG_REL_ SR_RF SG_ 277 EgoMotionRaw_AccPedalPos 3000;
BA_REL_ "GenSigTimeoutTime" BU_SG_REL_ SR_RF SG_ 277 EgoMotionRaw_AccPedalPos 100;
BA_REL_ "GenSigFirstTimeoutTime" BU_SG_REL_ SR_LF SG_ 277 EgoMotionRaw_AccPedalPos 3000;
BA_REL_ "GenSigTimeoutTime" BU_SG_REL_ SR_LF SG_ 277 EgoMotionRaw_AccPedalPos 100;
BA_REL_ "GenSigFirstTimeoutTime" BU_SG_REL_ SR_RR SG_ 277 EgoMotionRaw_AccPedalPos 3000;
BA_REL_ "GenSigTimeoutTime" BU_SG_REL_ SR_RR SG_ 277 EgoMotionRaw_AccPedalPos 100;
BA_REL_ "GenSigFirstTimeoutTime" BU_SG_REL_ SR_LR SG_ 277 EgoMotionRaw_AccPedalPos 3000;
BA_REL_ "GenSigTimeoutTime" BU_SG_REL_ SR_LR SG_ 277 EgoMotionRaw_AccPedalPos 100;
BA_REL_ "GenSigFirstTimeoutTime" BU_SG_REL_ SR_LR SG_ 277 EgoMotionRaw_BrakePedalPosition 3000;
BA_REL_ "GenSigTimeoutTime" BU_SG_REL_ SR_LR SG_ 277 EgoMotionRaw_BrakePedalPosition 100;
BA_REL_ "GenSigFirstTimeoutTime" BU_SG_REL_ SR_RR SG_ 277 EgoMotionRaw_BrakePedalPosition 3000;
BA_REL_ "GenSigTimeoutTime" BU_SG_REL_ SR_RR SG_ 277 EgoMotionRaw_BrakePedalPosition 100;
BA_REL_ "GenSigFirstTimeoutTime" BU_SG_REL_ SR_RF SG_ 277 EgoMotionRaw_BrakePedalPosition 3000;
BA_REL_ "GenSigTimeoutTime" BU_SG_REL_ SR_RF SG_ 277 EgoMotionRaw_BrakePedalPosition 100;
BA_REL_ "GenSigFirstTimeoutTime" BU_SG_REL_ SR_LF SG_ 277 EgoMotionRaw_BrakePedalPosition 3000;
BA_REL_ "GenSigTimeoutTime" BU_SG_REL_ SR_LF SG_ 277 EgoMotionRaw_BrakePedalPosition 100;
BA_REL_ "GenSigFirstTimeoutTime" BU_SG_REL_ SR_LF SG_ 277 EgoMotionRaw_FrAxleLeftWSpeed 3000;
BA_REL_ "GenSigTimeoutTime" BU_SG_REL_ SR_LF SG_ 277 EgoMotionRaw_FrAxleLeftWSpeed 100;
BA_REL_ "GenSigFirstTimeoutTime" BU_SG_REL_ SR_RR SG_ 277 EgoMotionRaw_FrAxleLeftWSpeed 3000;
BA_REL_ "GenSigTimeoutTime" BU_SG_REL_ SR_RR SG_ 277 EgoMotionRaw_FrAxleLeftWSpeed 100;
BA_REL_ "GenSigFirstTimeoutTime" BU_SG_REL_ SR_LR SG_ 277 EgoMotionRaw_FrAxleLeftWSpeed 3000;
BA_REL_ "GenSigTimeoutTime" BU_SG_REL_ SR_LR SG_ 277 EgoMotionRaw_FrAxleLeftWSpeed 100;
BA_REL_ "GenSigFirstTimeoutTime" BU_SG_REL_ SR_RF SG_ 277 EgoMotionRaw_FrAxleLeftWSpeed 3000;
BA_REL_ "GenSigTimeoutTime" BU_SG_REL_ SR_RF SG_ 277 EgoMotionRaw_FrAxleLeftWSpeed 100;
BA_REL_ "GenSigFirstTimeoutTime" BU_SG_REL_ SR_LF SG_ 277 EgoMotionRaw_FrontWheelAngle 3000;
BA_REL_ "GenSigTimeoutTime" BU_SG_REL_ SR_LF SG_ 277 EgoMotionRaw_FrontWheelAngle 100;
BA_REL_ "GenSigFirstTimeoutTime" BU_SG_REL_ SR_LR SG_ 277 EgoMotionRaw_FrontWheelAngle 3000;
BA_REL_ "GenSigTimeoutTime" BU_SG_REL_ SR_LR SG_ 277 EgoMotionRaw_FrontWheelAngle 100;
BA_REL_ "GenSigFirstTimeoutTime" BU_SG_REL_ SR_RF SG_ 277 EgoMotionRaw_FrontWheelAngle 3000;
BA_REL_ "GenSigTimeoutTime" BU_SG_REL_ SR_RF SG_ 277 EgoMotionRaw_FrontWheelAngle 100;
BA_REL_ "GenSigFirstTimeoutTime" BU_SG_REL_ SR_RR SG_ 277 EgoMotionRaw_FrontWheelAngle 3000;
BA_REL_ "GenSigTimeoutTime" BU_SG_REL_ SR_RR SG_ 277 EgoMotionRaw_FrontWheelAngle 100;
BA_REL_ "GenSigFirstTimeoutTime" BU_SG_REL_ SR_RR SG_ 277 EgoMotionRaw_ASREngineA 3000;
BA_REL_ "GenSigTimeoutTime" BU_SG_REL_ SR_RR SG_ 277 EgoMotionRaw_ASREngineA 100;
BA_REL_ "GenSigFirstTimeoutTime" BU_SG_REL_ SR_RF SG_ 277 EgoMotionRaw_ASREngineA 3000;
BA_REL_ "GenSigTimeoutTime" BU_SG_REL_ SR_RF SG_ 277 EgoMotionRaw_ASREngineA 100;
BA_REL_ "GenSigFirstTimeoutTime" BU_SG_REL_ SR_LF SG_ 277 EgoMotionRaw_ASREngineA 3000;
BA_REL_ "GenSigTimeoutTime" BU_SG_REL_ SR_LF SG_ 277 EgoMotionRaw_ASREngineA 100;
BA_REL_ "GenSigFirstTimeoutTime" BU_SG_REL_ SR_LR SG_ 277 EgoMotionRaw_ASREngineA 3000;
BA_REL_ "GenSigTimeoutTime" BU_SG_REL_ SR_LR SG_ 277 EgoMotionRaw_ASREngineA 100;
BA_REL_ "GenSigFirstTimeoutTime" BU_SG_REL_ SR_LR SG_ 277 EgoMotionRaw_ASRBrakeA 3000;
BA_REL_ "GenSigTimeoutTime" BU_SG_REL_ SR_LR SG_ 277 EgoMotionRaw_ASRBrakeA 100;
BA_REL_ "GenSigFirstTimeoutTime" BU_SG_REL_ SR_RR SG_ 277 EgoMotionRaw_ASRBrakeA 3000;
BA_REL_ "GenSigTimeoutTime" BU_SG_REL_ SR_RR SG_ 277 EgoMotionRaw_ASRBrakeA 100;
BA_REL_ "GenSigFirstTimeoutTime" BU_SG_REL_ SR_RF SG_ 277 EgoMotionRaw_ASRBrakeA 3000;
BA_REL_ "GenSigTimeoutTime" BU_SG_REL_ SR_RF SG_ 277 EgoMotionRaw_ASRBrakeA 100;
BA_REL_ "GenSigFirstTimeoutTime" BU_SG_REL_ SR_LF SG_ 277 EgoMotionRaw_ASRBrakeA 3000;
BA_REL_ "GenSigTimeoutTime" BU_SG_REL_ SR_LF SG_ 277 EgoMotionRaw_ASRBrakeA 100;
BA_REL_ "GenSigFirstTimeoutTime" BU_SG_REL_ SR_RR SG_ 277 EgoMotionRaw_ABSActive 3000;
BA_REL_ "GenSigTimeoutTime" BU_SG_REL_ SR_RR SG_ 277 EgoMotionRaw_ABSActive 100;
BA_REL_ "GenSigFirstTimeoutTime" BU_SG_REL_ SR_LR SG_ 277 EgoMotionRaw_ABSActive 3000;
BA_REL_ "GenSigTimeoutTime" BU_SG_REL_ SR_LR SG_ 277 EgoMotionRaw_ABSActive 100;
BA_REL_ "GenSigFirstTimeoutTime" BU_SG_REL_ SR_RF SG_ 277 EgoMotionRaw_ABSActive 3000;
BA_REL_ "GenSigTimeoutTime" BU_SG_REL_ SR_RF SG_ 277 EgoMotionRaw_ABSActive 100;
BA_REL_ "GenSigFirstTimeoutTime" BU_SG_REL_ SR_LF SG_ 277 EgoMotionRaw_ABSActive 3000;
BA_REL_ "GenSigTimeoutTime" BU_SG_REL_ SR_LF SG_ 277 EgoMotionRaw_ABSActive 100;
BA_REL_ "GenSigFirstTimeoutTime" BU_SG_REL_ SR_LR SG_ 277 EgoMotionRaw_VDCFullyOperational 3000;
BA_REL_ "GenSigTimeoutTime" BU_SG_REL_ SR_LR SG_ 277 EgoMotionRaw_VDCFullyOperational 100;
BA_REL_ "GenSigFirstTimeoutTime" BU_SG_REL_ SR_RF SG_ 277 EgoMotionRaw_VDCFullyOperational 3000;
BA_REL_ "GenSigTimeoutTime" BU_SG_REL_ SR_RF SG_ 277 EgoMotionRaw_VDCFullyOperational 100;
BA_REL_ "GenSigFirstTimeoutTime" BU_SG_REL_ SR_RR SG_ 277 EgoMotionRaw_VDCFullyOperational 3000;
BA_REL_ "GenSigTimeoutTime" BU_SG_REL_ SR_RR SG_ 277 EgoMotionRaw_VDCFullyOperational 100;
BA_REL_ "GenSigFirstTimeoutTime" BU_SG_REL_ SR_LF SG_ 277 EgoMotionRaw_VDCFullyOperational 3000;
BA_REL_ "GenSigTimeoutTime" BU_SG_REL_ SR_LF SG_ 277 EgoMotionRaw_VDCFullyOperational 100;
BA_REL_ "GenSigFirstTimeoutTime" BU_SG_REL_ SR_LF SG_ 277 EgoMotionRaw_ROPEngineActive 3000;
BA_REL_ "GenSigTimeoutTime" BU_SG_REL_ SR_LF SG_ 277 EgoMotionRaw_ROPEngineActive 100;
BA_REL_ "GenSigFirstTimeoutTime" BU_SG_REL_ SR_LR SG_ 277 EgoMotionRaw_ROPEngineActive 3000;
BA_REL_ "GenSigTimeoutTime" BU_SG_REL_ SR_LR SG_ 277 EgoMotionRaw_ROPEngineActive 100;
BA_REL_ "GenSigFirstTimeoutTime" BU_SG_REL_ SR_RR SG_ 277 EgoMotionRaw_ROPEngineActive 3000;
BA_REL_ "GenSigTimeoutTime" BU_SG_REL_ SR_RR SG_ 277 EgoMotionRaw_ROPEngineActive 100;
BA_REL_ "GenSigFirstTimeoutTime" BU_SG_REL_ SR_RF SG_ 277 EgoMotionRaw_ROPEngineActive 3000;
BA_REL_ "GenSigTimeoutTime" BU_SG_REL_ SR_RF SG_ 277 EgoMotionRaw_ROPEngineActive 100;
BA_REL_ "GenSigFirstTimeoutTime" BU_SG_REL_ SR_LR SG_ 277 EgoMotionRaw_YCBrakeActive 3000;
BA_REL_ "GenSigTimeoutTime" BU_SG_REL_ SR_LR SG_ 277 EgoMotionRaw_YCBrakeActive 100;
BA_REL_ "GenSigFirstTimeoutTime" BU_SG_REL_ SR_RF SG_ 277 EgoMotionRaw_YCBrakeActive 3000;
BA_REL_ "GenSigTimeoutTime" BU_SG_REL_ SR_RF SG_ 277 EgoMotionRaw_YCBrakeActive 100;
BA_REL_ "GenSigFirstTimeoutTime" BU_SG_REL_ SR_RR SG_ 277 EgoMotionRaw_YCBrakeActive 3000;
BA_REL_ "GenSigTimeoutTime" BU_SG_REL_ SR_RR SG_ 277 EgoMotionRaw_YCBrakeActive 100;
BA_REL_ "GenSigFirstTimeoutTime" BU_SG_REL_ SR_LF SG_ 277 EgoMotionRaw_YCBrakeActive 3000;
BA_REL_ "GenSigTimeoutTime" BU_SG_REL_ SR_LF SG_ 277 EgoMotionRaw_YCBrakeActive 100;
BA_REL_ "GenSigFirstTimeoutTime" BU_SG_REL_ SR_LF SG_ 277 EgoMotionRaw_GrossCombVehWeight 3000;
BA_REL_ "GenSigTimeoutTime" BU_SG_REL_ SR_LF SG_ 277 EgoMotionRaw_GrossCombVehWeight 100;
BA_REL_ "GenSigFirstTimeoutTime" BU_SG_REL_ SR_RF SG_ 277 EgoMotionRaw_GrossCombVehWeight 3000;
BA_REL_ "GenSigTimeoutTime" BU_SG_REL_ SR_RF SG_ 277 EgoMotionRaw_GrossCombVehWeight 100;
BA_REL_ "GenSigFirstTimeoutTime" BU_SG_REL_ SR_RR SG_ 277 EgoMotionRaw_GrossCombVehWeight 3000;
BA_REL_ "GenSigTimeoutTime" BU_SG_REL_ SR_RR SG_ 277 EgoMotionRaw_GrossCombVehWeight 100;
BA_REL_ "GenSigFirstTimeoutTime" BU_SG_REL_ SR_LR SG_ 277 EgoMotionRaw_GrossCombVehWeight 3000;
BA_REL_ "GenSigTimeoutTime" BU_SG_REL_ SR_LR SG_ 277 EgoMotionRaw_GrossCombVehWeight 100;
BA_REL_ "GenSigFirstTimeoutTime" BU_SG_REL_ SR_RF SG_ 277 EgoMotionRaw_RelLvlFrAxleLeft 3000;
BA_REL_ "GenSigTimeoutTime" BU_SG_REL_ SR_RF SG_ 277 EgoMotionRaw_RelLvlFrAxleLeft 100;
BA_REL_ "GenSigFirstTimeoutTime" BU_SG_REL_ SR_LF SG_ 277 EgoMotionRaw_RelLvlFrAxleLeft 3000;
BA_REL_ "GenSigTimeoutTime" BU_SG_REL_ SR_LF SG_ 277 EgoMotionRaw_RelLvlFrAxleLeft 100;
BA_REL_ "GenSigFirstTimeoutTime" BU_SG_REL_ SR_LR SG_ 277 EgoMotionRaw_RelLvlFrAxleLeft 3000;
BA_REL_ "GenSigTimeoutTime" BU_SG_REL_ SR_LR SG_ 277 EgoMotionRaw_RelLvlFrAxleLeft 100;
BA_REL_ "GenSigFirstTimeoutTime" BU_SG_REL_ SR_RR SG_ 277 EgoMotionRaw_RelLvlFrAxleLeft 3000;
BA_REL_ "GenSigTimeoutTime" BU_SG_REL_ SR_RR SG_ 277 EgoMotionRaw_RelLvlFrAxleLeft 100;
BA_REL_ "GenSigFirstTimeoutTime" BU_SG_REL_ SR_RF SG_ 277 EgoMotionRaw_Counter 3000;
BA_REL_ "GenSigTimeoutTime" BU_SG_REL_ SR_RF SG_ 277 EgoMotionRaw_Counter 100;
BA_REL_ "GenSigFirstTimeoutTime" BU_SG_REL_ SR_RR SG_ 277 EgoMotionRaw_Counter 3000;
BA_REL_ "GenSigTimeoutTime" BU_SG_REL_ SR_RR SG_ 277 EgoMotionRaw_Counter 100;
BA_REL_ "GenSigFirstTimeoutTime" BU_SG_REL_ SR_LR SG_ 277 EgoMotionRaw_Counter 3000;
BA_REL_ "GenSigTimeoutTime" BU_SG_REL_ SR_LR SG_ 277 EgoMotionRaw_Counter 100;
BA_REL_ "GenSigFirstTimeoutTime" BU_SG_REL_ SR_LF SG_ 277 EgoMotionRaw_Counter 3000;
BA_REL_ "GenSigTimeoutTime" BU_SG_REL_ SR_LF SG_ 277 EgoMotionRaw_Counter 100;
BA_REL_ "GenSigFirstTimeoutTime" BU_SG_REL_ SR_LF SG_ 277 EgoMotionRaw_RAxleRightWSpeed 3000;
BA_REL_ "GenSigTimeoutTime" BU_SG_REL_ SR_LF SG_ 277 EgoMotionRaw_RAxleRightWSpeed 100;
BA_REL_ "GenSigFirstTimeoutTime" BU_SG_REL_ SR_LR SG_ 277 EgoMotionRaw_RAxleRightWSpeed 3000;
BA_REL_ "GenSigTimeoutTime" BU_SG_REL_ SR_LR SG_ 277 EgoMotionRaw_RAxleRightWSpeed 100;
BA_REL_ "GenSigFirstTimeoutTime" BU_SG_REL_ SR_RF SG_ 277 EgoMotionRaw_RAxleRightWSpeed 3000;
BA_REL_ "GenSigTimeoutTime" BU_SG_REL_ SR_RF SG_ 277 EgoMotionRaw_RAxleRightWSpeed 100;
BA_REL_ "GenSigFirstTimeoutTime" BU_SG_REL_ SR_RR SG_ 277 EgoMotionRaw_RAxleRightWSpeed 3000;
BA_REL_ "GenSigTimeoutTime" BU_SG_REL_ SR_RR SG_ 277 EgoMotionRaw_RAxleRightWSpeed 100;
BA_REL_ "GenSigFirstTimeoutTime" BU_SG_REL_ SR_RF SG_ 277 EgoMotionRaw_TrailerConStatus 3000;
BA_REL_ "GenSigTimeoutTime" BU_SG_REL_ SR_RF SG_ 277 EgoMotionRaw_TrailerConStatus 100;
BA_REL_ "GenSigFirstTimeoutTime" BU_SG_REL_ SR_LR SG_ 277 EgoMotionRaw_TrailerConStatus 3000;
BA_REL_ "GenSigTimeoutTime" BU_SG_REL_ SR_LR SG_ 277 EgoMotionRaw_TrailerConStatus 100;
BA_REL_ "GenSigFirstTimeoutTime" BU_SG_REL_ SR_RR SG_ 277 EgoMotionRaw_TrailerConStatus 3000;
BA_REL_ "GenSigTimeoutTime" BU_SG_REL_ SR_RR SG_ 277 EgoMotionRaw_TrailerConStatus 100;
BA_REL_ "GenSigFirstTimeoutTime" BU_SG_REL_ SR_LF SG_ 277 EgoMotionRaw_TrailerConStatus 3000;
BA_REL_ "GenSigTimeoutTime" BU_SG_REL_ SR_LF SG_ 277 EgoMotionRaw_TrailerConStatus 100;
BA_REL_ "GenSigFirstTimeoutTime" BU_SG_REL_ SR_RF SG_ 277 EgoMotionRaw_FrAxleRightWSpeed 3000;
BA_REL_ "GenSigTimeoutTime" BU_SG_REL_ SR_RF SG_ 277 EgoMotionRaw_FrAxleRightWSpeed 100;
BA_REL_ "GenSigFirstTimeoutTime" BU_SG_REL_ SR_LR SG_ 277 EgoMotionRaw_FrAxleRightWSpeed 3000;
BA_REL_ "GenSigTimeoutTime" BU_SG_REL_ SR_LR SG_ 277 EgoMotionRaw_FrAxleRightWSpeed 100;
BA_REL_ "GenSigFirstTimeoutTime" BU_SG_REL_ SR_LF SG_ 277 EgoMotionRaw_FrAxleRightWSpeed 3000;
BA_REL_ "GenSigTimeoutTime" BU_SG_REL_ SR_LF SG_ 277 EgoMotionRaw_FrAxleRightWSpeed 100;
BA_REL_ "GenSigFirstTimeoutTime" BU_SG_REL_ SR_RR SG_ 277 EgoMotionRaw_FrAxleRightWSpeed 3000;
BA_REL_ "GenSigTimeoutTime" BU_SG_REL_ SR_RR SG_ 277 EgoMotionRaw_FrAxleRightWSpeed 100;
BA_REL_ "GenSigFirstTimeoutTime" BU_SG_REL_ SR_LF SG_ 277 EgoMotionRaw_SteeringWheelAngle 3000;
BA_REL_ "GenSigTimeoutTime" BU_SG_REL_ SR_LF SG_ 277 EgoMotionRaw_SteeringWheelAngle 100;
BA_REL_ "GenSigFirstTimeoutTime" BU_SG_REL_ SR_RF SG_ 277 EgoMotionRaw_SteeringWheelAngle 3000;
BA_REL_ "GenSigTimeoutTime" BU_SG_REL_ SR_RF SG_ 277 EgoMotionRaw_SteeringWheelAngle 100;
BA_REL_ "GenSigFirstTimeoutTime" BU_SG_REL_ SR_RR SG_ 277 EgoMotionRaw_SteeringWheelAngle 3000;
BA_REL_ "GenSigTimeoutTime" BU_SG_REL_ SR_RR SG_ 277 EgoMotionRaw_SteeringWheelAngle 100;
BA_REL_ "GenSigFirstTimeoutTime" BU_SG_REL_ SR_LR SG_ 277 EgoMotionRaw_SteeringWheelAngle 3000;
BA_REL_ "GenSigTimeoutTime" BU_SG_REL_ SR_LR SG_ 277 EgoMotionRaw_SteeringWheelAngle 100;
BA_REL_ "GenSigFirstTimeoutTime" BU_SG_REL_ SR_RF SG_ 277 EgoMotionRaw_ABSOp 3000;
BA_REL_ "GenSigTimeoutTime" BU_SG_REL_ SR_RF SG_ 277 EgoMotionRaw_ABSOp 100;
BA_REL_ "GenSigFirstTimeoutTime" BU_SG_REL_ SR_LR SG_ 277 EgoMotionRaw_ABSOp 3000;
BA_REL_ "GenSigTimeoutTime" BU_SG_REL_ SR_LR SG_ 277 EgoMotionRaw_ABSOp 100;
BA_REL_ "GenSigFirstTimeoutTime" BU_SG_REL_ SR_LF SG_ 277 EgoMotionRaw_ABSOp 3000;
BA_REL_ "GenSigTimeoutTime" BU_SG_REL_ SR_LF SG_ 277 EgoMotionRaw_ABSOp 100;
BA_REL_ "GenSigFirstTimeoutTime" BU_SG_REL_ SR_RR SG_ 277 EgoMotionRaw_ABSOp 3000;
BA_REL_ "GenSigTimeoutTime" BU_SG_REL_ SR_RR SG_ 277 EgoMotionRaw_ABSOp 100;
BA_REL_ "GenSigFirstTimeoutTime" BU_SG_REL_ SR_RR SG_ 277 EgoMotionRaw_CRC 3000;
BA_REL_ "GenSigTimeoutTime" BU_SG_REL_ SR_RR SG_ 277 EgoMotionRaw_CRC 100;
BA_REL_ "GenSigFirstTimeoutTime" BU_SG_REL_ SR_RF SG_ 277 EgoMotionRaw_CRC 3000;
BA_REL_ "GenSigTimeoutTime" BU_SG_REL_ SR_RF SG_ 277 EgoMotionRaw_CRC 100;
BA_REL_ "GenSigFirstTimeoutTime" BU_SG_REL_ SR_LR SG_ 277 EgoMotionRaw_CRC 3000;
BA_REL_ "GenSigTimeoutTime" BU_SG_REL_ SR_LR SG_ 277 EgoMotionRaw_CRC 100;
BA_REL_ "GenSigFirstTimeoutTime" BU_SG_REL_ SR_LF SG_ 277 EgoMotionRaw_CRC 3000;
BA_REL_ "GenSigTimeoutTime" BU_SG_REL_ SR_LF SG_ 277 EgoMotionRaw_CRC 100;
BA_REL_ "GenSigFirstTimeoutTime" BU_SG_REL_ SR_LF SG_ 277 EgoMotionRaw_ROPBrakeActive 3000;
BA_REL_ "GenSigTimeoutTime" BU_SG_REL_ SR_LF SG_ 277 EgoMotionRaw_ROPBrakeActive 100;
BA_REL_ "GenSigFirstTimeoutTime" BU_SG_REL_ SR_LR SG_ 277 EgoMotionRaw_ROPBrakeActive 3000;
BA_REL_ "GenSigTimeoutTime" BU_SG_REL_ SR_LR SG_ 277 EgoMotionRaw_ROPBrakeActive 100;
BA_REL_ "GenSigFirstTimeoutTime" BU_SG_REL_ SR_RF SG_ 277 EgoMotionRaw_ROPBrakeActive 3000;
BA_REL_ "GenSigTimeoutTime" BU_SG_REL_ SR_RF SG_ 277 EgoMotionRaw_ROPBrakeActive 100;
BA_REL_ "GenSigFirstTimeoutTime" BU_SG_REL_ SR_RR SG_ 277 EgoMotionRaw_ROPBrakeActive 3000;
BA_REL_ "GenSigTimeoutTime" BU_SG_REL_ SR_RR SG_ 277 EgoMotionRaw_ROPBrakeActive 100;
BA_REL_ "GenSigFirstTimeoutTime" BU_SG_REL_ SR_LR SG_ 277 EgoMotionRaw_RelLvlRrAxleRight 3000;
BA_REL_ "GenSigTimeoutTime" BU_SG_REL_ SR_LR SG_ 277 EgoMotionRaw_RelLvlRrAxleRight 100;
BA_REL_ "GenSigFirstTimeoutTime" BU_SG_REL_ SR_RR SG_ 277 EgoMotionRaw_RelLvlRrAxleRight 3000;
BA_REL_ "GenSigTimeoutTime" BU_SG_REL_ SR_RR SG_ 277 EgoMotionRaw_RelLvlRrAxleRight 100;
BA_REL_ "GenSigFirstTimeoutTime" BU_SG_REL_ SR_RF SG_ 277 EgoMotionRaw_RelLvlRrAxleRight 3000;
BA_REL_ "GenSigTimeoutTime" BU_SG_REL_ SR_RF SG_ 277 EgoMotionRaw_RelLvlRrAxleRight 100;
BA_REL_ "GenSigFirstTimeoutTime" BU_SG_REL_ SR_LF SG_ 277 EgoMotionRaw_RelLvlRrAxleRight 3000;
BA_REL_ "GenSigTimeoutTime" BU_SG_REL_ SR_LF SG_ 277 EgoMotionRaw_RelLvlRrAxleRight 100;
BA_REL_ "GenSigFirstTimeoutTime" BU_SG_REL_ SR_LR SG_ 277 EgoMotionRaw_YCEngineActive 3000;
BA_REL_ "GenSigTimeoutTime" BU_SG_REL_ SR_LR SG_ 277 EgoMotionRaw_YCEngineActive 100;
BA_REL_ "GenSigFirstTimeoutTime" BU_SG_REL_ SR_RR SG_ 277 EgoMotionRaw_YCEngineActive 3000;
BA_REL_ "GenSigTimeoutTime" BU_SG_REL_ SR_RR SG_ 277 EgoMotionRaw_YCEngineActive 100;
BA_REL_ "GenSigFirstTimeoutTime" BU_SG_REL_ SR_RF SG_ 277 EgoMotionRaw_YCEngineActive 3000;
BA_REL_ "GenSigTimeoutTime" BU_SG_REL_ SR_RF SG_ 277 EgoMotionRaw_YCEngineActive 100;
BA_REL_ "GenSigFirstTimeoutTime" BU_SG_REL_ SR_LF SG_ 277 EgoMotionRaw_YCEngineActive 3000;
BA_REL_ "GenSigTimeoutTime" BU_SG_REL_ SR_LF SG_ 277 EgoMotionRaw_YCEngineActive 100;
BA_REL_ "GenSigFirstTimeoutTime" BU_SG_REL_ SR_LF SG_ 277 EgoMotionRaw_SteeringWheelRatio 3000;
BA_REL_ "GenSigTimeoutTime" BU_SG_REL_ SR_LF SG_ 277 EgoMotionRaw_SteeringWheelRatio 100;
BA_REL_ "GenSigFirstTimeoutTime" BU_SG_REL_ SR_RF SG_ 277 EgoMotionRaw_SteeringWheelRatio 3000;
BA_REL_ "GenSigTimeoutTime" BU_SG_REL_ SR_RF SG_ 277 EgoMotionRaw_SteeringWheelRatio 100;
BA_REL_ "GenSigFirstTimeoutTime" BU_SG_REL_ SR_RR SG_ 277 EgoMotionRaw_SteeringWheelRatio 3000;
BA_REL_ "GenSigTimeoutTime" BU_SG_REL_ SR_RR SG_ 277 EgoMotionRaw_SteeringWheelRatio 100;
BA_REL_ "GenSigFirstTimeoutTime" BU_SG_REL_ SR_LR SG_ 277 EgoMotionRaw_SteeringWheelRatio 3000;
BA_REL_ "GenSigTimeoutTime" BU_SG_REL_ SR_LR SG_ 277 EgoMotionRaw_SteeringWheelRatio 100;
BA_REL_ "GenSigFirstTimeoutTime" BU_SG_REL_ SR_RF SG_ 277 EgoMotionRaw_AccKckDwn 3000;
BA_REL_ "GenSigTimeoutTime" BU_SG_REL_ SR_RF SG_ 277 EgoMotionRaw_AccKckDwn 100;
BA_REL_ "GenSigFirstTimeoutTime" BU_SG_REL_ SR_LF SG_ 277 EgoMotionRaw_AccKckDwn 3000;
BA_REL_ "GenSigTimeoutTime" BU_SG_REL_ SR_LF SG_ 277 EgoMotionRaw_AccKckDwn 100;
BA_REL_ "GenSigFirstTimeoutTime" BU_SG_REL_ SR_RR SG_ 277 EgoMotionRaw_AccKckDwn 3000;
BA_REL_ "GenSigTimeoutTime" BU_SG_REL_ SR_RR SG_ 277 EgoMotionRaw_AccKckDwn 100;
BA_REL_ "GenSigFirstTimeoutTime" BU_SG_REL_ SR_LR SG_ 277 EgoMotionRaw_AccKckDwn 3000;
BA_REL_ "GenSigTimeoutTime" BU_SG_REL_ SR_LR SG_ 277 EgoMotionRaw_AccKckDwn 100;
BA_REL_ "GenSigFirstTimeoutTime" BU_SG_REL_ SR_RR SG_ 1541 Trailer5Data_TotAxleCount 60000;
BA_REL_ "GenSigTimeoutTime" BU_SG_REL_ SR_RR SG_ 1541 Trailer5Data_TotAxleCount 30000;
BA_REL_ "GenSigFirstTimeoutTime" BU_SG_REL_ SR_LR SG_ 1541 Trailer5Data_TotAxleCount 60000;
BA_REL_ "GenSigTimeoutTime" BU_SG_REL_ SR_LR SG_ 1541 Trailer5Data_TotAxleCount 30000;
BA_REL_ "GenSigFirstTimeoutTime" BU_SG_REL_ SR_LF SG_ 1541 Trailer5Data_TotAxleCount 60000;
BA_REL_ "GenSigTimeoutTime" BU_SG_REL_ SR_LF SG_ 1541 Trailer5Data_TotAxleCount 30000;
BA_REL_ "GenSigFirstTimeoutTime" BU_SG_REL_ SR_RF SG_ 1541 Trailer5Data_TotAxleCount 60000;
BA_REL_ "GenSigTimeoutTime" BU_SG_REL_ SR_RF SG_ 1541 Trailer5Data_TotAxleCount 30000;
BA_REL_ "GenSigFirstTimeoutTime" BU_SG_REL_ SR_LF SG_ 1541 Trailer1Data_Validity 60000;
BA_REL_ "GenSigTimeoutTime" BU_SG_REL_ SR_LF SG_ 1541 Trailer1Data_Validity 30000;
BA_REL_ "GenSigFirstTimeoutTime" BU_SG_REL_ SR_RR SG_ 1541 Trailer1Data_Validity 60000;
BA_REL_ "GenSigTimeoutTime" BU_SG_REL_ SR_RR SG_ 1541 Trailer1Data_Validity 30000;
BA_REL_ "GenSigFirstTimeoutTime" BU_SG_REL_ SR_LR SG_ 1541 Trailer1Data_Validity 60000;
BA_REL_ "GenSigTimeoutTime" BU_SG_REL_ SR_LR SG_ 1541 Trailer1Data_Validity 30000;
BA_REL_ "GenSigFirstTimeoutTime" BU_SG_REL_ SR_RF SG_ 1541 Trailer1Data_Validity 60000;
BA_REL_ "GenSigTimeoutTime" BU_SG_REL_ SR_RF SG_ 1541 Trailer1Data_Validity 30000;
BA_REL_ "GenSigFirstTimeoutTime" BU_SG_REL_ SR_RR SG_ 1541 Trailer4Data_Validity 60000;
BA_REL_ "GenSigTimeoutTime" BU_SG_REL_ SR_RR SG_ 1541 Trailer4Data_Validity 30000;
BA_REL_ "GenSigFirstTimeoutTime" BU_SG_REL_ SR_RF SG_ 1541 Trailer4Data_Validity 60000;
BA_REL_ "GenSigTimeoutTime" BU_SG_REL_ SR_RF SG_ 1541 Trailer4Data_Validity 30000;
BA_REL_ "GenSigFirstTimeoutTime" BU_SG_REL_ SR_LF SG_ 1541 Trailer4Data_Validity 60000;
BA_REL_ "GenSigTimeoutTime" BU_SG_REL_ SR_LF SG_ 1541 Trailer4Data_Validity 30000;
BA_REL_ "GenSigFirstTimeoutTime" BU_SG_REL_ SR_LR SG_ 1541 Trailer4Data_Validity 60000;
BA_REL_ "GenSigTimeoutTime" BU_SG_REL_ SR_LR SG_ 1541 Trailer4Data_Validity 30000;
BA_REL_ "GenSigFirstTimeoutTime" BU_SG_REL_ SR_RR SG_ 1541 Trailer3Data_FrAxleCount 60000;
BA_REL_ "GenSigTimeoutTime" BU_SG_REL_ SR_RR SG_ 1541 Trailer3Data_FrAxleCount 30000;
BA_REL_ "GenSigFirstTimeoutTime" BU_SG_REL_ SR_LF SG_ 1541 Trailer3Data_FrAxleCount 60000;
BA_REL_ "GenSigTimeoutTime" BU_SG_REL_ SR_LF SG_ 1541 Trailer3Data_FrAxleCount 30000;
BA_REL_ "GenSigFirstTimeoutTime" BU_SG_REL_ SR_LR SG_ 1541 Trailer3Data_FrAxleCount 60000;
BA_REL_ "GenSigTimeoutTime" BU_SG_REL_ SR_LR SG_ 1541 Trailer3Data_FrAxleCount 30000;
BA_REL_ "GenSigFirstTimeoutTime" BU_SG_REL_ SR_RF SG_ 1541 Trailer3Data_FrAxleCount 60000;
BA_REL_ "GenSigTimeoutTime" BU_SG_REL_ SR_RF SG_ 1541 Trailer3Data_FrAxleCount 30000;
BA_REL_ "GenSigFirstTimeoutTime" BU_SG_REL_ SR_LF SG_ 1541 Trailer1Data_Length 60000;
BA_REL_ "GenSigTimeoutTime" BU_SG_REL_ SR_LF SG_ 1541 Trailer1Data_Length 30000;
BA_REL_ "GenSigFirstTimeoutTime" BU_SG_REL_ SR_LR SG_ 1541 Trailer1Data_Length 60000;
BA_REL_ "GenSigTimeoutTime" BU_SG_REL_ SR_LR SG_ 1541 Trailer1Data_Length 30000;
BA_REL_ "GenSigFirstTimeoutTime" BU_SG_REL_ SR_RR SG_ 1541 Trailer1Data_Length 60000;
BA_REL_ "GenSigTimeoutTime" BU_SG_REL_ SR_RR SG_ 1541 Trailer1Data_Length 30000;
BA_REL_ "GenSigFirstTimeoutTime" BU_SG_REL_ SR_RF SG_ 1541 Trailer1Data_Length 60000;
BA_REL_ "GenSigTimeoutTime" BU_SG_REL_ SR_RF SG_ 1541 Trailer1Data_Length 30000;
BA_REL_ "GenSigFirstTimeoutTime" BU_SG_REL_ SR_RR SG_ 1541 Trailer1Data_Wheelbase 60000;
BA_REL_ "GenSigTimeoutTime" BU_SG_REL_ SR_RR SG_ 1541 Trailer1Data_Wheelbase 30000;
BA_REL_ "GenSigFirstTimeoutTime" BU_SG_REL_ SR_LF SG_ 1541 Trailer1Data_Wheelbase 60000;
BA_REL_ "GenSigTimeoutTime" BU_SG_REL_ SR_LF SG_ 1541 Trailer1Data_Wheelbase 30000;
BA_REL_ "GenSigFirstTimeoutTime" BU_SG_REL_ SR_RF SG_ 1541 Trailer1Data_Wheelbase 60000;
BA_REL_ "GenSigTimeoutTime" BU_SG_REL_ SR_RF SG_ 1541 Trailer1Data_Wheelbase 30000;
BA_REL_ "GenSigFirstTimeoutTime" BU_SG_REL_ SR_LR SG_ 1541 Trailer1Data_Wheelbase 60000;
BA_REL_ "GenSigTimeoutTime" BU_SG_REL_ SR_LR SG_ 1541 Trailer1Data_Wheelbase 30000;
BA_REL_ "GenSigFirstTimeoutTime" BU_SG_REL_ SR_RR SG_ 1541 Trailer2Data_DistToCouplingP 60000;
BA_REL_ "GenSigTimeoutTime" BU_SG_REL_ SR_RR SG_ 1541 Trailer2Data_DistToCouplingP 30000;
BA_REL_ "GenSigFirstTimeoutTime" BU_SG_REL_ SR_LR SG_ 1541 Trailer2Data_DistToCouplingP 60000;
BA_REL_ "GenSigTimeoutTime" BU_SG_REL_ SR_LR SG_ 1541 Trailer2Data_DistToCouplingP 30000;
BA_REL_ "GenSigFirstTimeoutTime" BU_SG_REL_ SR_RF SG_ 1541 Trailer2Data_DistToCouplingP 60000;
BA_REL_ "GenSigTimeoutTime" BU_SG_REL_ SR_RF SG_ 1541 Trailer2Data_DistToCouplingP 30000;
BA_REL_ "GenSigFirstTimeoutTime" BU_SG_REL_ SR_LF SG_ 1541 Trailer2Data_DistToCouplingP 60000;
BA_REL_ "GenSigTimeoutTime" BU_SG_REL_ SR_LF SG_ 1541 Trailer2Data_DistToCouplingP 30000;
BA_REL_ "GenSigFirstTimeoutTime" BU_SG_REL_ SR_RF SG_ 1541 Trailer4Data_Type 60000;
BA_REL_ "GenSigTimeoutTime" BU_SG_REL_ SR_RF SG_ 1541 Trailer4Data_Type 30000;
BA_REL_ "GenSigFirstTimeoutTime" BU_SG_REL_ SR_RR SG_ 1541 Trailer4Data_Type 60000;
BA_REL_ "GenSigTimeoutTime" BU_SG_REL_ SR_RR SG_ 1541 Trailer4Data_Type 30000;
BA_REL_ "GenSigFirstTimeoutTime" BU_SG_REL_ SR_LF SG_ 1541 Trailer4Data_Type 60000;
BA_REL_ "GenSigTimeoutTime" BU_SG_REL_ SR_LF SG_ 1541 Trailer4Data_Type 30000;
BA_REL_ "GenSigFirstTimeoutTime" BU_SG_REL_ SR_LR SG_ 1541 Trailer4Data_Type 60000;
BA_REL_ "GenSigTimeoutTime" BU_SG_REL_ SR_LR SG_ 1541 Trailer4Data_Type 30000;
BA_REL_ "GenSigFirstTimeoutTime" BU_SG_REL_ SR_RF SG_ 1541 Trailer5Data_DistToCouplingP 60000;
BA_REL_ "GenSigTimeoutTime" BU_SG_REL_ SR_RF SG_ 1541 Trailer5Data_DistToCouplingP 30000;
BA_REL_ "GenSigFirstTimeoutTime" BU_SG_REL_ SR_LR SG_ 1541 Trailer5Data_DistToCouplingP 60000;
BA_REL_ "GenSigTimeoutTime" BU_SG_REL_ SR_LR SG_ 1541 Trailer5Data_DistToCouplingP 30000;
BA_REL_ "GenSigFirstTimeoutTime" BU_SG_REL_ SR_RR SG_ 1541 Trailer5Data_DistToCouplingP 60000;
BA_REL_ "GenSigTimeoutTime" BU_SG_REL_ SR_RR SG_ 1541 Trailer5Data_DistToCouplingP 30000;
BA_REL_ "GenSigFirstTimeoutTime" BU_SG_REL_ SR_LF SG_ 1541 Trailer5Data_DistToCouplingP 60000;
BA_REL_ "GenSigTimeoutTime" BU_SG_REL_ SR_LF SG_ 1541 Trailer5Data_DistToCouplingP 30000;
BA_REL_ "GenSigFirstTimeoutTime" BU_SG_REL_ SR_LR SG_ 1541 Trailer2Data_Wheelbase 60000;
BA_REL_ "GenSigTimeoutTime" BU_SG_REL_ SR_LR SG_ 1541 Trailer2Data_Wheelbase 30000;
BA_REL_ "GenSigFirstTimeoutTime" BU_SG_REL_ SR_RF SG_ 1541 Trailer2Data_Wheelbase 60000;
BA_REL_ "GenSigTimeoutTime" BU_SG_REL_ SR_RF SG_ 1541 Trailer2Data_Wheelbase 30000;
BA_REL_ "GenSigFirstTimeoutTime" BU_SG_REL_ SR_RR SG_ 1541 Trailer2Data_Wheelbase 60000;
BA_REL_ "GenSigTimeoutTime" BU_SG_REL_ SR_RR SG_ 1541 Trailer2Data_Wheelbase 30000;
BA_REL_ "GenSigFirstTimeoutTime" BU_SG_REL_ SR_LF SG_ 1541 Trailer2Data_Wheelbase 60000;
BA_REL_ "GenSigTimeoutTime" BU_SG_REL_ SR_LF SG_ 1541 Trailer2Data_Wheelbase 30000;
BA_REL_ "GenSigFirstTimeoutTime" BU_SG_REL_ SR_RF SG_ 1541 Trailer5Data_Type 60000;
BA_REL_ "GenSigTimeoutTime" BU_SG_REL_ SR_RF SG_ 1541 Trailer5Data_Type 30000;
BA_REL_ "GenSigFirstTimeoutTime" BU_SG_REL_ SR_LF SG_ 1541 Trailer5Data_Type 60000;
BA_REL_ "GenSigTimeoutTime" BU_SG_REL_ SR_LF SG_ 1541 Trailer5Data_Type 30000;
BA_REL_ "GenSigFirstTimeoutTime" BU_SG_REL_ SR_RR SG_ 1541 Trailer5Data_Type 60000;
BA_REL_ "GenSigTimeoutTime" BU_SG_REL_ SR_RR SG_ 1541 Trailer5Data_Type 30000;
BA_REL_ "GenSigFirstTimeoutTime" BU_SG_REL_ SR_LR SG_ 1541 Trailer5Data_Type 60000;
BA_REL_ "GenSigTimeoutTime" BU_SG_REL_ SR_LR SG_ 1541 Trailer5Data_Type 30000;
BA_REL_ "GenSigFirstTimeoutTime" BU_SG_REL_ SR_LF SG_ 1541 Trailer4Data_TotAxleCount 60000;
BA_REL_ "GenSigTimeoutTime" BU_SG_REL_ SR_LF SG_ 1541 Trailer4Data_TotAxleCount 30000;
BA_REL_ "GenSigFirstTimeoutTime" BU_SG_REL_ SR_RR SG_ 1541 Trailer4Data_TotAxleCount 60000;
BA_REL_ "GenSigTimeoutTime" BU_SG_REL_ SR_RR SG_ 1541 Trailer4Data_TotAxleCount 30000;
BA_REL_ "GenSigFirstTimeoutTime" BU_SG_REL_ SR_LR SG_ 1541 Trailer4Data_TotAxleCount 60000;
BA_REL_ "GenSigTimeoutTime" BU_SG_REL_ SR_LR SG_ 1541 Trailer4Data_TotAxleCount 30000;
BA_REL_ "GenSigFirstTimeoutTime" BU_SG_REL_ SR_RF SG_ 1541 Trailer4Data_TotAxleCount 60000;
BA_REL_ "GenSigTimeoutTime" BU_SG_REL_ SR_RF SG_ 1541 Trailer4Data_TotAxleCount 30000;
BA_REL_ "GenSigFirstTimeoutTime" BU_SG_REL_ SR_LF SG_ 1541 Trailer4Data_Length 60000;
BA_REL_ "GenSigTimeoutTime" BU_SG_REL_ SR_LF SG_ 1541 Trailer4Data_Length 30000;
BA_REL_ "GenSigFirstTimeoutTime" BU_SG_REL_ SR_LR SG_ 1541 Trailer4Data_Length 60000;
BA_REL_ "GenSigTimeoutTime" BU_SG_REL_ SR_LR SG_ 1541 Trailer4Data_Length 30000;
BA_REL_ "GenSigFirstTimeoutTime" BU_SG_REL_ SR_RR SG_ 1541 Trailer4Data_Length 60000;
BA_REL_ "GenSigTimeoutTime" BU_SG_REL_ SR_RR SG_ 1541 Trailer4Data_Length 30000;
BA_REL_ "GenSigFirstTimeoutTime" BU_SG_REL_ SR_RF SG_ 1541 Trailer4Data_Length 60000;
BA_REL_ "GenSigTimeoutTime" BU_SG_REL_ SR_RF SG_ 1541 Trailer4Data_Length 30000;
BA_REL_ "GenSigFirstTimeoutTime" BU_SG_REL_ SR_LR SG_ 1541 Trailer5Data_Validity 60000;
BA_REL_ "GenSigTimeoutTime" BU_SG_REL_ SR_LR SG_ 1541 Trailer5Data_Validity 30000;
BA_REL_ "GenSigFirstTimeoutTime" BU_SG_REL_ SR_RR SG_ 1541 Trailer5Data_Validity 60000;
BA_REL_ "GenSigTimeoutTime" BU_SG_REL_ SR_RR SG_ 1541 Trailer5Data_Validity 30000;
BA_REL_ "GenSigFirstTimeoutTime" BU_SG_REL_ SR_LF SG_ 1541 Trailer5Data_Validity 60000;
BA_REL_ "GenSigTimeoutTime" BU_SG_REL_ SR_LF SG_ 1541 Trailer5Data_Validity 30000;
BA_REL_ "GenSigFirstTimeoutTime" BU_SG_REL_ SR_RF SG_ 1541 Trailer5Data_Validity 60000;
BA_REL_ "GenSigTimeoutTime" BU_SG_REL_ SR_RF SG_ 1541 Trailer5Data_Validity 30000;
BA_REL_ "GenSigFirstTimeoutTime" BU_SG_REL_ SR_LF SG_ 1541 Trailer3Data_Wheelbase 60000;
BA_REL_ "GenSigTimeoutTime" BU_SG_REL_ SR_LF SG_ 1541 Trailer3Data_Wheelbase 30000;
BA_REL_ "GenSigFirstTimeoutTime" BU_SG_REL_ SR_LR SG_ 1541 Trailer3Data_Wheelbase 60000;
BA_REL_ "GenSigTimeoutTime" BU_SG_REL_ SR_LR SG_ 1541 Trailer3Data_Wheelbase 30000;
BA_REL_ "GenSigFirstTimeoutTime" BU_SG_REL_ SR_RR SG_ 1541 Trailer3Data_Wheelbase 60000;
BA_REL_ "GenSigTimeoutTime" BU_SG_REL_ SR_RR SG_ 1541 Trailer3Data_Wheelbase 30000;
BA_REL_ "GenSigFirstTimeoutTime" BU_SG_REL_ SR_RF SG_ 1541 Trailer3Data_Wheelbase 60000;
BA_REL_ "GenSigTimeoutTime" BU_SG_REL_ SR_RF SG_ 1541 Trailer3Data_Wheelbase 30000;
BA_REL_ "GenSigFirstTimeoutTime" BU_SG_REL_ SR_RR SG_ 1541 Trailer3Data_Length 60000;
BA_REL_ "GenSigTimeoutTime" BU_SG_REL_ SR_RR SG_ 1541 Trailer3Data_Length 30000;
BA_REL_ "GenSigFirstTimeoutTime" BU_SG_REL_ SR_RF SG_ 1541 Trailer3Data_Length 60000;
BA_REL_ "GenSigTimeoutTime" BU_SG_REL_ SR_RF SG_ 1541 Trailer3Data_Length 30000;
BA_REL_ "GenSigFirstTimeoutTime" BU_SG_REL_ SR_LR SG_ 1541 Trailer3Data_Length 60000;
BA_REL_ "GenSigTimeoutTime" BU_SG_REL_ SR_LR SG_ 1541 Trailer3Data_Length 30000;
BA_REL_ "GenSigFirstTimeoutTime" BU_SG_REL_ SR_LF SG_ 1541 Trailer3Data_Length 60000;
BA_REL_ "GenSigTimeoutTime" BU_SG_REL_ SR_LF SG_ 1541 Trailer3Data_Length 30000;
BA_REL_ "GenSigFirstTimeoutTime" BU_SG_REL_ SR_LR SG_ 1541 Trailer3Data_DistToCouplingP 60000;
BA_REL_ "GenSigTimeoutTime" BU_SG_REL_ SR_LR SG_ 1541 Trailer3Data_DistToCouplingP 30000;
BA_REL_ "GenSigFirstTimeoutTime" BU_SG_REL_ SR_RF SG_ 1541 Trailer3Data_DistToCouplingP 60000;
BA_REL_ "GenSigTimeoutTime" BU_SG_REL_ SR_RF SG_ 1541 Trailer3Data_DistToCouplingP 30000;
BA_REL_ "GenSigFirstTimeoutTime" BU_SG_REL_ SR_LF SG_ 1541 Trailer3Data_DistToCouplingP 60000;
BA_REL_ "GenSigTimeoutTime" BU_SG_REL_ SR_LF SG_ 1541 Trailer3Data_DistToCouplingP 30000;
BA_REL_ "GenSigFirstTimeoutTime" BU_SG_REL_ SR_RR SG_ 1541 Trailer3Data_DistToCouplingP 60000;
BA_REL_ "GenSigTimeoutTime" BU_SG_REL_ SR_RR SG_ 1541 Trailer3Data_DistToCouplingP 30000;
BA_REL_ "GenSigFirstTimeoutTime" BU_SG_REL_ SR_LF SG_ 1541 Trailer3Data_DrawbarLength 60000;
BA_REL_ "GenSigTimeoutTime" BU_SG_REL_ SR_LF SG_ 1541 Trailer3Data_DrawbarLength 30000;
BA_REL_ "GenSigFirstTimeoutTime" BU_SG_REL_ SR_RR SG_ 1541 Trailer3Data_DrawbarLength 60000;
BA_REL_ "GenSigTimeoutTime" BU_SG_REL_ SR_RR SG_ 1541 Trailer3Data_DrawbarLength 30000;
BA_REL_ "GenSigFirstTimeoutTime" BU_SG_REL_ SR_RF SG_ 1541 Trailer3Data_DrawbarLength 60000;
BA_REL_ "GenSigTimeoutTime" BU_SG_REL_ SR_RF SG_ 1541 Trailer3Data_DrawbarLength 30000;
BA_REL_ "GenSigFirstTimeoutTime" BU_SG_REL_ SR_LR SG_ 1541 Trailer3Data_DrawbarLength 60000;
BA_REL_ "GenSigTimeoutTime" BU_SG_REL_ SR_LR SG_ 1541 Trailer3Data_DrawbarLength 30000;
BA_REL_ "GenSigFirstTimeoutTime" BU_SG_REL_ SR_RR SG_ 1541 Trailer5Data_FrAxleCount 60000;
BA_REL_ "GenSigTimeoutTime" BU_SG_REL_ SR_RR SG_ 1541 Trailer5Data_FrAxleCount 30000;
BA_REL_ "GenSigFirstTimeoutTime" BU_SG_REL_ SR_RF SG_ 1541 Trailer5Data_FrAxleCount 60000;
BA_REL_ "GenSigTimeoutTime" BU_SG_REL_ SR_RF SG_ 1541 Trailer5Data_FrAxleCount 30000;
BA_REL_ "GenSigFirstTimeoutTime" BU_SG_REL_ SR_LF SG_ 1541 Trailer5Data_FrAxleCount 60000;
BA_REL_ "GenSigTimeoutTime" BU_SG_REL_ SR_LF SG_ 1541 Trailer5Data_FrAxleCount 30000;
BA_REL_ "GenSigFirstTimeoutTime" BU_SG_REL_ SR_LR SG_ 1541 Trailer5Data_FrAxleCount 60000;
BA_REL_ "GenSigTimeoutTime" BU_SG_REL_ SR_LR SG_ 1541 Trailer5Data_FrAxleCount 30000;
BA_REL_ "GenSigFirstTimeoutTime" BU_SG_REL_ SR_LF SG_ 1541 Trailer2Data_DrawbarLength 60000;
BA_REL_ "GenSigTimeoutTime" BU_SG_REL_ SR_LF SG_ 1541 Trailer2Data_DrawbarLength 30000;
BA_REL_ "GenSigFirstTimeoutTime" BU_SG_REL_ SR_LR SG_ 1541 Trailer2Data_DrawbarLength 60000;
BA_REL_ "GenSigTimeoutTime" BU_SG_REL_ SR_LR SG_ 1541 Trailer2Data_DrawbarLength 30000;
BA_REL_ "GenSigFirstTimeoutTime" BU_SG_REL_ SR_RR SG_ 1541 Trailer2Data_DrawbarLength 60000;
BA_REL_ "GenSigTimeoutTime" BU_SG_REL_ SR_RR SG_ 1541 Trailer2Data_DrawbarLength 30000;
BA_REL_ "GenSigFirstTimeoutTime" BU_SG_REL_ SR_RF SG_ 1541 Trailer2Data_DrawbarLength 60000;
BA_REL_ "GenSigTimeoutTime" BU_SG_REL_ SR_RF SG_ 1541 Trailer2Data_DrawbarLength 30000;
BA_REL_ "GenSigFirstTimeoutTime" BU_SG_REL_ SR_RR SG_ 1541 Trailer5Data_Wheelbase 60000;
BA_REL_ "GenSigTimeoutTime" BU_SG_REL_ SR_RR SG_ 1541 Trailer5Data_Wheelbase 30000;
BA_REL_ "GenSigFirstTimeoutTime" BU_SG_REL_ SR_LR SG_ 1541 Trailer5Data_Wheelbase 60000;
BA_REL_ "GenSigTimeoutTime" BU_SG_REL_ SR_LR SG_ 1541 Trailer5Data_Wheelbase 30000;
BA_REL_ "GenSigFirstTimeoutTime" BU_SG_REL_ SR_LF SG_ 1541 Trailer5Data_Wheelbase 60000;
BA_REL_ "GenSigTimeoutTime" BU_SG_REL_ SR_LF SG_ 1541 Trailer5Data_Wheelbase 30000;
BA_REL_ "GenSigFirstTimeoutTime" BU_SG_REL_ SR_RF SG_ 1541 Trailer5Data_Wheelbase 60000;
BA_REL_ "GenSigTimeoutTime" BU_SG_REL_ SR_RF SG_ 1541 Trailer5Data_Wheelbase 30000;
BA_REL_ "GenSigFirstTimeoutTime" BU_SG_REL_ SR_LF SG_ 1541 Trailer2Data_TotAxleCount 60000;
BA_REL_ "GenSigTimeoutTime" BU_SG_REL_ SR_LF SG_ 1541 Trailer2Data_TotAxleCount 30000;
BA_REL_ "GenSigFirstTimeoutTime" BU_SG_REL_ SR_RF SG_ 1541 Trailer2Data_TotAxleCount 60000;
BA_REL_ "GenSigTimeoutTime" BU_SG_REL_ SR_RF SG_ 1541 Trailer2Data_TotAxleCount 30000;
BA_REL_ "GenSigFirstTimeoutTime" BU_SG_REL_ SR_RR SG_ 1541 Trailer2Data_TotAxleCount 60000;
BA_REL_ "GenSigTimeoutTime" BU_SG_REL_ SR_RR SG_ 1541 Trailer2Data_TotAxleCount 30000;
BA_REL_ "GenSigFirstTimeoutTime" BU_SG_REL_ SR_LR SG_ 1541 Trailer2Data_TotAxleCount 60000;
BA_REL_ "GenSigTimeoutTime" BU_SG_REL_ SR_LR SG_ 1541 Trailer2Data_TotAxleCount 30000;
BA_REL_ "GenSigFirstTimeoutTime" BU_SG_REL_ SR_RF SG_ 1541 Trailer4Data_Wheelbase 60000;
BA_REL_ "GenSigTimeoutTime" BU_SG_REL_ SR_RF SG_ 1541 Trailer4Data_Wheelbase 30000;
BA_REL_ "GenSigFirstTimeoutTime" BU_SG_REL_ SR_LF SG_ 1541 Trailer4Data_Wheelbase 60000;
BA_REL_ "GenSigTimeoutTime" BU_SG_REL_ SR_LF SG_ 1541 Trailer4Data_Wheelbase 30000;
BA_REL_ "GenSigFirstTimeoutTime" BU_SG_REL_ SR_LR SG_ 1541 Trailer4Data_Wheelbase 60000;
BA_REL_ "GenSigTimeoutTime" BU_SG_REL_ SR_LR SG_ 1541 Trailer4Data_Wheelbase 30000;
BA_REL_ "GenSigFirstTimeoutTime" BU_SG_REL_ SR_RR SG_ 1541 Trailer4Data_Wheelbase 60000;
BA_REL_ "GenSigTimeoutTime" BU_SG_REL_ SR_RR SG_ 1541 Trailer4Data_Wheelbase 30000;
BA_REL_ "GenSigFirstTimeoutTime" BU_SG_REL_ SR_RR SG_ 1541 Trailer3Data_Validity 60000;
BA_REL_ "GenSigTimeoutTime" BU_SG_REL_ SR_RR SG_ 1541 Trailer3Data_Validity 30000;
BA_REL_ "GenSigFirstTimeoutTime" BU_SG_REL_ SR_LR SG_ 1541 Trailer3Data_Validity 60000;
BA_REL_ "GenSigTimeoutTime" BU_SG_REL_ SR_LR SG_ 1541 Trailer3Data_Validity 30000;
BA_REL_ "GenSigFirstTimeoutTime" BU_SG_REL_ SR_LF SG_ 1541 Trailer3Data_Validity 60000;
BA_REL_ "GenSigTimeoutTime" BU_SG_REL_ SR_LF SG_ 1541 Trailer3Data_Validity 30000;
BA_REL_ "GenSigFirstTimeoutTime" BU_SG_REL_ SR_RF SG_ 1541 Trailer3Data_Validity 60000;
BA_REL_ "GenSigTimeoutTime" BU_SG_REL_ SR_RF SG_ 1541 Trailer3Data_Validity 30000;
BA_REL_ "GenSigFirstTimeoutTime" BU_SG_REL_ SR_RF SG_ 1541 Trailer2Data_Validity 60000;
BA_REL_ "GenSigTimeoutTime" BU_SG_REL_ SR_RF SG_ 1541 Trailer2Data_Validity 30000;
BA_REL_ "GenSigFirstTimeoutTime" BU_SG_REL_ SR_LF SG_ 1541 Trailer2Data_Validity 60000;
BA_REL_ "GenSigTimeoutTime" BU_SG_REL_ SR_LF SG_ 1541 Trailer2Data_Validity 30000;
BA_REL_ "GenSigFirstTimeoutTime" BU_SG_REL_ SR_LR SG_ 1541 Trailer2Data_Validity 60000;
BA_REL_ "GenSigTimeoutTime" BU_SG_REL_ SR_LR SG_ 1541 Trailer2Data_Validity 30000;
BA_REL_ "GenSigFirstTimeoutTime" BU_SG_REL_ SR_RR SG_ 1541 Trailer2Data_Validity 60000;
BA_REL_ "GenSigTimeoutTime" BU_SG_REL_ SR_RR SG_ 1541 Trailer2Data_Validity 30000;
BA_REL_ "GenSigFirstTimeoutTime" BU_SG_REL_ SR_LF SG_ 1541 Trailer2Data_FrAxleCount 60000;
BA_REL_ "GenSigTimeoutTime" BU_SG_REL_ SR_LF SG_ 1541 Trailer2Data_FrAxleCount 30000;
BA_REL_ "GenSigFirstTimeoutTime" BU_SG_REL_ SR_LR SG_ 1541 Trailer2Data_FrAxleCount 60000;
BA_REL_ "GenSigTimeoutTime" BU_SG_REL_ SR_LR SG_ 1541 Trailer2Data_FrAxleCount 30000;
BA_REL_ "GenSigFirstTimeoutTime" BU_SG_REL_ SR_RF SG_ 1541 Trailer2Data_FrAxleCount 60000;
BA_REL_ "GenSigTimeoutTime" BU_SG_REL_ SR_RF SG_ 1541 Trailer2Data_FrAxleCount 30000;
BA_REL_ "GenSigFirstTimeoutTime" BU_SG_REL_ SR_RR SG_ 1541 Trailer2Data_FrAxleCount 60000;
BA_REL_ "GenSigTimeoutTime" BU_SG_REL_ SR_RR SG_ 1541 Trailer2Data_FrAxleCount 30000;
BA_REL_ "GenSigFirstTimeoutTime" BU_SG_REL_ SR_LF SG_ 1541 Trailer1Data_TotAxleCount 60000;
BA_REL_ "GenSigTimeoutTime" BU_SG_REL_ SR_LF SG_ 1541 Trailer1Data_TotAxleCount 30000;
BA_REL_ "GenSigFirstTimeoutTime" BU_SG_REL_ SR_RF SG_ 1541 Trailer1Data_TotAxleCount 60000;
BA_REL_ "GenSigTimeoutTime" BU_SG_REL_ SR_RF SG_ 1541 Trailer1Data_TotAxleCount 30000;
BA_REL_ "GenSigFirstTimeoutTime" BU_SG_REL_ SR_LR SG_ 1541 Trailer1Data_TotAxleCount 60000;
BA_REL_ "GenSigTimeoutTime" BU_SG_REL_ SR_LR SG_ 1541 Trailer1Data_TotAxleCount 30000;
BA_REL_ "GenSigFirstTimeoutTime" BU_SG_REL_ SR_RR SG_ 1541 Trailer1Data_TotAxleCount 60000;
BA_REL_ "GenSigTimeoutTime" BU_SG_REL_ SR_RR SG_ 1541 Trailer1Data_TotAxleCount 30000;
BA_REL_ "GenSigFirstTimeoutTime" BU_SG_REL_ SR_RR SG_ 1541 Trailer1Data_DistToCouplingP 60000;
BA_REL_ "GenSigTimeoutTime" BU_SG_REL_ SR_RR SG_ 1541 Trailer1Data_DistToCouplingP 30000;
BA_REL_ "GenSigFirstTimeoutTime" BU_SG_REL_ SR_LR SG_ 1541 Trailer1Data_DistToCouplingP 60000;
BA_REL_ "GenSigTimeoutTime" BU_SG_REL_ SR_LR SG_ 1541 Trailer1Data_DistToCouplingP 30000;
BA_REL_ "GenSigFirstTimeoutTime" BU_SG_REL_ SR_RF SG_ 1541 Trailer1Data_DistToCouplingP 60000;
BA_REL_ "GenSigTimeoutTime" BU_SG_REL_ SR_RF SG_ 1541 Trailer1Data_DistToCouplingP 30000;
BA_REL_ "GenSigFirstTimeoutTime" BU_SG_REL_ SR_LF SG_ 1541 Trailer1Data_DistToCouplingP 60000;
BA_REL_ "GenSigTimeoutTime" BU_SG_REL_ SR_LF SG_ 1541 Trailer1Data_DistToCouplingP 30000;
BA_REL_ "GenSigFirstTimeoutTime" BU_SG_REL_ SR_LF SG_ 1541 Trailer5Data_Length 60000;
BA_REL_ "GenSigTimeoutTime" BU_SG_REL_ SR_LF SG_ 1541 Trailer5Data_Length 30000;
BA_REL_ "GenSigFirstTimeoutTime" BU_SG_REL_ SR_RR SG_ 1541 Trailer5Data_Length 60000;
BA_REL_ "GenSigTimeoutTime" BU_SG_REL_ SR_RR SG_ 1541 Trailer5Data_Length 30000;
BA_REL_ "GenSigFirstTimeoutTime" BU_SG_REL_ SR_RF SG_ 1541 Trailer5Data_Length 60000;
BA_REL_ "GenSigTimeoutTime" BU_SG_REL_ SR_RF SG_ 1541 Trailer5Data_Length 30000;
BA_REL_ "GenSigFirstTimeoutTime" BU_SG_REL_ SR_LR SG_ 1541 Trailer5Data_Length 60000;
BA_REL_ "GenSigTimeoutTime" BU_SG_REL_ SR_LR SG_ 1541 Trailer5Data_Length 30000;
BA_REL_ "GenSigFirstTimeoutTime" BU_SG_REL_ SR_RF SG_ 1541 Trailer4Data_DistToCouplingP 60000;
BA_REL_ "GenSigTimeoutTime" BU_SG_REL_ SR_RF SG_ 1541 Trailer4Data_DistToCouplingP 30000;
BA_REL_ "GenSigFirstTimeoutTime" BU_SG_REL_ SR_LF SG_ 1541 Trailer4Data_DistToCouplingP 60000;
BA_REL_ "GenSigTimeoutTime" BU_SG_REL_ SR_LF SG_ 1541 Trailer4Data_DistToCouplingP 30000;
BA_REL_ "GenSigFirstTimeoutTime" BU_SG_REL_ SR_LR SG_ 1541 Trailer4Data_DistToCouplingP 60000;
BA_REL_ "GenSigTimeoutTime" BU_SG_REL_ SR_LR SG_ 1541 Trailer4Data_DistToCouplingP 30000;
BA_REL_ "GenSigFirstTimeoutTime" BU_SG_REL_ SR_RR SG_ 1541 Trailer4Data_DistToCouplingP 60000;
BA_REL_ "GenSigTimeoutTime" BU_SG_REL_ SR_RR SG_ 1541 Trailer4Data_DistToCouplingP 30000;
BA_REL_ "GenSigFirstTimeoutTime" BU_SG_REL_ SR_LR SG_ 1541 Trailer3Data_TotAxleCount 60000;
BA_REL_ "GenSigTimeoutTime" BU_SG_REL_ SR_LR SG_ 1541 Trailer3Data_TotAxleCount 30000;
BA_REL_ "GenSigFirstTimeoutTime" BU_SG_REL_ SR_RR SG_ 1541 Trailer3Data_TotAxleCount 60000;
BA_REL_ "GenSigTimeoutTime" BU_SG_REL_ SR_RR SG_ 1541 Trailer3Data_TotAxleCount 30000;
BA_REL_ "GenSigFirstTimeoutTime" BU_SG_REL_ SR_LF SG_ 1541 Trailer3Data_TotAxleCount 60000;
BA_REL_ "GenSigTimeoutTime" BU_SG_REL_ SR_LF SG_ 1541 Trailer3Data_TotAxleCount 30000;
BA_REL_ "GenSigFirstTimeoutTime" BU_SG_REL_ SR_RF SG_ 1541 Trailer3Data_TotAxleCount 60000;
BA_REL_ "GenSigTimeoutTime" BU_SG_REL_ SR_RF SG_ 1541 Trailer3Data_TotAxleCount 30000;
BA_REL_ "GenSigFirstTimeoutTime" BU_SG_REL_ SR_RF SG_ 1541 Trailer3Data_Type 60000;
BA_REL_ "GenSigTimeoutTime" BU_SG_REL_ SR_RF SG_ 1541 Trailer3Data_Type 30000;
BA_REL_ "GenSigFirstTimeoutTime" BU_SG_REL_ SR_LF SG_ 1541 Trailer3Data_Type 60000;
BA_REL_ "GenSigTimeoutTime" BU_SG_REL_ SR_LF SG_ 1541 Trailer3Data_Type 30000;
BA_REL_ "GenSigFirstTimeoutTime" BU_SG_REL_ SR_RR SG_ 1541 Trailer3Data_Type 60000;
BA_REL_ "GenSigTimeoutTime" BU_SG_REL_ SR_RR SG_ 1541 Trailer3Data_Type 30000;
BA_REL_ "GenSigFirstTimeoutTime" BU_SG_REL_ SR_LR SG_ 1541 Trailer3Data_Type 60000;
BA_REL_ "GenSigTimeoutTime" BU_SG_REL_ SR_LR SG_ 1541 Trailer3Data_Type 30000;
BA_REL_ "GenSigFirstTimeoutTime" BU_SG_REL_ SR_RR SG_ 1541 Trailer2Data_Type 60000;
BA_REL_ "GenSigTimeoutTime" BU_SG_REL_ SR_RR SG_ 1541 Trailer2Data_Type 30000;
BA_REL_ "GenSigFirstTimeoutTime" BU_SG_REL_ SR_LR SG_ 1541 Trailer2Data_Type 60000;
BA_REL_ "GenSigTimeoutTime" BU_SG_REL_ SR_LR SG_ 1541 Trailer2Data_Type 30000;
BA_REL_ "GenSigFirstTimeoutTime" BU_SG_REL_ SR_LF SG_ 1541 Trailer2Data_Type 60000;
BA_REL_ "GenSigTimeoutTime" BU_SG_REL_ SR_LF SG_ 1541 Trailer2Data_Type 30000;
BA_REL_ "GenSigFirstTimeoutTime" BU_SG_REL_ SR_RF SG_ 1541 Trailer2Data_Type 60000;
BA_REL_ "GenSigTimeoutTime" BU_SG_REL_ SR_RF SG_ 1541 Trailer2Data_Type 30000;
BA_REL_ "GenSigFirstTimeoutTime" BU_SG_REL_ SR_RR SG_ 1541 Trailer1Data_FrAxleCount 60000;
BA_REL_ "GenSigTimeoutTime" BU_SG_REL_ SR_RR SG_ 1541 Trailer1Data_FrAxleCount 30000;
BA_REL_ "GenSigFirstTimeoutTime" BU_SG_REL_ SR_LR SG_ 1541 Trailer1Data_FrAxleCount 60000;
BA_REL_ "GenSigTimeoutTime" BU_SG_REL_ SR_LR SG_ 1541 Trailer1Data_FrAxleCount 30000;
BA_REL_ "GenSigFirstTimeoutTime" BU_SG_REL_ SR_LF SG_ 1541 Trailer1Data_FrAxleCount 60000;
BA_REL_ "GenSigTimeoutTime" BU_SG_REL_ SR_LF SG_ 1541 Trailer1Data_FrAxleCount 30000;
BA_REL_ "GenSigFirstTimeoutTime" BU_SG_REL_ SR_RF SG_ 1541 Trailer1Data_FrAxleCount 60000;
BA_REL_ "GenSigTimeoutTime" BU_SG_REL_ SR_RF SG_ 1541 Trailer1Data_FrAxleCount 30000;
BA_REL_ "GenSigFirstTimeoutTime" BU_SG_REL_ SR_RR SG_ 1541 Trailer5Data_DrawbarLength 60000;
BA_REL_ "GenSigTimeoutTime" BU_SG_REL_ SR_RR SG_ 1541 Trailer5Data_DrawbarLength 30000;
BA_REL_ "GenSigFirstTimeoutTime" BU_SG_REL_ SR_RF SG_ 1541 Trailer5Data_DrawbarLength 60000;
BA_REL_ "GenSigTimeoutTime" BU_SG_REL_ SR_RF SG_ 1541 Trailer5Data_DrawbarLength 30000;
BA_REL_ "GenSigFirstTimeoutTime" BU_SG_REL_ SR_LR SG_ 1541 Trailer5Data_DrawbarLength 60000;
BA_REL_ "GenSigTimeoutTime" BU_SG_REL_ SR_LR SG_ 1541 Trailer5Data_DrawbarLength 30000;
BA_REL_ "GenSigFirstTimeoutTime" BU_SG_REL_ SR_LF SG_ 1541 Trailer5Data_DrawbarLength 60000;
BA_REL_ "GenSigTimeoutTime" BU_SG_REL_ SR_LF SG_ 1541 Trailer5Data_DrawbarLength 30000;
BA_REL_ "GenSigFirstTimeoutTime" BU_SG_REL_ SR_LR SG_ 1541 Trailer1Data_Type 60000;
BA_REL_ "GenSigTimeoutTime" BU_SG_REL_ SR_LR SG_ 1541 Trailer1Data_Type 30000;
BA_REL_ "GenSigFirstTimeoutTime" BU_SG_REL_ SR_RR SG_ 1541 Trailer1Data_Type 60000;
BA_REL_ "GenSigTimeoutTime" BU_SG_REL_ SR_RR SG_ 1541 Trailer1Data_Type 30000;
BA_REL_ "GenSigFirstTimeoutTime" BU_SG_REL_ SR_LF SG_ 1541 Trailer1Data_Type 60000;
BA_REL_ "GenSigTimeoutTime" BU_SG_REL_ SR_LF SG_ 1541 Trailer1Data_Type 30000;
BA_REL_ "GenSigFirstTimeoutTime" BU_SG_REL_ SR_RF SG_ 1541 Trailer1Data_Type 60000;
BA_REL_ "GenSigTimeoutTime" BU_SG_REL_ SR_RF SG_ 1541 Trailer1Data_Type 30000;
BA_REL_ "GenSigFirstTimeoutTime" BU_SG_REL_ SR_LF SG_ 1541 Trailer1Data_DrawbarLength 60000;
BA_REL_ "GenSigTimeoutTime" BU_SG_REL_ SR_LF SG_ 1541 Trailer1Data_DrawbarLength 30000;
BA_REL_ "GenSigFirstTimeoutTime" BU_SG_REL_ SR_LR SG_ 1541 Trailer1Data_DrawbarLength 60000;
BA_REL_ "GenSigTimeoutTime" BU_SG_REL_ SR_LR SG_ 1541 Trailer1Data_DrawbarLength 30000;
BA_REL_ "GenSigFirstTimeoutTime" BU_SG_REL_ SR_RF SG_ 1541 Trailer1Data_DrawbarLength 60000;
BA_REL_ "GenSigTimeoutTime" BU_SG_REL_ SR_RF SG_ 1541 Trailer1Data_DrawbarLength 30000;
BA_REL_ "GenSigFirstTimeoutTime" BU_SG_REL_ SR_RR SG_ 1541 Trailer1Data_DrawbarLength 60000;
BA_REL_ "GenSigTimeoutTime" BU_SG_REL_ SR_RR SG_ 1541 Trailer1Data_DrawbarLength 30000;
BA_REL_ "GenSigFirstTimeoutTime" BU_SG_REL_ SR_LF SG_ 1541 Trailer4Data_FrAxleCount 60000;
BA_REL_ "GenSigTimeoutTime" BU_SG_REL_ SR_LF SG_ 1541 Trailer4Data_FrAxleCount 30000;
BA_REL_ "GenSigFirstTimeoutTime" BU_SG_REL_ SR_LR SG_ 1541 Trailer4Data_FrAxleCount 60000;
BA_REL_ "GenSigTimeoutTime" BU_SG_REL_ SR_LR SG_ 1541 Trailer4Data_FrAxleCount 30000;
BA_REL_ "GenSigFirstTimeoutTime" BU_SG_REL_ SR_RR SG_ 1541 Trailer4Data_FrAxleCount 60000;
BA_REL_ "GenSigTimeoutTime" BU_SG_REL_ SR_RR SG_ 1541 Trailer4Data_FrAxleCount 30000;
BA_REL_ "GenSigFirstTimeoutTime" BU_SG_REL_ SR_RF SG_ 1541 Trailer4Data_FrAxleCount 60000;
BA_REL_ "GenSigTimeoutTime" BU_SG_REL_ SR_RF SG_ 1541 Trailer4Data_FrAxleCount 30000;
BA_REL_ "GenSigFirstTimeoutTime" BU_SG_REL_ SR_RF SG_ 1541 Trailer2Data_Length 60000;
BA_REL_ "GenSigTimeoutTime" BU_SG_REL_ SR_RF SG_ 1541 Trailer2Data_Length 30000;
BA_REL_ "GenSigFirstTimeoutTime" BU_SG_REL_ SR_LF SG_ 1541 Trailer2Data_Length 60000;
BA_REL_ "GenSigTimeoutTime" BU_SG_REL_ SR_LF SG_ 1541 Trailer2Data_Length 30000;
BA_REL_ "GenSigFirstTimeoutTime" BU_SG_REL_ SR_RR SG_ 1541 Trailer2Data_Length 60000;
BA_REL_ "GenSigTimeoutTime" BU_SG_REL_ SR_RR SG_ 1541 Trailer2Data_Length 30000;
BA_REL_ "GenSigFirstTimeoutTime" BU_SG_REL_ SR_LR SG_ 1541 Trailer2Data_Length 60000;
BA_REL_ "GenSigTimeoutTime" BU_SG_REL_ SR_LR SG_ 1541 Trailer2Data_Length 30000;
BA_REL_ "GenSigFirstTimeoutTime" BU_SG_REL_ SR_LR SG_ 1541 Trailer4Data_DrawbarLength 60000;
BA_REL_ "GenSigTimeoutTime" BU_SG_REL_ SR_LR SG_ 1541 Trailer4Data_DrawbarLength 30000;
BA_REL_ "GenSigFirstTimeoutTime" BU_SG_REL_ SR_RR SG_ 1541 Trailer4Data_DrawbarLength 60000;
BA_REL_ "GenSigTimeoutTime" BU_SG_REL_ SR_RR SG_ 1541 Trailer4Data_DrawbarLength 30000;
BA_REL_ "GenSigFirstTimeoutTime" BU_SG_REL_ SR_RF SG_ 1541 Trailer4Data_DrawbarLength 60000;
BA_REL_ "GenSigTimeoutTime" BU_SG_REL_ SR_RF SG_ 1541 Trailer4Data_DrawbarLength 30000;
BA_REL_ "GenSigFirstTimeoutTime" BU_SG_REL_ SR_LF SG_ 1541 Trailer4Data_DrawbarLength 60000;
BA_REL_ "GenSigTimeoutTime" BU_SG_REL_ SR_LF SG_ 1541 Trailer4Data_DrawbarLength 30000;
BA_REL_ "GenSigFirstTimeoutTime" BU_SG_REL_ SR_LR SG_ 1543 VIN_DACU_Byte06 60000;
BA_REL_ "GenSigTimeoutTime" BU_SG_REL_ SR_LR SG_ 1543 VIN_DACU_Byte06 30000;
BA_REL_ "GenSigFirstTimeoutTime" BU_SG_REL_ SR_LF SG_ 1543 VIN_DACU_Byte06 60000;
BA_REL_ "GenSigTimeoutTime" BU_SG_REL_ SR_LF SG_ 1543 VIN_DACU_Byte06 30000;
BA_REL_ "GenSigFirstTimeoutTime" BU_SG_REL_ SR_RR SG_ 1543 VIN_DACU_Byte06 60000;
BA_REL_ "GenSigTimeoutTime" BU_SG_REL_ SR_RR SG_ 1543 VIN_DACU_Byte06 30000;
BA_REL_ "GenSigFirstTimeoutTime" BU_SG_REL_ SR_RF SG_ 1543 VIN_DACU_Byte06 60000;
BA_REL_ "GenSigTimeoutTime" BU_SG_REL_ SR_RF SG_ 1543 VIN_DACU_Byte06 30000;
BA_REL_ "GenSigFirstTimeoutTime" BU_SG_REL_ SR_RR SG_ 1543 VIN_DACU_Byte08 60000;
BA_REL_ "GenSigTimeoutTime" BU_SG_REL_ SR_RR SG_ 1543 VIN_DACU_Byte08 30000;
BA_REL_ "GenSigFirstTimeoutTime" BU_SG_REL_ SR_LR SG_ 1543 VIN_DACU_Byte08 60000;
BA_REL_ "GenSigTimeoutTime" BU_SG_REL_ SR_LR SG_ 1543 VIN_DACU_Byte08 30000;
BA_REL_ "GenSigFirstTimeoutTime" BU_SG_REL_ SR_LF SG_ 1543 VIN_DACU_Byte08 60000;
BA_REL_ "GenSigTimeoutTime" BU_SG_REL_ SR_LF SG_ 1543 VIN_DACU_Byte08 30000;
BA_REL_ "GenSigFirstTimeoutTime" BU_SG_REL_ SR_RF SG_ 1543 VIN_DACU_Byte08 60000;
BA_REL_ "GenSigTimeoutTime" BU_SG_REL_ SR_RF SG_ 1543 VIN_DACU_Byte08 30000;
BA_REL_ "GenSigFirstTimeoutTime" BU_SG_REL_ SR_RR SG_ 1543 VIN_DACU_Byte00 60000;
BA_REL_ "GenSigTimeoutTime" BU_SG_REL_ SR_RR SG_ 1543 VIN_DACU_Byte00 30000;
BA_REL_ "GenSigFirstTimeoutTime" BU_SG_REL_ SR_RF SG_ 1543 VIN_DACU_Byte00 60000;
BA_REL_ "GenSigTimeoutTime" BU_SG_REL_ SR_RF SG_ 1543 VIN_DACU_Byte00 30000;
BA_REL_ "GenSigFirstTimeoutTime" BU_SG_REL_ SR_LF SG_ 1543 VIN_DACU_Byte00 60000;
BA_REL_ "GenSigTimeoutTime" BU_SG_REL_ SR_LF SG_ 1543 VIN_DACU_Byte00 30000;
BA_REL_ "GenSigFirstTimeoutTime" BU_SG_REL_ SR_LR SG_ 1543 VIN_DACU_Byte00 60000;
BA_REL_ "GenSigTimeoutTime" BU_SG_REL_ SR_LR SG_ 1543 VIN_DACU_Byte00 30000;
BA_REL_ "GenSigFirstTimeoutTime" BU_SG_REL_ SR_LF SG_ 1543 VIN_DACU_Byte16 60000;
BA_REL_ "GenSigTimeoutTime" BU_SG_REL_ SR_LF SG_ 1543 VIN_DACU_Byte16 30000;
BA_REL_ "GenSigFirstTimeoutTime" BU_SG_REL_ SR_LR SG_ 1543 VIN_DACU_Byte16 60000;
BA_REL_ "GenSigTimeoutTime" BU_SG_REL_ SR_LR SG_ 1543 VIN_DACU_Byte16 30000;
BA_REL_ "GenSigFirstTimeoutTime" BU_SG_REL_ SR_RF SG_ 1543 VIN_DACU_Byte16 60000;
BA_REL_ "GenSigTimeoutTime" BU_SG_REL_ SR_RF SG_ 1543 VIN_DACU_Byte16 30000;
BA_REL_ "GenSigFirstTimeoutTime" BU_SG_REL_ SR_RR SG_ 1543 VIN_DACU_Byte16 60000;
BA_REL_ "GenSigTimeoutTime" BU_SG_REL_ SR_RR SG_ 1543 VIN_DACU_Byte16 30000;
BA_REL_ "GenSigFirstTimeoutTime" BU_SG_REL_ SR_RR SG_ 1543 VIN_DACU_Byte04 60000;
BA_REL_ "GenSigTimeoutTime" BU_SG_REL_ SR_RR SG_ 1543 VIN_DACU_Byte04 30000;
BA_REL_ "GenSigFirstTimeoutTime" BU_SG_REL_ SR_LR SG_ 1543 VIN_DACU_Byte04 60000;
BA_REL_ "GenSigTimeoutTime" BU_SG_REL_ SR_LR SG_ 1543 VIN_DACU_Byte04 30000;
BA_REL_ "GenSigFirstTimeoutTime" BU_SG_REL_ SR_RF SG_ 1543 VIN_DACU_Byte04 60000;
BA_REL_ "GenSigTimeoutTime" BU_SG_REL_ SR_RF SG_ 1543 VIN_DACU_Byte04 30000;
BA_REL_ "GenSigFirstTimeoutTime" BU_SG_REL_ SR_LF SG_ 1543 VIN_DACU_Byte04 60000;
BA_REL_ "GenSigTimeoutTime" BU_SG_REL_ SR_LF SG_ 1543 VIN_DACU_Byte04 30000;
BA_REL_ "GenSigFirstTimeoutTime" BU_SG_REL_ SR_LR SG_ 1543 VIN_DACU_Byte10 60000;
BA_REL_ "GenSigTimeoutTime" BU_SG_REL_ SR_LR SG_ 1543 VIN_DACU_Byte10 30000;
BA_REL_ "GenSigFirstTimeoutTime" BU_SG_REL_ SR_LF SG_ 1543 VIN_DACU_Byte10 60000;
BA_REL_ "GenSigTimeoutTime" BU_SG_REL_ SR_LF SG_ 1543 VIN_DACU_Byte10 30000;
BA_REL_ "GenSigFirstTimeoutTime" BU_SG_REL_ SR_RF SG_ 1543 VIN_DACU_Byte10 60000;
BA_REL_ "GenSigTimeoutTime" BU_SG_REL_ SR_RF SG_ 1543 VIN_DACU_Byte10 30000;
BA_REL_ "GenSigFirstTimeoutTime" BU_SG_REL_ SR_RR SG_ 1543 VIN_DACU_Byte10 60000;
BA_REL_ "GenSigTimeoutTime" BU_SG_REL_ SR_RR SG_ 1543 VIN_DACU_Byte10 30000;
BA_REL_ "GenSigFirstTimeoutTime" BU_SG_REL_ SR_LF SG_ 1543 VIN_DACU_Byte14 60000;
BA_REL_ "GenSigTimeoutTime" BU_SG_REL_ SR_LF SG_ 1543 VIN_DACU_Byte14 30000;
BA_REL_ "GenSigFirstTimeoutTime" BU_SG_REL_ SR_RR SG_ 1543 VIN_DACU_Byte14 60000;
BA_REL_ "GenSigTimeoutTime" BU_SG_REL_ SR_RR SG_ 1543 VIN_DACU_Byte14 30000;
BA_REL_ "GenSigFirstTimeoutTime" BU_SG_REL_ SR_LR SG_ 1543 VIN_DACU_Byte14 60000;
BA_REL_ "GenSigTimeoutTime" BU_SG_REL_ SR_LR SG_ 1543 VIN_DACU_Byte14 30000;
BA_REL_ "GenSigFirstTimeoutTime" BU_SG_REL_ SR_RF SG_ 1543 VIN_DACU_Byte14 60000;
BA_REL_ "GenSigTimeoutTime" BU_SG_REL_ SR_RF SG_ 1543 VIN_DACU_Byte14 30000;
BA_REL_ "GenSigFirstTimeoutTime" BU_SG_REL_ SR_LF SG_ 1543 VIN_DACU_Byte12 60000;
BA_REL_ "GenSigTimeoutTime" BU_SG_REL_ SR_LF SG_ 1543 VIN_DACU_Byte12 30000;
BA_REL_ "GenSigFirstTimeoutTime" BU_SG_REL_ SR_RF SG_ 1543 VIN_DACU_Byte12 60000;
BA_REL_ "GenSigTimeoutTime" BU_SG_REL_ SR_RF SG_ 1543 VIN_DACU_Byte12 30000;
BA_REL_ "GenSigFirstTimeoutTime" BU_SG_REL_ SR_LR SG_ 1543 VIN_DACU_Byte12 60000;
BA_REL_ "GenSigTimeoutTime" BU_SG_REL_ SR_LR SG_ 1543 VIN_DACU_Byte12 30000;
BA_REL_ "GenSigFirstTimeoutTime" BU_SG_REL_ SR_RR SG_ 1543 VIN_DACU_Byte12 60000;
BA_REL_ "GenSigTimeoutTime" BU_SG_REL_ SR_RR SG_ 1543 VIN_DACU_Byte12 30000;
BA_REL_ "GenSigFirstTimeoutTime" BU_SG_REL_ SR_RF SG_ 1543 VIN_DACU_Byte07 60000;
BA_REL_ "GenSigTimeoutTime" BU_SG_REL_ SR_RF SG_ 1543 VIN_DACU_Byte07 30000;
BA_REL_ "GenSigFirstTimeoutTime" BU_SG_REL_ SR_LF SG_ 1543 VIN_DACU_Byte07 60000;
BA_REL_ "GenSigTimeoutTime" BU_SG_REL_ SR_LF SG_ 1543 VIN_DACU_Byte07 30000;
BA_REL_ "GenSigFirstTimeoutTime" BU_SG_REL_ SR_LR SG_ 1543 VIN_DACU_Byte07 60000;
BA_REL_ "GenSigTimeoutTime" BU_SG_REL_ SR_LR SG_ 1543 VIN_DACU_Byte07 30000;
BA_REL_ "GenSigFirstTimeoutTime" BU_SG_REL_ SR_RR SG_ 1543 VIN_DACU_Byte07 60000;
BA_REL_ "GenSigTimeoutTime" BU_SG_REL_ SR_RR SG_ 1543 VIN_DACU_Byte07 30000;
BA_REL_ "GenSigFirstTimeoutTime" BU_SG_REL_ SR_RR SG_ 1543 VIN_DACU_Byte15 60000;
BA_REL_ "GenSigTimeoutTime" BU_SG_REL_ SR_RR SG_ 1543 VIN_DACU_Byte15 30000;
BA_REL_ "GenSigFirstTimeoutTime" BU_SG_REL_ SR_LR SG_ 1543 VIN_DACU_Byte15 60000;
BA_REL_ "GenSigTimeoutTime" BU_SG_REL_ SR_LR SG_ 1543 VIN_DACU_Byte15 30000;
BA_REL_ "GenSigFirstTimeoutTime" BU_SG_REL_ SR_LF SG_ 1543 VIN_DACU_Byte15 60000;
BA_REL_ "GenSigTimeoutTime" BU_SG_REL_ SR_LF SG_ 1543 VIN_DACU_Byte15 30000;
BA_REL_ "GenSigFirstTimeoutTime" BU_SG_REL_ SR_RF SG_ 1543 VIN_DACU_Byte15 60000;
BA_REL_ "GenSigTimeoutTime" BU_SG_REL_ SR_RF SG_ 1543 VIN_DACU_Byte15 30000;
BA_REL_ "GenSigFirstTimeoutTime" BU_SG_REL_ SR_LR SG_ 1543 VIN_DACU_Byte09 60000;
BA_REL_ "GenSigTimeoutTime" BU_SG_REL_ SR_LR SG_ 1543 VIN_DACU_Byte09 30000;
BA_REL_ "GenSigFirstTimeoutTime" BU_SG_REL_ SR_RR SG_ 1543 VIN_DACU_Byte09 60000;
BA_REL_ "GenSigTimeoutTime" BU_SG_REL_ SR_RR SG_ 1543 VIN_DACU_Byte09 30000;
BA_REL_ "GenSigFirstTimeoutTime" BU_SG_REL_ SR_LF SG_ 1543 VIN_DACU_Byte09 60000;
BA_REL_ "GenSigTimeoutTime" BU_SG_REL_ SR_LF SG_ 1543 VIN_DACU_Byte09 30000;
BA_REL_ "GenSigFirstTimeoutTime" BU_SG_REL_ SR_RF SG_ 1543 VIN_DACU_Byte09 60000;
BA_REL_ "GenSigTimeoutTime" BU_SG_REL_ SR_RF SG_ 1543 VIN_DACU_Byte09 30000;
BA_REL_ "GenSigFirstTimeoutTime" BU_SG_REL_ SR_LF SG_ 1543 VIN_DACU_Byte05 60000;
BA_REL_ "GenSigTimeoutTime" BU_SG_REL_ SR_LF SG_ 1543 VIN_DACU_Byte05 30000;
BA_REL_ "GenSigFirstTimeoutTime" BU_SG_REL_ SR_RR SG_ 1543 VIN_DACU_Byte05 60000;
BA_REL_ "GenSigTimeoutTime" BU_SG_REL_ SR_RR SG_ 1543 VIN_DACU_Byte05 30000;
BA_REL_ "GenSigFirstTimeoutTime" BU_SG_REL_ SR_LR SG_ 1543 VIN_DACU_Byte05 60000;
BA_REL_ "GenSigTimeoutTime" BU_SG_REL_ SR_LR SG_ 1543 VIN_DACU_Byte05 30000;
BA_REL_ "GenSigFirstTimeoutTime" BU_SG_REL_ SR_RF SG_ 1543 VIN_DACU_Byte05 60000;
BA_REL_ "GenSigTimeoutTime" BU_SG_REL_ SR_RF SG_ 1543 VIN_DACU_Byte05 30000;
BA_REL_ "GenSigFirstTimeoutTime" BU_SG_REL_ SR_LR SG_ 1543 VIN_DACU_Byte02 60000;
BA_REL_ "GenSigTimeoutTime" BU_SG_REL_ SR_LR SG_ 1543 VIN_DACU_Byte02 30000;
BA_REL_ "GenSigFirstTimeoutTime" BU_SG_REL_ SR_LF SG_ 1543 VIN_DACU_Byte02 60000;
BA_REL_ "GenSigTimeoutTime" BU_SG_REL_ SR_LF SG_ 1543 VIN_DACU_Byte02 30000;
BA_REL_ "GenSigFirstTimeoutTime" BU_SG_REL_ SR_RR SG_ 1543 VIN_DACU_Byte02 60000;
BA_REL_ "GenSigTimeoutTime" BU_SG_REL_ SR_RR SG_ 1543 VIN_DACU_Byte02 30000;
BA_REL_ "GenSigFirstTimeoutTime" BU_SG_REL_ SR_RF SG_ 1543 VIN_DACU_Byte02 60000;
BA_REL_ "GenSigTimeoutTime" BU_SG_REL_ SR_RF SG_ 1543 VIN_DACU_Byte02 30000;
BA_REL_ "GenSigFirstTimeoutTime" BU_SG_REL_ SR_LR SG_ 1543 VIN_DACU_Byte11 60000;
BA_REL_ "GenSigTimeoutTime" BU_SG_REL_ SR_LR SG_ 1543 VIN_DACU_Byte11 30000;
BA_REL_ "GenSigFirstTimeoutTime" BU_SG_REL_ SR_RF SG_ 1543 VIN_DACU_Byte11 60000;
BA_REL_ "GenSigTimeoutTime" BU_SG_REL_ SR_RF SG_ 1543 VIN_DACU_Byte11 30000;
BA_REL_ "GenSigFirstTimeoutTime" BU_SG_REL_ SR_LF SG_ 1543 VIN_DACU_Byte11 60000;
BA_REL_ "GenSigTimeoutTime" BU_SG_REL_ SR_LF SG_ 1543 VIN_DACU_Byte11 30000;
BA_REL_ "GenSigFirstTimeoutTime" BU_SG_REL_ SR_RR SG_ 1543 VIN_DACU_Byte11 60000;
BA_REL_ "GenSigTimeoutTime" BU_SG_REL_ SR_RR SG_ 1543 VIN_DACU_Byte11 30000;
BA_REL_ "GenSigFirstTimeoutTime" BU_SG_REL_ SR_RR SG_ 1543 VIN_DACU_Byte01 60000;
BA_REL_ "GenSigTimeoutTime" BU_SG_REL_ SR_RR SG_ 1543 VIN_DACU_Byte01 30000;
BA_REL_ "GenSigFirstTimeoutTime" BU_SG_REL_ SR_RF SG_ 1543 VIN_DACU_Byte01 60000;
BA_REL_ "GenSigTimeoutTime" BU_SG_REL_ SR_RF SG_ 1543 VIN_DACU_Byte01 30000;
BA_REL_ "GenSigFirstTimeoutTime" BU_SG_REL_ SR_LF SG_ 1543 VIN_DACU_Byte01 60000;
BA_REL_ "GenSigTimeoutTime" BU_SG_REL_ SR_LF SG_ 1543 VIN_DACU_Byte01 30000;
BA_REL_ "GenSigFirstTimeoutTime" BU_SG_REL_ SR_LR SG_ 1543 VIN_DACU_Byte01 60000;
BA_REL_ "GenSigTimeoutTime" BU_SG_REL_ SR_LR SG_ 1543 VIN_DACU_Byte01 30000;
BA_REL_ "GenSigFirstTimeoutTime" BU_SG_REL_ SR_RF SG_ 1543 VIN_DACU_Byte03 60000;
BA_REL_ "GenSigTimeoutTime" BU_SG_REL_ SR_RF SG_ 1543 VIN_DACU_Byte03 30000;
BA_REL_ "GenSigFirstTimeoutTime" BU_SG_REL_ SR_LF SG_ 1543 VIN_DACU_Byte03 60000;
BA_REL_ "GenSigTimeoutTime" BU_SG_REL_ SR_LF SG_ 1543 VIN_DACU_Byte03 30000;
BA_REL_ "GenSigFirstTimeoutTime" BU_SG_REL_ SR_LR SG_ 1543 VIN_DACU_Byte03 60000;
BA_REL_ "GenSigTimeoutTime" BU_SG_REL_ SR_LR SG_ 1543 VIN_DACU_Byte03 30000;
BA_REL_ "GenSigFirstTimeoutTime" BU_SG_REL_ SR_RR SG_ 1543 VIN_DACU_Byte03 60000;
BA_REL_ "GenSigTimeoutTime" BU_SG_REL_ SR_RR SG_ 1543 VIN_DACU_Byte03 30000;
BA_REL_ "GenSigFirstTimeoutTime" BU_SG_REL_ SR_LR SG_ 1543 VIN_DACU_Byte13 60000;
BA_REL_ "GenSigTimeoutTime" BU_SG_REL_ SR_LR SG_ 1543 VIN_DACU_Byte13 30000;
BA_REL_ "GenSigFirstTimeoutTime" BU_SG_REL_ SR_RR SG_ 1543 VIN_DACU_Byte13 60000;
BA_REL_ "GenSigTimeoutTime" BU_SG_REL_ SR_RR SG_ 1543 VIN_DACU_Byte13 30000;
BA_REL_ "GenSigFirstTimeoutTime" BU_SG_REL_ SR_LF SG_ 1543 VIN_DACU_Byte13 60000;
BA_REL_ "GenSigTimeoutTime" BU_SG_REL_ SR_LF SG_ 1543 VIN_DACU_Byte13 30000;
BA_REL_ "GenSigFirstTimeoutTime" BU_SG_REL_ SR_RF SG_ 1543 VIN_DACU_Byte13 60000;
BA_REL_ "GenSigTimeoutTime" BU_SG_REL_ SR_RF SG_ 1543 VIN_DACU_Byte13 30000;
BA_REL_ "GenSigFirstTimeoutTime" BU_SG_REL_ SR_LR SG_ 1265 MinutesUTC 6000;
BA_REL_ "GenSigTimeoutTime" BU_SG_REL_ SR_LR SG_ 1265 MinutesUTC 1500;
BA_REL_ "GenSigFirstTimeoutTime" BU_SG_REL_ SR_LF SG_ 1265 MinutesUTC 6000;
BA_REL_ "GenSigTimeoutTime" BU_SG_REL_ SR_LF SG_ 1265 MinutesUTC 1500;
BA_REL_ "GenSigFirstTimeoutTime" BU_SG_REL_ SR_RF SG_ 1265 MinutesUTC 6000;
BA_REL_ "GenSigTimeoutTime" BU_SG_REL_ SR_RF SG_ 1265 MinutesUTC 1500;
BA_REL_ "GenSigFirstTimeoutTime" BU_SG_REL_ SR_RR SG_ 1265 MinutesUTC 6000;
BA_REL_ "GenSigTimeoutTime" BU_SG_REL_ SR_RR SG_ 1265 MinutesUTC 1500;
BA_REL_ "GenSigFirstTimeoutTime" BU_SG_REL_ SR_RR SG_ 1265 Trailer1GeometricData_Content 6000;
BA_REL_ "GenSigTimeoutTime" BU_SG_REL_ SR_RR SG_ 1265 Trailer1GeometricData_Content 1500;
BA_REL_ "GenSigFirstTimeoutTime" BU_SG_REL_ SR_LR SG_ 1265 Trailer1GeometricData_Content 6000;
BA_REL_ "GenSigTimeoutTime" BU_SG_REL_ SR_LR SG_ 1265 Trailer1GeometricData_Content 1500;
BA_REL_ "GenSigFirstTimeoutTime" BU_SG_REL_ SR_RF SG_ 1265 Trailer1GeometricData_Content 6000;
BA_REL_ "GenSigTimeoutTime" BU_SG_REL_ SR_RF SG_ 1265 Trailer1GeometricData_Content 1500;
BA_REL_ "GenSigFirstTimeoutTime" BU_SG_REL_ SR_LF SG_ 1265 Trailer1GeometricData_Content 6000;
BA_REL_ "GenSigTimeoutTime" BU_SG_REL_ SR_LF SG_ 1265 Trailer1GeometricData_Content 1500;
BA_REL_ "GenSigFirstTimeoutTime" BU_SG_REL_ SR_RR SG_ 1265 DayUTC 6000;
BA_REL_ "GenSigTimeoutTime" BU_SG_REL_ SR_RR SG_ 1265 DayUTC 1500;
BA_REL_ "GenSigFirstTimeoutTime" BU_SG_REL_ SR_LR SG_ 1265 DayUTC 6000;
BA_REL_ "GenSigTimeoutTime" BU_SG_REL_ SR_LR SG_ 1265 DayUTC 1500;
BA_REL_ "GenSigFirstTimeoutTime" BU_SG_REL_ SR_LF SG_ 1265 DayUTC 6000;
BA_REL_ "GenSigTimeoutTime" BU_SG_REL_ SR_LF SG_ 1265 DayUTC 1500;
BA_REL_ "GenSigFirstTimeoutTime" BU_SG_REL_ SR_RF SG_ 1265 DayUTC 6000;
BA_REL_ "GenSigTimeoutTime" BU_SG_REL_ SR_RF SG_ 1265 DayUTC 1500;
BA_REL_ "GenSigFirstTimeoutTime" BU_SG_REL_ SR_RF SG_ 1265 Trailer2GeometricData_Content 6000;
BA_REL_ "GenSigTimeoutTime" BU_SG_REL_ SR_RF SG_ 1265 Trailer2GeometricData_Content 1500;
BA_REL_ "GenSigFirstTimeoutTime" BU_SG_REL_ SR_LF SG_ 1265 Trailer2GeometricData_Content 6000;
BA_REL_ "GenSigTimeoutTime" BU_SG_REL_ SR_LF SG_ 1265 Trailer2GeometricData_Content 1500;
BA_REL_ "GenSigFirstTimeoutTime" BU_SG_REL_ SR_RR SG_ 1265 Trailer2GeometricData_Content 6000;
BA_REL_ "GenSigTimeoutTime" BU_SG_REL_ SR_RR SG_ 1265 Trailer2GeometricData_Content 1500;
BA_REL_ "GenSigFirstTimeoutTime" BU_SG_REL_ SR_LR SG_ 1265 Trailer2GeometricData_Content 6000;
BA_REL_ "GenSigTimeoutTime" BU_SG_REL_ SR_LR SG_ 1265 Trailer2GeometricData_Content 1500;
BA_REL_ "GenSigFirstTimeoutTime" BU_SG_REL_ SR_RF SG_ 1265 TotalVehicleDistanceHighRes 6000;
BA_REL_ "GenSigTimeoutTime" BU_SG_REL_ SR_RF SG_ 1265 TotalVehicleDistanceHighRes 1500;
BA_REL_ "GenSigFirstTimeoutTime" BU_SG_REL_ SR_LR SG_ 1265 TotalVehicleDistanceHighRes 6000;
BA_REL_ "GenSigTimeoutTime" BU_SG_REL_ SR_LR SG_ 1265 TotalVehicleDistanceHighRes 1500;
BA_REL_ "GenSigFirstTimeoutTime" BU_SG_REL_ SR_RR SG_ 1265 TotalVehicleDistanceHighRes 6000;
BA_REL_ "GenSigTimeoutTime" BU_SG_REL_ SR_RR SG_ 1265 TotalVehicleDistanceHighRes 1500;
BA_REL_ "GenSigFirstTimeoutTime" BU_SG_REL_ SR_LF SG_ 1265 TotalVehicleDistanceHighRes 6000;
BA_REL_ "GenSigTimeoutTime" BU_SG_REL_ SR_LF SG_ 1265 TotalVehicleDistanceHighRes 1500;
BA_REL_ "GenSigFirstTimeoutTime" BU_SG_REL_ SR_RR SG_ 1265 Trailer4GeometricData_Content 6000;
BA_REL_ "GenSigTimeoutTime" BU_SG_REL_ SR_RR SG_ 1265 Trailer4GeometricData_Content 1500;
BA_REL_ "GenSigFirstTimeoutTime" BU_SG_REL_ SR_LF SG_ 1265 Trailer4GeometricData_Content 6000;
BA_REL_ "GenSigTimeoutTime" BU_SG_REL_ SR_LF SG_ 1265 Trailer4GeometricData_Content 1500;
BA_REL_ "GenSigFirstTimeoutTime" BU_SG_REL_ SR_RF SG_ 1265 Trailer4GeometricData_Content 6000;
BA_REL_ "GenSigTimeoutTime" BU_SG_REL_ SR_RF SG_ 1265 Trailer4GeometricData_Content 1500;
BA_REL_ "GenSigFirstTimeoutTime" BU_SG_REL_ SR_LR SG_ 1265 Trailer4GeometricData_Content 6000;
BA_REL_ "GenSigTimeoutTime" BU_SG_REL_ SR_LR SG_ 1265 Trailer4GeometricData_Content 1500;
BA_REL_ "GenSigFirstTimeoutTime" BU_SG_REL_ SR_RF SG_ 1265 PusherAxleLoad 6000;
BA_REL_ "GenSigTimeoutTime" BU_SG_REL_ SR_RF SG_ 1265 PusherAxleLoad 1500;
BA_REL_ "GenSigFirstTimeoutTime" BU_SG_REL_ SR_LF SG_ 1265 PusherAxleLoad 6000;
BA_REL_ "GenSigTimeoutTime" BU_SG_REL_ SR_LF SG_ 1265 PusherAxleLoad 1500;
BA_REL_ "GenSigFirstTimeoutTime" BU_SG_REL_ SR_LR SG_ 1265 PusherAxleLoad 6000;
BA_REL_ "GenSigTimeoutTime" BU_SG_REL_ SR_LR SG_ 1265 PusherAxleLoad 1500;
BA_REL_ "GenSigFirstTimeoutTime" BU_SG_REL_ SR_RR SG_ 1265 PusherAxleLoad 6000;
BA_REL_ "GenSigTimeoutTime" BU_SG_REL_ SR_RR SG_ 1265 PusherAxleLoad 1500;
BA_REL_ "GenSigFirstTimeoutTime" BU_SG_REL_ SR_LF SG_ 1265 DriveAxleLoad 6000;
BA_REL_ "GenSigTimeoutTime" BU_SG_REL_ SR_LF SG_ 1265 DriveAxleLoad 1500;
BA_REL_ "GenSigFirstTimeoutTime" BU_SG_REL_ SR_RR SG_ 1265 DriveAxleLoad 6000;
BA_REL_ "GenSigTimeoutTime" BU_SG_REL_ SR_RR SG_ 1265 DriveAxleLoad 1500;
BA_REL_ "GenSigFirstTimeoutTime" BU_SG_REL_ SR_RF SG_ 1265 DriveAxleLoad 6000;
BA_REL_ "GenSigTimeoutTime" BU_SG_REL_ SR_RF SG_ 1265 DriveAxleLoad 1500;
BA_REL_ "GenSigFirstTimeoutTime" BU_SG_REL_ SR_LR SG_ 1265 DriveAxleLoad 6000;
BA_REL_ "GenSigTimeoutTime" BU_SG_REL_ SR_LR SG_ 1265 DriveAxleLoad 1500;
BA_REL_ "GenSigFirstTimeoutTime" BU_SG_REL_ SR_LR SG_ 1265 FrontAxle1Load 6000;
BA_REL_ "GenSigTimeoutTime" BU_SG_REL_ SR_LR SG_ 1265 FrontAxle1Load 1500;
BA_REL_ "GenSigFirstTimeoutTime" BU_SG_REL_ SR_RF SG_ 1265 FrontAxle1Load 6000;
BA_REL_ "GenSigTimeoutTime" BU_SG_REL_ SR_RF SG_ 1265 FrontAxle1Load 1500;
BA_REL_ "GenSigFirstTimeoutTime" BU_SG_REL_ SR_LF SG_ 1265 FrontAxle1Load 6000;
BA_REL_ "GenSigTimeoutTime" BU_SG_REL_ SR_LF SG_ 1265 FrontAxle1Load 1500;
BA_REL_ "GenSigFirstTimeoutTime" BU_SG_REL_ SR_RR SG_ 1265 FrontAxle1Load 6000;
BA_REL_ "GenSigTimeoutTime" BU_SG_REL_ SR_RR SG_ 1265 FrontAxle1Load 1500;
BA_REL_ "GenSigFirstTimeoutTime" BU_SG_REL_ SR_LF SG_ 1265 YearUTC 6000;
BA_REL_ "GenSigTimeoutTime" BU_SG_REL_ SR_LF SG_ 1265 YearUTC 1500;
BA_REL_ "GenSigFirstTimeoutTime" BU_SG_REL_ SR_RF SG_ 1265 YearUTC 6000;
BA_REL_ "GenSigTimeoutTime" BU_SG_REL_ SR_RF SG_ 1265 YearUTC 1500;
BA_REL_ "GenSigFirstTimeoutTime" BU_SG_REL_ SR_RR SG_ 1265 YearUTC 6000;
BA_REL_ "GenSigTimeoutTime" BU_SG_REL_ SR_RR SG_ 1265 YearUTC 1500;
BA_REL_ "GenSigFirstTimeoutTime" BU_SG_REL_ SR_LR SG_ 1265 YearUTC 6000;
BA_REL_ "GenSigTimeoutTime" BU_SG_REL_ SR_LR SG_ 1265 YearUTC 1500;
BA_REL_ "GenSigFirstTimeoutTime" BU_SG_REL_ SR_LF SG_ 1265 TertiaryDriveAxleLoad 6000;
BA_REL_ "GenSigTimeoutTime" BU_SG_REL_ SR_LF SG_ 1265 TertiaryDriveAxleLoad 1500;
BA_REL_ "GenSigFirstTimeoutTime" BU_SG_REL_ SR_RR SG_ 1265 TertiaryDriveAxleLoad 6000;
BA_REL_ "GenSigTimeoutTime" BU_SG_REL_ SR_RR SG_ 1265 TertiaryDriveAxleLoad 1500;
BA_REL_ "GenSigFirstTimeoutTime" BU_SG_REL_ SR_RF SG_ 1265 TertiaryDriveAxleLoad 6000;
BA_REL_ "GenSigTimeoutTime" BU_SG_REL_ SR_RF SG_ 1265 TertiaryDriveAxleLoad 1500;
BA_REL_ "GenSigFirstTimeoutTime" BU_SG_REL_ SR_LR SG_ 1265 TertiaryDriveAxleLoad 6000;
BA_REL_ "GenSigTimeoutTime" BU_SG_REL_ SR_LR SG_ 1265 TertiaryDriveAxleLoad 1500;
BA_REL_ "GenSigFirstTimeoutTime" BU_SG_REL_ SR_RR SG_ 1265 SecondsUTC 6000;
BA_REL_ "GenSigTimeoutTime" BU_SG_REL_ SR_RR SG_ 1265 SecondsUTC 1500;
BA_REL_ "GenSigFirstTimeoutTime" BU_SG_REL_ SR_LF SG_ 1265 SecondsUTC 6000;
BA_REL_ "GenSigTimeoutTime" BU_SG_REL_ SR_LF SG_ 1265 SecondsUTC 1500;
BA_REL_ "GenSigFirstTimeoutTime" BU_SG_REL_ SR_LR SG_ 1265 SecondsUTC 6000;
BA_REL_ "GenSigTimeoutTime" BU_SG_REL_ SR_LR SG_ 1265 SecondsUTC 1500;
BA_REL_ "GenSigFirstTimeoutTime" BU_SG_REL_ SR_RF SG_ 1265 SecondsUTC 6000;
BA_REL_ "GenSigTimeoutTime" BU_SG_REL_ SR_RF SG_ 1265 SecondsUTC 1500;
BA_REL_ "GenSigFirstTimeoutTime" BU_SG_REL_ SR_RF SG_ 1265 Trailer1GeometricData_Index 6000;
BA_REL_ "GenSigTimeoutTime" BU_SG_REL_ SR_RF SG_ 1265 Trailer1GeometricData_Index 1500;
BA_REL_ "GenSigFirstTimeoutTime" BU_SG_REL_ SR_LR SG_ 1265 Trailer1GeometricData_Index 6000;
BA_REL_ "GenSigTimeoutTime" BU_SG_REL_ SR_LR SG_ 1265 Trailer1GeometricData_Index 1500;
BA_REL_ "GenSigFirstTimeoutTime" BU_SG_REL_ SR_LF SG_ 1265 Trailer1GeometricData_Index 6000;
BA_REL_ "GenSigTimeoutTime" BU_SG_REL_ SR_LF SG_ 1265 Trailer1GeometricData_Index 1500;
BA_REL_ "GenSigFirstTimeoutTime" BU_SG_REL_ SR_RR SG_ 1265 Trailer1GeometricData_Index 6000;
BA_REL_ "GenSigTimeoutTime" BU_SG_REL_ SR_RR SG_ 1265 Trailer1GeometricData_Index 1500;
BA_REL_ "GenSigFirstTimeoutTime" BU_SG_REL_ SR_RF SG_ 1265 HoursUTC 6000;
BA_REL_ "GenSigTimeoutTime" BU_SG_REL_ SR_RF SG_ 1265 HoursUTC 1500;
BA_REL_ "GenSigFirstTimeoutTime" BU_SG_REL_ SR_LF SG_ 1265 HoursUTC 6000;
BA_REL_ "GenSigTimeoutTime" BU_SG_REL_ SR_LF SG_ 1265 HoursUTC 1500;
BA_REL_ "GenSigFirstTimeoutTime" BU_SG_REL_ SR_LR SG_ 1265 HoursUTC 6000;
BA_REL_ "GenSigTimeoutTime" BU_SG_REL_ SR_LR SG_ 1265 HoursUTC 1500;
BA_REL_ "GenSigFirstTimeoutTime" BU_SG_REL_ SR_RR SG_ 1265 HoursUTC 6000;
BA_REL_ "GenSigTimeoutTime" BU_SG_REL_ SR_RR SG_ 1265 HoursUTC 1500;
BA_REL_ "GenSigFirstTimeoutTime" BU_SG_REL_ SR_RR SG_ 1265 FrontAxle2Load 6000;
BA_REL_ "GenSigTimeoutTime" BU_SG_REL_ SR_RR SG_ 1265 FrontAxle2Load 1500;
BA_REL_ "GenSigFirstTimeoutTime" BU_SG_REL_ SR_RF SG_ 1265 FrontAxle2Load 6000;
BA_REL_ "GenSigTimeoutTime" BU_SG_REL_ SR_RF SG_ 1265 FrontAxle2Load 1500;
BA_REL_ "GenSigFirstTimeoutTime" BU_SG_REL_ SR_LF SG_ 1265 FrontAxle2Load 6000;
BA_REL_ "GenSigTimeoutTime" BU_SG_REL_ SR_LF SG_ 1265 FrontAxle2Load 1500;
BA_REL_ "GenSigFirstTimeoutTime" BU_SG_REL_ SR_LR SG_ 1265 FrontAxle2Load 6000;
BA_REL_ "GenSigTimeoutTime" BU_SG_REL_ SR_LR SG_ 1265 FrontAxle2Load 1500;
BA_REL_ "GenSigFirstTimeoutTime" BU_SG_REL_ SR_RR SG_ 1265 MonthUTC 6000;
BA_REL_ "GenSigTimeoutTime" BU_SG_REL_ SR_RR SG_ 1265 MonthUTC 1500;
BA_REL_ "GenSigFirstTimeoutTime" BU_SG_REL_ SR_LF SG_ 1265 MonthUTC 6000;
BA_REL_ "GenSigTimeoutTime" BU_SG_REL_ SR_LF SG_ 1265 MonthUTC 1500;
BA_REL_ "GenSigFirstTimeoutTime" BU_SG_REL_ SR_RF SG_ 1265 MonthUTC 6000;
BA_REL_ "GenSigTimeoutTime" BU_SG_REL_ SR_RF SG_ 1265 MonthUTC 1500;
BA_REL_ "GenSigFirstTimeoutTime" BU_SG_REL_ SR_LR SG_ 1265 MonthUTC 6000;
BA_REL_ "GenSigTimeoutTime" BU_SG_REL_ SR_LR SG_ 1265 MonthUTC 1500;
BA_REL_ "GenSigFirstTimeoutTime" BU_SG_REL_ SR_LR SG_ 1265 Trailer5GeometricData_Index 6000;
BA_REL_ "GenSigTimeoutTime" BU_SG_REL_ SR_LR SG_ 1265 Trailer5GeometricData_Index 1500;
BA_REL_ "GenSigFirstTimeoutTime" BU_SG_REL_ SR_LF SG_ 1265 Trailer5GeometricData_Index 6000;
BA_REL_ "GenSigTimeoutTime" BU_SG_REL_ SR_LF SG_ 1265 Trailer5GeometricData_Index 1500;
BA_REL_ "GenSigFirstTimeoutTime" BU_SG_REL_ SR_RR SG_ 1265 Trailer5GeometricData_Index 6000;
BA_REL_ "GenSigTimeoutTime" BU_SG_REL_ SR_RR SG_ 1265 Trailer5GeometricData_Index 1500;
BA_REL_ "GenSigFirstTimeoutTime" BU_SG_REL_ SR_RF SG_ 1265 Trailer5GeometricData_Index 6000;
BA_REL_ "GenSigTimeoutTime" BU_SG_REL_ SR_RF SG_ 1265 Trailer5GeometricData_Index 1500;
BA_REL_ "GenSigFirstTimeoutTime" BU_SG_REL_ SR_RF SG_ 1265 Trailer3GeometricData_Content 6000;
BA_REL_ "GenSigTimeoutTime" BU_SG_REL_ SR_RF SG_ 1265 Trailer3GeometricData_Content 1500;
BA_REL_ "GenSigFirstTimeoutTime" BU_SG_REL_ SR_LF SG_ 1265 Trailer3GeometricData_Content 6000;
BA_REL_ "GenSigTimeoutTime" BU_SG_REL_ SR_LF SG_ 1265 Trailer3GeometricData_Content 1500;
BA_REL_ "GenSigFirstTimeoutTime" BU_SG_REL_ SR_RR SG_ 1265 Trailer3GeometricData_Content 6000;
BA_REL_ "GenSigTimeoutTime" BU_SG_REL_ SR_RR SG_ 1265 Trailer3GeometricData_Content 1500;
BA_REL_ "GenSigFirstTimeoutTime" BU_SG_REL_ SR_LR SG_ 1265 Trailer3GeometricData_Content 6000;
BA_REL_ "GenSigTimeoutTime" BU_SG_REL_ SR_LR SG_ 1265 Trailer3GeometricData_Content 1500;
BA_REL_ "GenSigFirstTimeoutTime" BU_SG_REL_ SR_LF SG_ 1265 Trailer5GeometricData_Content 6000;
BA_REL_ "GenSigTimeoutTime" BU_SG_REL_ SR_LF SG_ 1265 Trailer5GeometricData_Content 1500;
BA_REL_ "GenSigFirstTimeoutTime" BU_SG_REL_ SR_RF SG_ 1265 Trailer5GeometricData_Content 6000;
BA_REL_ "GenSigTimeoutTime" BU_SG_REL_ SR_RF SG_ 1265 Trailer5GeometricData_Content 1500;
BA_REL_ "GenSigFirstTimeoutTime" BU_SG_REL_ SR_LR SG_ 1265 Trailer5GeometricData_Content 6000;
BA_REL_ "GenSigTimeoutTime" BU_SG_REL_ SR_LR SG_ 1265 Trailer5GeometricData_Content 1500;
BA_REL_ "GenSigFirstTimeoutTime" BU_SG_REL_ SR_RR SG_ 1265 Trailer5GeometricData_Content 6000;
BA_REL_ "GenSigTimeoutTime" BU_SG_REL_ SR_RR SG_ 1265 Trailer5GeometricData_Content 1500;
BA_REL_ "GenSigFirstTimeoutTime" BU_SG_REL_ SR_LR SG_ 1265 TagAxleLoad 6000;
BA_REL_ "GenSigTimeoutTime" BU_SG_REL_ SR_LR SG_ 1265 TagAxleLoad 1500;
BA_REL_ "GenSigFirstTimeoutTime" BU_SG_REL_ SR_LF SG_ 1265 TagAxleLoad 6000;
BA_REL_ "GenSigTimeoutTime" BU_SG_REL_ SR_LF SG_ 1265 TagAxleLoad 1500;
BA_REL_ "GenSigFirstTimeoutTime" BU_SG_REL_ SR_RR SG_ 1265 TagAxleLoad 6000;
BA_REL_ "GenSigTimeoutTime" BU_SG_REL_ SR_RR SG_ 1265 TagAxleLoad 1500;
BA_REL_ "GenSigFirstTimeoutTime" BU_SG_REL_ SR_RF SG_ 1265 TagAxleLoad 6000;
BA_REL_ "GenSigTimeoutTime" BU_SG_REL_ SR_RF SG_ 1265 TagAxleLoad 1500;
BA_REL_ "GenSigFirstTimeoutTime" BU_SG_REL_ SR_RR SG_ 1265 AmbientAirTemperature 6000;
BA_REL_ "GenSigTimeoutTime" BU_SG_REL_ SR_RR SG_ 1265 AmbientAirTemperature 1500;
BA_REL_ "GenSigFirstTimeoutTime" BU_SG_REL_ SR_LF SG_ 1265 AmbientAirTemperature 6000;
BA_REL_ "GenSigTimeoutTime" BU_SG_REL_ SR_LF SG_ 1265 AmbientAirTemperature 1500;
BA_REL_ "GenSigFirstTimeoutTime" BU_SG_REL_ SR_LR SG_ 1265 AmbientAirTemperature 6000;
BA_REL_ "GenSigTimeoutTime" BU_SG_REL_ SR_LR SG_ 1265 AmbientAirTemperature 1500;
BA_REL_ "GenSigFirstTimeoutTime" BU_SG_REL_ SR_RF SG_ 1265 AmbientAirTemperature 6000;
BA_REL_ "GenSigTimeoutTime" BU_SG_REL_ SR_RF SG_ 1265 AmbientAirTemperature 1500;
BA_REL_ "GenSigFirstTimeoutTime" BU_SG_REL_ SR_RF SG_ 1265 Trailer4GeometricData_Index 6000;
BA_REL_ "GenSigTimeoutTime" BU_SG_REL_ SR_RF SG_ 1265 Trailer4GeometricData_Index 1500;
BA_REL_ "GenSigFirstTimeoutTime" BU_SG_REL_ SR_LR SG_ 1265 Trailer4GeometricData_Index 6000;
BA_REL_ "GenSigTimeoutTime" BU_SG_REL_ SR_LR SG_ 1265 Trailer4GeometricData_Index 1500;
BA_REL_ "GenSigFirstTimeoutTime" BU_SG_REL_ SR_RR SG_ 1265 Trailer4GeometricData_Index 6000;
BA_REL_ "GenSigTimeoutTime" BU_SG_REL_ SR_RR SG_ 1265 Trailer4GeometricData_Index 1500;
BA_REL_ "GenSigFirstTimeoutTime" BU_SG_REL_ SR_LF SG_ 1265 Trailer4GeometricData_Index 6000;
BA_REL_ "GenSigTimeoutTime" BU_SG_REL_ SR_LF SG_ 1265 Trailer4GeometricData_Index 1500;
BA_REL_ "GenSigFirstTimeoutTime" BU_SG_REL_ SR_LF SG_ 1265 Trailer2GeometricData_Index 6000;
BA_REL_ "GenSigTimeoutTime" BU_SG_REL_ SR_LF SG_ 1265 Trailer2GeometricData_Index 1500;
BA_REL_ "GenSigFirstTimeoutTime" BU_SG_REL_ SR_RF SG_ 1265 Trailer2GeometricData_Index 6000;
BA_REL_ "GenSigTimeoutTime" BU_SG_REL_ SR_RF SG_ 1265 Trailer2GeometricData_Index 1500;
BA_REL_ "GenSigFirstTimeoutTime" BU_SG_REL_ SR_LR SG_ 1265 Trailer2GeometricData_Index 6000;
BA_REL_ "GenSigTimeoutTime" BU_SG_REL_ SR_LR SG_ 1265 Trailer2GeometricData_Index 1500;
BA_REL_ "GenSigFirstTimeoutTime" BU_SG_REL_ SR_RR SG_ 1265 Trailer2GeometricData_Index 6000;
BA_REL_ "GenSigTimeoutTime" BU_SG_REL_ SR_RR SG_ 1265 Trailer2GeometricData_Index 1500;
BA_REL_ "GenSigFirstTimeoutTime" BU_SG_REL_ SR_RR SG_ 1265 SecondaryDriveAxleLoad 6000;
BA_REL_ "GenSigTimeoutTime" BU_SG_REL_ SR_RR SG_ 1265 SecondaryDriveAxleLoad 1500;
BA_REL_ "GenSigFirstTimeoutTime" BU_SG_REL_ SR_LR SG_ 1265 SecondaryDriveAxleLoad 6000;
BA_REL_ "GenSigTimeoutTime" BU_SG_REL_ SR_LR SG_ 1265 SecondaryDriveAxleLoad 1500;
BA_REL_ "GenSigFirstTimeoutTime" BU_SG_REL_ SR_RF SG_ 1265 SecondaryDriveAxleLoad 6000;
BA_REL_ "GenSigTimeoutTime" BU_SG_REL_ SR_RF SG_ 1265 SecondaryDriveAxleLoad 1500;
BA_REL_ "GenSigFirstTimeoutTime" BU_SG_REL_ SR_LF SG_ 1265 SecondaryDriveAxleLoad 6000;
BA_REL_ "GenSigTimeoutTime" BU_SG_REL_ SR_LF SG_ 1265 SecondaryDriveAxleLoad 1500;
BA_REL_ "GenSigFirstTimeoutTime" BU_SG_REL_ SR_RF SG_ 1265 BendingAngle 6000;
BA_REL_ "GenSigTimeoutTime" BU_SG_REL_ SR_RF SG_ 1265 BendingAngle 1500;
BA_REL_ "GenSigFirstTimeoutTime" BU_SG_REL_ SR_LF SG_ 1265 BendingAngle 6000;
BA_REL_ "GenSigTimeoutTime" BU_SG_REL_ SR_LF SG_ 1265 BendingAngle 1500;
BA_REL_ "GenSigFirstTimeoutTime" BU_SG_REL_ SR_RR SG_ 1265 BendingAngle 6000;
BA_REL_ "GenSigTimeoutTime" BU_SG_REL_ SR_RR SG_ 1265 BendingAngle 1500;
BA_REL_ "GenSigFirstTimeoutTime" BU_SG_REL_ SR_LR SG_ 1265 BendingAngle 6000;
BA_REL_ "GenSigTimeoutTime" BU_SG_REL_ SR_LR SG_ 1265 BendingAngle 1500;
BA_REL_ "GenSigFirstTimeoutTime" BU_SG_REL_ SR_LF SG_ 1265 Trailer3GeometricData_Index 6000;
BA_REL_ "GenSigTimeoutTime" BU_SG_REL_ SR_LF SG_ 1265 Trailer3GeometricData_Index 1500;
BA_REL_ "GenSigFirstTimeoutTime" BU_SG_REL_ SR_RF SG_ 1265 Trailer3GeometricData_Index 6000;
BA_REL_ "GenSigTimeoutTime" BU_SG_REL_ SR_RF SG_ 1265 Trailer3GeometricData_Index 1500;
BA_REL_ "GenSigFirstTimeoutTime" BU_SG_REL_ SR_RR SG_ 1265 Trailer3GeometricData_Index 6000;
BA_REL_ "GenSigTimeoutTime" BU_SG_REL_ SR_RR SG_ 1265 Trailer3GeometricData_Index 1500;
BA_REL_ "GenSigFirstTimeoutTime" BU_SG_REL_ SR_LR SG_ 1265 Trailer3GeometricData_Index 6000;
BA_REL_ "GenSigTimeoutTime" BU_SG_REL_ SR_LR SG_ 1265 Trailer3GeometricData_Index 1500;
BA_REL_ "GenSigFirstTimeoutTime" BU_SG_REL_ SR_RR SG_ 929 Trailer2LiftAxle1Pos 3000;
BA_REL_ "GenSigTimeoutTime" BU_SG_REL_ SR_RR SG_ 929 Trailer2LiftAxle1Pos 600;
BA_REL_ "GenSigFirstTimeoutTime" BU_SG_REL_ SR_LF SG_ 929 Trailer2LiftAxle1Pos 3000;
BA_REL_ "GenSigTimeoutTime" BU_SG_REL_ SR_LF SG_ 929 Trailer2LiftAxle1Pos 600;
BA_REL_ "GenSigFirstTimeoutTime" BU_SG_REL_ SR_RF SG_ 929 Trailer2LiftAxle1Pos 3000;
BA_REL_ "GenSigTimeoutTime" BU_SG_REL_ SR_RF SG_ 929 Trailer2LiftAxle1Pos 600;
BA_REL_ "GenSigFirstTimeoutTime" BU_SG_REL_ SR_LR SG_ 929 Trailer2LiftAxle1Pos 3000;
BA_REL_ "GenSigTimeoutTime" BU_SG_REL_ SR_LR SG_ 929 Trailer2LiftAxle1Pos 600;
BA_REL_ "GenSigFirstTimeoutTime" BU_SG_REL_ SR_LF SG_ 929 TimeSynchStat_DACU 3000;
BA_REL_ "GenSigTimeoutTime" BU_SG_REL_ SR_LF SG_ 929 TimeSynchStat_DACU 600;
BA_REL_ "GenSigFirstTimeoutTime" BU_SG_REL_ SR_RR SG_ 929 TimeSynchStat_DACU 3000;
BA_REL_ "GenSigTimeoutTime" BU_SG_REL_ SR_RR SG_ 929 TimeSynchStat_DACU 600;
BA_REL_ "GenSigFirstTimeoutTime" BU_SG_REL_ SR_LR SG_ 929 TimeSynchStat_DACU 3000;
BA_REL_ "GenSigTimeoutTime" BU_SG_REL_ SR_LR SG_ 929 TimeSynchStat_DACU 600;
BA_REL_ "GenSigFirstTimeoutTime" BU_SG_REL_ SR_RF SG_ 929 TimeSynchStat_DACU 3000;
BA_REL_ "GenSigTimeoutTime" BU_SG_REL_ SR_RF SG_ 929 TimeSynchStat_DACU 600;
BA_REL_ "GenSigFirstTimeoutTime" BU_SG_REL_ SR_LR SG_ 929 Trailer1LiftAxle1Pos 3000;
BA_REL_ "GenSigTimeoutTime" BU_SG_REL_ SR_LR SG_ 929 Trailer1LiftAxle1Pos 600;
BA_REL_ "GenSigFirstTimeoutTime" BU_SG_REL_ SR_RR SG_ 929 Trailer1LiftAxle1Pos 3000;
BA_REL_ "GenSigTimeoutTime" BU_SG_REL_ SR_RR SG_ 929 Trailer1LiftAxle1Pos 600;
BA_REL_ "GenSigFirstTimeoutTime" BU_SG_REL_ SR_RF SG_ 929 Trailer1LiftAxle1Pos 3000;
BA_REL_ "GenSigTimeoutTime" BU_SG_REL_ SR_RF SG_ 929 Trailer1LiftAxle1Pos 600;
BA_REL_ "GenSigFirstTimeoutTime" BU_SG_REL_ SR_LF SG_ 929 Trailer1LiftAxle1Pos 3000;
BA_REL_ "GenSigTimeoutTime" BU_SG_REL_ SR_LF SG_ 929 Trailer1LiftAxle1Pos 600;
BA_REL_ "GenSigFirstTimeoutTime" BU_SG_REL_ SR_LR SG_ 929 Trailer5LiftAxle1Pos 3000;
BA_REL_ "GenSigTimeoutTime" BU_SG_REL_ SR_LR SG_ 929 Trailer5LiftAxle1Pos 600;
BA_REL_ "GenSigFirstTimeoutTime" BU_SG_REL_ SR_LF SG_ 929 Trailer5LiftAxle1Pos 3000;
BA_REL_ "GenSigTimeoutTime" BU_SG_REL_ SR_LF SG_ 929 Trailer5LiftAxle1Pos 600;
BA_REL_ "GenSigFirstTimeoutTime" BU_SG_REL_ SR_RF SG_ 929 Trailer5LiftAxle1Pos 3000;
BA_REL_ "GenSigTimeoutTime" BU_SG_REL_ SR_RF SG_ 929 Trailer5LiftAxle1Pos 600;
BA_REL_ "GenSigFirstTimeoutTime" BU_SG_REL_ SR_RR SG_ 929 Trailer5LiftAxle1Pos 3000;
BA_REL_ "GenSigTimeoutTime" BU_SG_REL_ SR_RR SG_ 929 Trailer5LiftAxle1Pos 600;
BA_REL_ "GenSigFirstTimeoutTime" BU_SG_REL_ SR_RR SG_ 929 Trailer2LiftAxle2Pos 3000;
BA_REL_ "GenSigTimeoutTime" BU_SG_REL_ SR_RR SG_ 929 Trailer2LiftAxle2Pos 600;
BA_REL_ "GenSigFirstTimeoutTime" BU_SG_REL_ SR_RF SG_ 929 Trailer2LiftAxle2Pos 3000;
BA_REL_ "GenSigTimeoutTime" BU_SG_REL_ SR_RF SG_ 929 Trailer2LiftAxle2Pos 600;
BA_REL_ "GenSigFirstTimeoutTime" BU_SG_REL_ SR_LR SG_ 929 Trailer2LiftAxle2Pos 3000;
BA_REL_ "GenSigTimeoutTime" BU_SG_REL_ SR_LR SG_ 929 Trailer2LiftAxle2Pos 600;
BA_REL_ "GenSigFirstTimeoutTime" BU_SG_REL_ SR_LF SG_ 929 Trailer2LiftAxle2Pos 3000;
BA_REL_ "GenSigTimeoutTime" BU_SG_REL_ SR_LF SG_ 929 Trailer2LiftAxle2Pos 600;
BA_REL_ "GenSigFirstTimeoutTime" BU_SG_REL_ SR_RR SG_ 929 TrailersConnected 3000;
BA_REL_ "GenSigTimeoutTime" BU_SG_REL_ SR_RR SG_ 929 TrailersConnected 600;
BA_REL_ "GenSigFirstTimeoutTime" BU_SG_REL_ SR_LR SG_ 929 TrailersConnected 3000;
BA_REL_ "GenSigTimeoutTime" BU_SG_REL_ SR_LR SG_ 929 TrailersConnected 600;
BA_REL_ "GenSigFirstTimeoutTime" BU_SG_REL_ SR_RF SG_ 929 TrailersConnected 3000;
BA_REL_ "GenSigTimeoutTime" BU_SG_REL_ SR_RF SG_ 929 TrailersConnected 600;
BA_REL_ "GenSigFirstTimeoutTime" BU_SG_REL_ SR_LF SG_ 929 TrailersConnected 3000;
BA_REL_ "GenSigTimeoutTime" BU_SG_REL_ SR_LF SG_ 929 TrailersConnected 600;
BA_REL_ "GenSigFirstTimeoutTime" BU_SG_REL_ SR_RF SG_ 929 Trailer4LiftAxle2Pos 3000;
BA_REL_ "GenSigTimeoutTime" BU_SG_REL_ SR_RF SG_ 929 Trailer4LiftAxle2Pos 600;
BA_REL_ "GenSigFirstTimeoutTime" BU_SG_REL_ SR_RR SG_ 929 Trailer4LiftAxle2Pos 3000;
BA_REL_ "GenSigTimeoutTime" BU_SG_REL_ SR_RR SG_ 929 Trailer4LiftAxle2Pos 600;
BA_REL_ "GenSigFirstTimeoutTime" BU_SG_REL_ SR_LR SG_ 929 Trailer4LiftAxle2Pos 3000;
BA_REL_ "GenSigTimeoutTime" BU_SG_REL_ SR_LR SG_ 929 Trailer4LiftAxle2Pos 600;
BA_REL_ "GenSigFirstTimeoutTime" BU_SG_REL_ SR_LF SG_ 929 Trailer4LiftAxle2Pos 3000;
BA_REL_ "GenSigTimeoutTime" BU_SG_REL_ SR_LF SG_ 929 Trailer4LiftAxle2Pos 600;
BA_REL_ "GenSigFirstTimeoutTime" BU_SG_REL_ SR_LR SG_ 929 Trailer1LiftAxle2Pos 3000;
BA_REL_ "GenSigTimeoutTime" BU_SG_REL_ SR_LR SG_ 929 Trailer1LiftAxle2Pos 600;
BA_REL_ "GenSigFirstTimeoutTime" BU_SG_REL_ SR_LF SG_ 929 Trailer1LiftAxle2Pos 3000;
BA_REL_ "GenSigTimeoutTime" BU_SG_REL_ SR_LF SG_ 929 Trailer1LiftAxle2Pos 600;
BA_REL_ "GenSigFirstTimeoutTime" BU_SG_REL_ SR_RF SG_ 929 Trailer1LiftAxle2Pos 3000;
BA_REL_ "GenSigTimeoutTime" BU_SG_REL_ SR_RF SG_ 929 Trailer1LiftAxle2Pos 600;
BA_REL_ "GenSigFirstTimeoutTime" BU_SG_REL_ SR_RR SG_ 929 Trailer1LiftAxle2Pos 3000;
BA_REL_ "GenSigTimeoutTime" BU_SG_REL_ SR_RR SG_ 929 Trailer1LiftAxle2Pos 600;
BA_REL_ "GenSigFirstTimeoutTime" BU_SG_REL_ SR_LR SG_ 929 TrailerWithoutABS 3000;
BA_REL_ "GenSigTimeoutTime" BU_SG_REL_ SR_LR SG_ 929 TrailerWithoutABS 600;
BA_REL_ "GenSigFirstTimeoutTime" BU_SG_REL_ SR_LF SG_ 929 TrailerWithoutABS 3000;
BA_REL_ "GenSigTimeoutTime" BU_SG_REL_ SR_LF SG_ 929 TrailerWithoutABS 600;
BA_REL_ "GenSigFirstTimeoutTime" BU_SG_REL_ SR_RF SG_ 929 TrailerWithoutABS 3000;
BA_REL_ "GenSigTimeoutTime" BU_SG_REL_ SR_RF SG_ 929 TrailerWithoutABS 600;
BA_REL_ "GenSigFirstTimeoutTime" BU_SG_REL_ SR_RR SG_ 929 TrailerWithoutABS 3000;
BA_REL_ "GenSigTimeoutTime" BU_SG_REL_ SR_RR SG_ 929 TrailerWithoutABS 600;
BA_REL_ "GenSigFirstTimeoutTime" BU_SG_REL_ SR_RR SG_ 929 Trailer5LiftAxle2Pos 3000;
BA_REL_ "GenSigTimeoutTime" BU_SG_REL_ SR_RR SG_ 929 Trailer5LiftAxle2Pos 600;
BA_REL_ "GenSigFirstTimeoutTime" BU_SG_REL_ SR_LR SG_ 929 Trailer5LiftAxle2Pos 3000;
BA_REL_ "GenSigTimeoutTime" BU_SG_REL_ SR_LR SG_ 929 Trailer5LiftAxle2Pos 600;
BA_REL_ "GenSigFirstTimeoutTime" BU_SG_REL_ SR_LF SG_ 929 Trailer5LiftAxle2Pos 3000;
BA_REL_ "GenSigTimeoutTime" BU_SG_REL_ SR_LF SG_ 929 Trailer5LiftAxle2Pos 600;
BA_REL_ "GenSigFirstTimeoutTime" BU_SG_REL_ SR_RF SG_ 929 Trailer5LiftAxle2Pos 3000;
BA_REL_ "GenSigTimeoutTime" BU_SG_REL_ SR_RF SG_ 929 Trailer5LiftAxle2Pos 600;
BA_REL_ "GenSigFirstTimeoutTime" BU_SG_REL_ SR_LR SG_ 929 Trailer4LiftAxle1Pos 3000;
BA_REL_ "GenSigTimeoutTime" BU_SG_REL_ SR_LR SG_ 929 Trailer4LiftAxle1Pos 600;
BA_REL_ "GenSigFirstTimeoutTime" BU_SG_REL_ SR_RF SG_ 929 Trailer4LiftAxle1Pos 3000;
BA_REL_ "GenSigTimeoutTime" BU_SG_REL_ SR_RF SG_ 929 Trailer4LiftAxle1Pos 600;
BA_REL_ "GenSigFirstTimeoutTime" BU_SG_REL_ SR_LF SG_ 929 Trailer4LiftAxle1Pos 3000;
BA_REL_ "GenSigTimeoutTime" BU_SG_REL_ SR_LF SG_ 929 Trailer4LiftAxle1Pos 600;
BA_REL_ "GenSigFirstTimeoutTime" BU_SG_REL_ SR_RR SG_ 929 Trailer4LiftAxle1Pos 3000;
BA_REL_ "GenSigTimeoutTime" BU_SG_REL_ SR_RR SG_ 929 Trailer4LiftAxle1Pos 600;
BA_REL_ "GenSigFirstTimeoutTime" BU_SG_REL_ SR_RF SG_ 929 Trailer3LiftAxle2Pos 3000;
BA_REL_ "GenSigTimeoutTime" BU_SG_REL_ SR_RF SG_ 929 Trailer3LiftAxle2Pos 600;
BA_REL_ "GenSigFirstTimeoutTime" BU_SG_REL_ SR_LF SG_ 929 Trailer3LiftAxle2Pos 3000;
BA_REL_ "GenSigTimeoutTime" BU_SG_REL_ SR_LF SG_ 929 Trailer3LiftAxle2Pos 600;
BA_REL_ "GenSigFirstTimeoutTime" BU_SG_REL_ SR_LR SG_ 929 Trailer3LiftAxle2Pos 3000;
BA_REL_ "GenSigTimeoutTime" BU_SG_REL_ SR_LR SG_ 929 Trailer3LiftAxle2Pos 600;
BA_REL_ "GenSigFirstTimeoutTime" BU_SG_REL_ SR_RR SG_ 929 Trailer3LiftAxle2Pos 3000;
BA_REL_ "GenSigTimeoutTime" BU_SG_REL_ SR_RR SG_ 929 Trailer3LiftAxle2Pos 600;
BA_REL_ "GenSigFirstTimeoutTime" BU_SG_REL_ SR_RR SG_ 929 Trailer3LiftAxle1Pos 3000;
BA_REL_ "GenSigTimeoutTime" BU_SG_REL_ SR_RR SG_ 929 Trailer3LiftAxle1Pos 600;
BA_REL_ "GenSigFirstTimeoutTime" BU_SG_REL_ SR_LR SG_ 929 Trailer3LiftAxle1Pos 3000;
BA_REL_ "GenSigTimeoutTime" BU_SG_REL_ SR_LR SG_ 929 Trailer3LiftAxle1Pos 600;
BA_REL_ "GenSigFirstTimeoutTime" BU_SG_REL_ SR_LF SG_ 929 Trailer3LiftAxle1Pos 3000;
BA_REL_ "GenSigTimeoutTime" BU_SG_REL_ SR_LF SG_ 929 Trailer3LiftAxle1Pos 600;
BA_REL_ "GenSigFirstTimeoutTime" BU_SG_REL_ SR_RF SG_ 929 Trailer3LiftAxle1Pos 3000;
BA_REL_ "GenSigTimeoutTime" BU_SG_REL_ SR_RF SG_ 929 Trailer3LiftAxle1Pos 600;
BA_REL_ "GenSigFirstTimeoutTime" BU_SG_REL_ SR_RR SG_ 929 SRadarLoggingTrigger 3000;
BA_REL_ "GenSigTimeoutTime" BU_SG_REL_ SR_RR SG_ 929 SRadarLoggingTrigger 600;
BA_REL_ "GenSigFirstTimeoutTime" BU_SG_REL_ SR_RF SG_ 929 SRadarLoggingTrigger 3000;
BA_REL_ "GenSigTimeoutTime" BU_SG_REL_ SR_RF SG_ 929 SRadarLoggingTrigger 600;
BA_REL_ "GenSigFirstTimeoutTime" BU_SG_REL_ SR_LR SG_ 929 SRadarLoggingTrigger 3000;
BA_REL_ "GenSigTimeoutTime" BU_SG_REL_ SR_LR SG_ 929 SRadarLoggingTrigger 600;
BA_REL_ "GenSigFirstTimeoutTime" BU_SG_REL_ SR_LF SG_ 929 SRadarLoggingTrigger 3000;
BA_REL_ "GenSigTimeoutTime" BU_SG_REL_ SR_LF SG_ 929 SRadarLoggingTrigger 600;
BA_REL_ "GenSigFirstTimeoutTime" BU_SG_REL_ SR_RF SG_ 547 LiftAxle1PositionStatus 3000;
BA_REL_ "GenSigTimeoutTime" BU_SG_REL_ SR_RF SG_ 547 LiftAxle1PositionStatus 120;
BA_REL_ "GenSigFirstTimeoutTime" BU_SG_REL_ SR_RR SG_ 547 LiftAxle1PositionStatus 3000;
BA_REL_ "GenSigTimeoutTime" BU_SG_REL_ SR_RR SG_ 547 LiftAxle1PositionStatus 120;
BA_REL_ "GenSigFirstTimeoutTime" BU_SG_REL_ SR_LR SG_ 547 LiftAxle1PositionStatus 3000;
BA_REL_ "GenSigTimeoutTime" BU_SG_REL_ SR_LR SG_ 547 LiftAxle1PositionStatus 120;
BA_REL_ "GenSigFirstTimeoutTime" BU_SG_REL_ SR_LF SG_ 547 LiftAxle1PositionStatus 3000;
BA_REL_ "GenSigTimeoutTime" BU_SG_REL_ SR_LF SG_ 547 LiftAxle1PositionStatus 120;
BA_REL_ "GenSigFirstTimeoutTime" BU_SG_REL_ SR_RF SG_ 547 VehicleMode 3000;
BA_REL_ "GenSigTimeoutTime" BU_SG_REL_ SR_RF SG_ 547 VehicleMode 500;
BA_REL_ "GenSigFirstTimeoutTime" BU_SG_REL_ SR_LR SG_ 547 VehicleMode 3000;
BA_REL_ "GenSigTimeoutTime" BU_SG_REL_ SR_LR SG_ 547 VehicleMode 500;
BA_REL_ "GenSigFirstTimeoutTime" BU_SG_REL_ SR_LF SG_ 547 VehicleMode 3000;
BA_REL_ "GenSigTimeoutTime" BU_SG_REL_ SR_LF SG_ 547 VehicleMode 500;
BA_REL_ "GenSigFirstTimeoutTime" BU_SG_REL_ SR_RR SG_ 547 VehicleMode 3000;
BA_REL_ "GenSigTimeoutTime" BU_SG_REL_ SR_RR SG_ 547 VehicleMode 500;
BA_REL_ "GenSigFirstTimeoutTime" BU_SG_REL_ SR_LF SG_ 547 TrailerConnected 3000;
BA_REL_ "GenSigTimeoutTime" BU_SG_REL_ SR_LF SG_ 547 TrailerConnected 120;
BA_REL_ "GenSigFirstTimeoutTime" BU_SG_REL_ SR_RF SG_ 547 TrailerConnected 3000;
BA_REL_ "GenSigTimeoutTime" BU_SG_REL_ SR_RF SG_ 547 TrailerConnected 120;
BA_REL_ "GenSigFirstTimeoutTime" BU_SG_REL_ SR_LR SG_ 547 TrailerConnected 3000;
BA_REL_ "GenSigTimeoutTime" BU_SG_REL_ SR_LR SG_ 547 TrailerConnected 120;
BA_REL_ "GenSigFirstTimeoutTime" BU_SG_REL_ SR_RR SG_ 547 TrailerConnected 3000;
BA_REL_ "GenSigTimeoutTime" BU_SG_REL_ SR_RR SG_ 547 TrailerConnected 120;
BA_REL_ "GenSigFirstTimeoutTime" BU_SG_REL_ SR_LR SG_ 547 SideSensorPowerMode 3000;
BA_REL_ "GenSigTimeoutTime" BU_SG_REL_ SR_LR SG_ 547 SideSensorPowerMode 120;
BA_REL_ "GenSigFirstTimeoutTime" BU_SG_REL_ SR_RF SG_ 547 SideSensorPowerMode 3000;
BA_REL_ "GenSigTimeoutTime" BU_SG_REL_ SR_RF SG_ 547 SideSensorPowerMode 120;
BA_REL_ "GenSigFirstTimeoutTime" BU_SG_REL_ SR_LF SG_ 547 SideSensorPowerMode 3000;
BA_REL_ "GenSigTimeoutTime" BU_SG_REL_ SR_LF SG_ 547 SideSensorPowerMode 120;
BA_REL_ "GenSigFirstTimeoutTime" BU_SG_REL_ SR_RR SG_ 547 SideSensorPowerMode 3000;
BA_REL_ "GenSigTimeoutTime" BU_SG_REL_ SR_RR SG_ 547 SideSensorPowerMode 120;
BA_REL_ "GenSigFirstTimeoutTime" BU_SG_REL_ SR_RF SG_ 547 FrontCameraDynRoll 3000;
BA_REL_ "GenSigTimeoutTime" BU_SG_REL_ SR_RF SG_ 547 FrontCameraDynRoll 120;
BA_REL_ "GenSigFirstTimeoutTime" BU_SG_REL_ SR_RR SG_ 547 FrontCameraDynRoll 3000;
BA_REL_ "GenSigTimeoutTime" BU_SG_REL_ SR_RR SG_ 547 FrontCameraDynRoll 120;
BA_REL_ "GenSigFirstTimeoutTime" BU_SG_REL_ SR_LR SG_ 547 FrontCameraDynRoll 3000;
BA_REL_ "GenSigTimeoutTime" BU_SG_REL_ SR_LR SG_ 547 FrontCameraDynRoll 120;
BA_REL_ "GenSigFirstTimeoutTime" BU_SG_REL_ SR_LF SG_ 547 FrontCameraDynRoll 3000;
BA_REL_ "GenSigTimeoutTime" BU_SG_REL_ SR_LF SG_ 547 FrontCameraDynRoll 120;
BA_REL_ "GenSigFirstTimeoutTime" BU_SG_REL_ SR_RF SG_ 547 LiftAxle2PositionStatus 3000;
BA_REL_ "GenSigTimeoutTime" BU_SG_REL_ SR_RF SG_ 547 LiftAxle2PositionStatus 120;
BA_REL_ "GenSigFirstTimeoutTime" BU_SG_REL_ SR_RR SG_ 547 LiftAxle2PositionStatus 3000;
BA_REL_ "GenSigTimeoutTime" BU_SG_REL_ SR_RR SG_ 547 LiftAxle2PositionStatus 120;
BA_REL_ "GenSigFirstTimeoutTime" BU_SG_REL_ SR_LR SG_ 547 LiftAxle2PositionStatus 3000;
BA_REL_ "GenSigTimeoutTime" BU_SG_REL_ SR_LR SG_ 547 LiftAxle2PositionStatus 120;
BA_REL_ "GenSigFirstTimeoutTime" BU_SG_REL_ SR_LF SG_ 547 LiftAxle2PositionStatus 3000;
BA_REL_ "GenSigTimeoutTime" BU_SG_REL_ SR_LF SG_ 547 LiftAxle2PositionStatus 120;
BA_REL_ "GenSigFirstTimeoutTime" BU_SG_REL_ SR_RF SG_ 547 FrontCameraDynPitch 3000;
BA_REL_ "GenSigTimeoutTime" BU_SG_REL_ SR_RF SG_ 547 FrontCameraDynPitch 120;
BA_REL_ "GenSigFirstTimeoutTime" BU_SG_REL_ SR_LF SG_ 547 FrontCameraDynPitch 3000;
BA_REL_ "GenSigTimeoutTime" BU_SG_REL_ SR_LF SG_ 547 FrontCameraDynPitch 120;
BA_REL_ "GenSigFirstTimeoutTime" BU_SG_REL_ SR_RR SG_ 547 FrontCameraDynPitch 3000;
BA_REL_ "GenSigTimeoutTime" BU_SG_REL_ SR_RR SG_ 547 FrontCameraDynPitch 120;
BA_REL_ "GenSigFirstTimeoutTime" BU_SG_REL_ SR_LR SG_ 547 FrontCameraDynPitch 3000;
BA_REL_ "GenSigTimeoutTime" BU_SG_REL_ SR_LR SG_ 547 FrontCameraDynPitch 120;
BA_REL_ "GenSigFirstTimeoutTime" BU_SG_REL_ SR_LR SG_ 547 WiperModeStatus 3000;
BA_REL_ "GenSigTimeoutTime" BU_SG_REL_ SR_LR SG_ 547 WiperModeStatus 500;
BA_REL_ "GenSigFirstTimeoutTime" BU_SG_REL_ SR_RF SG_ 547 WiperModeStatus 3000;
BA_REL_ "GenSigTimeoutTime" BU_SG_REL_ SR_RF SG_ 547 WiperModeStatus 500;
BA_REL_ "GenSigFirstTimeoutTime" BU_SG_REL_ SR_RR SG_ 547 WiperModeStatus 3000;
BA_REL_ "GenSigTimeoutTime" BU_SG_REL_ SR_RR SG_ 547 WiperModeStatus 500;
BA_REL_ "GenSigFirstTimeoutTime" BU_SG_REL_ SR_LF SG_ 547 WiperModeStatus 3000;
BA_REL_ "GenSigTimeoutTime" BU_SG_REL_ SR_LF SG_ 547 WiperModeStatus 500;
BA_REL_ "GenSigFirstTimeoutTime" BU_SG_REL_ SR_RR SG_ 1552 DACUSwVersion_Substring3 60000;
BA_REL_ "GenSigTimeoutTime" BU_SG_REL_ SR_RR SG_ 1552 DACUSwVersion_Substring3 60000;
BA_REL_ "GenSigFirstTimeoutTime" BU_SG_REL_ SR_LF SG_ 1552 DACUSwVersion_Substring3 60000;
BA_REL_ "GenSigTimeoutTime" BU_SG_REL_ SR_LF SG_ 1552 DACUSwVersion_Substring3 60000;
BA_REL_ "GenSigFirstTimeoutTime" BU_SG_REL_ SR_RF SG_ 1552 DACUSwVersion_Substring3 60000;
BA_REL_ "GenSigTimeoutTime" BU_SG_REL_ SR_RF SG_ 1552 DACUSwVersion_Substring3 60000;
BA_REL_ "GenSigFirstTimeoutTime" BU_SG_REL_ SR_LR SG_ 1552 DACUSwVersion_Substring3 60000;
BA_REL_ "GenSigTimeoutTime" BU_SG_REL_ SR_LR SG_ 1552 DACUSwVersion_Substring3 60000;
BA_REL_ "GenSigFirstTimeoutTime" BU_SG_REL_ SR_RR SG_ 1552 DACUSwVersion_Substring1 60000;
BA_REL_ "GenSigTimeoutTime" BU_SG_REL_ SR_RR SG_ 1552 DACUSwVersion_Substring1 60000;
BA_REL_ "GenSigFirstTimeoutTime" BU_SG_REL_ SR_LR SG_ 1552 DACUSwVersion_Substring1 60000;
BA_REL_ "GenSigTimeoutTime" BU_SG_REL_ SR_LR SG_ 1552 DACUSwVersion_Substring1 60000;
BA_REL_ "GenSigFirstTimeoutTime" BU_SG_REL_ SR_LF SG_ 1552 DACUSwVersion_Substring1 60000;
BA_REL_ "GenSigTimeoutTime" BU_SG_REL_ SR_LF SG_ 1552 DACUSwVersion_Substring1 60000;
BA_REL_ "GenSigFirstTimeoutTime" BU_SG_REL_ SR_RF SG_ 1552 DACUSwVersion_Substring1 60000;
BA_REL_ "GenSigTimeoutTime" BU_SG_REL_ SR_RF SG_ 1552 DACUSwVersion_Substring1 60000;
BA_REL_ "GenSigFirstTimeoutTime" BU_SG_REL_ SR_RF SG_ 1552 DACUSwVersion_Substring4 60000;
BA_REL_ "GenSigTimeoutTime" BU_SG_REL_ SR_RF SG_ 1552 DACUSwVersion_Substring4 60000;
BA_REL_ "GenSigFirstTimeoutTime" BU_SG_REL_ SR_LF SG_ 1552 DACUSwVersion_Substring4 60000;
BA_REL_ "GenSigTimeoutTime" BU_SG_REL_ SR_LF SG_ 1552 DACUSwVersion_Substring4 60000;
BA_REL_ "GenSigFirstTimeoutTime" BU_SG_REL_ SR_RR SG_ 1552 DACUSwVersion_Substring4 60000;
BA_REL_ "GenSigTimeoutTime" BU_SG_REL_ SR_RR SG_ 1552 DACUSwVersion_Substring4 60000;
BA_REL_ "GenSigFirstTimeoutTime" BU_SG_REL_ SR_LR SG_ 1552 DACUSwVersion_Substring4 60000;
BA_REL_ "GenSigTimeoutTime" BU_SG_REL_ SR_LR SG_ 1552 DACUSwVersion_Substring4 60000;
BA_REL_ "GenSigFirstTimeoutTime" BU_SG_REL_ SR_LR SG_ 1552 DACUSwVersion_Substring7 60000;
BA_REL_ "GenSigTimeoutTime" BU_SG_REL_ SR_LR SG_ 1552 DACUSwVersion_Substring7 60000;
BA_REL_ "GenSigFirstTimeoutTime" BU_SG_REL_ SR_LF SG_ 1552 DACUSwVersion_Substring7 60000;
BA_REL_ "GenSigTimeoutTime" BU_SG_REL_ SR_LF SG_ 1552 DACUSwVersion_Substring7 60000;
BA_REL_ "GenSigFirstTimeoutTime" BU_SG_REL_ SR_RR SG_ 1552 DACUSwVersion_Substring7 60000;
BA_REL_ "GenSigTimeoutTime" BU_SG_REL_ SR_RR SG_ 1552 DACUSwVersion_Substring7 60000;
BA_REL_ "GenSigFirstTimeoutTime" BU_SG_REL_ SR_RF SG_ 1552 DACUSwVersion_Substring7 60000;
BA_REL_ "GenSigTimeoutTime" BU_SG_REL_ SR_RF SG_ 1552 DACUSwVersion_Substring7 60000;
BA_REL_ "GenSigFirstTimeoutTime" BU_SG_REL_ SR_LF SG_ 1552 DACUSwVersion_Substring0 60000;
BA_REL_ "GenSigTimeoutTime" BU_SG_REL_ SR_LF SG_ 1552 DACUSwVersion_Substring0 60000;
BA_REL_ "GenSigFirstTimeoutTime" BU_SG_REL_ SR_RF SG_ 1552 DACUSwVersion_Substring0 60000;
BA_REL_ "GenSigTimeoutTime" BU_SG_REL_ SR_RF SG_ 1552 DACUSwVersion_Substring0 60000;
BA_REL_ "GenSigFirstTimeoutTime" BU_SG_REL_ SR_LR SG_ 1552 DACUSwVersion_Substring0 60000;
BA_REL_ "GenSigTimeoutTime" BU_SG_REL_ SR_LR SG_ 1552 DACUSwVersion_Substring0 60000;
BA_REL_ "GenSigFirstTimeoutTime" BU_SG_REL_ SR_RR SG_ 1552 DACUSwVersion_Substring0 60000;
BA_REL_ "GenSigTimeoutTime" BU_SG_REL_ SR_RR SG_ 1552 DACUSwVersion_Substring0 60000;
BA_REL_ "GenSigFirstTimeoutTime" BU_SG_REL_ SR_LR SG_ 1552 DACUSwVersion_Substring6 60000;
BA_REL_ "GenSigTimeoutTime" BU_SG_REL_ SR_LR SG_ 1552 DACUSwVersion_Substring6 60000;
BA_REL_ "GenSigFirstTimeoutTime" BU_SG_REL_ SR_RF SG_ 1552 DACUSwVersion_Substring6 60000;
BA_REL_ "GenSigTimeoutTime" BU_SG_REL_ SR_RF SG_ 1552 DACUSwVersion_Substring6 60000;
BA_REL_ "GenSigFirstTimeoutTime" BU_SG_REL_ SR_LF SG_ 1552 DACUSwVersion_Substring6 60000;
BA_REL_ "GenSigTimeoutTime" BU_SG_REL_ SR_LF SG_ 1552 DACUSwVersion_Substring6 60000;
BA_REL_ "GenSigFirstTimeoutTime" BU_SG_REL_ SR_RR SG_ 1552 DACUSwVersion_Substring6 60000;
BA_REL_ "GenSigTimeoutTime" BU_SG_REL_ SR_RR SG_ 1552 DACUSwVersion_Substring6 60000;
BA_REL_ "GenSigFirstTimeoutTime" BU_SG_REL_ SR_LF SG_ 1552 DACUSwVersion_Substring2 60000;
BA_REL_ "GenSigTimeoutTime" BU_SG_REL_ SR_LF SG_ 1552 DACUSwVersion_Substring2 60000;
BA_REL_ "GenSigFirstTimeoutTime" BU_SG_REL_ SR_RF SG_ 1552 DACUSwVersion_Substring2 60000;
BA_REL_ "GenSigTimeoutTime" BU_SG_REL_ SR_RF SG_ 1552 DACUSwVersion_Substring2 60000;
BA_REL_ "GenSigFirstTimeoutTime" BU_SG_REL_ SR_LR SG_ 1552 DACUSwVersion_Substring2 60000;
BA_REL_ "GenSigTimeoutTime" BU_SG_REL_ SR_LR SG_ 1552 DACUSwVersion_Substring2 60000;
BA_REL_ "GenSigFirstTimeoutTime" BU_SG_REL_ SR_RR SG_ 1552 DACUSwVersion_Substring2 60000;
BA_REL_ "GenSigTimeoutTime" BU_SG_REL_ SR_RR SG_ 1552 DACUSwVersion_Substring2 60000;
BA_REL_ "GenSigFirstTimeoutTime" BU_SG_REL_ SR_RF SG_ 1552 DACUSwVersion_Substring5 60000;
BA_REL_ "GenSigTimeoutTime" BU_SG_REL_ SR_RF SG_ 1552 DACUSwVersion_Substring5 60000;
BA_REL_ "GenSigFirstTimeoutTime" BU_SG_REL_ SR_LR SG_ 1552 DACUSwVersion_Substring5 60000;
BA_REL_ "GenSigTimeoutTime" BU_SG_REL_ SR_LR SG_ 1552 DACUSwVersion_Substring5 60000;
BA_REL_ "GenSigFirstTimeoutTime" BU_SG_REL_ SR_RR SG_ 1552 DACUSwVersion_Substring5 60000;
BA_REL_ "GenSigTimeoutTime" BU_SG_REL_ SR_RR SG_ 1552 DACUSwVersion_Substring5 60000;
BA_REL_ "GenSigFirstTimeoutTime" BU_SG_REL_ SR_LF SG_ 1552 DACUSwVersion_Substring5 60000;
BA_REL_ "GenSigTimeoutTime" BU_SG_REL_ SR_LF SG_ 1552 DACUSwVersion_Substring5 60000;
VAL_ 277 EgoMotionRaw_ASREngineA 3 "PassiveActive2_DontCareTakeNoAction" 2 "PassiveActive2_Reserved" 1 "PassiveActive2_Active" 0 "PassiveActive2_PassiveButInstalled" ;
VAL_ 277 EgoMotionRaw_ASRBrakeA 3 "PassiveActive2_DontCareTakeNoAction" 2 "PassiveActive2_Reserved" 1 "PassiveActive2_Active" 0 "PassiveActive2_PassiveButInstalled" ;
VAL_ 277 EgoMotionRaw_ABSActive 3 "AntiLockBrakingActive_NotAvailable" 2 "AntiLockBrakingActive_Reserved" 1 "AntiLockBrakingActive_ABSActive" 0 "AntiLockBrakingActive_ABSPassiveButInstalled" ;
VAL_ 277 EgoMotionRaw_VDCFullyOperational 3 "FullyOperational_NotAvailable" 2 "FullyOperational_Reserved" 1 "FullyOperational_FullyOperational" 0 "FullyOperational_NotFullyOperational" ;
VAL_ 277 EgoMotionRaw_ROPEngineActive 3 "PassiveActive2_DontCareTakeNoAction" 2 "PassiveActive2_Reserved" 1 "PassiveActive2_Active" 0 "PassiveActive2_PassiveButInstalled" ;
VAL_ 277 EgoMotionRaw_YCBrakeActive 3 "PassiveActive2_DontCareTakeNoAction" 2 "PassiveActive2_Reserved" 1 "PassiveActive2_Active" 0 "PassiveActive2_PassiveButInstalled" ;
VAL_ 277 EgoMotionRaw_TrailerConStatus 15 "TrailerConStatus_NotAvailableOrNotInstalled" 14 "TrailerConStatus_ErrorIndicator" 13 "TrailerConStatus_Unknown" 12 "TrailerConStatus_AtLeastOneSegmentConnectedNoAbs" 11 "TrailerConStatus_AtLeastOneSegmentConnected" 10 "TrailerConStatus_FiveOrMoreSegmentsConnectedNoAbs" 9 "TrailerConStatus_FourTrailerSegmentsConnectedNoAbs" 8 "TrailerConStatus_ThreeTrailerSegmentsConnectedNoAbs" 7 "TrailerConStatus_TwoTrailerSegmentsConnectedNoAbs" 6 "TrailerConStatus_OneTrailerSegmentConnectedNoAbs" 5 "TrailerConStatus_FiveOrMoreSegmentsConnected" 4 "TrailerConStatus_FourTrailerSegmentsConnected" 3 "TrailerConStatus_ThreeTrailerSegmentsConnected" 2 "TrailerConStatus_TwoTrailerSegmentsConnected" 1 "TrailerConStatus_OneTrailerSegmentConnected" 0 "TrailerConStatus_NoTrailerConnected" ;
VAL_ 277 EgoMotionRaw_ABSOp 3 "FullyOperational_NotAvailable" 2 "FullyOperational_Reserved" 1 "FullyOperational_FullyOperational" 0 "FullyOperational_NotFullyOperational" ;
VAL_ 277 EgoMotionRaw_ROPBrakeActive 3 "PassiveActive2_DontCareTakeNoAction" 2 "PassiveActive2_Reserved" 1 "PassiveActive2_Active" 0 "PassiveActive2_PassiveButInstalled" ;
VAL_ 277 EgoMotionRaw_YCEngineActive 3 "PassiveActive2_DontCareTakeNoAction" 2 "PassiveActive2_Reserved" 1 "PassiveActive2_Active" 0 "PassiveActive2_PassiveButInstalled" ;
VAL_ 277 EgoMotionRaw_AccKckDwn 3 "PassiveActive_NotAvailable" 2 "PassiveActive_Error" 1 "PassiveActive_Active" 0 "PassiveActive_Passive" ;
VAL_ 1541 Trailer1Data_Validity 3 "Validity_NotAvailable" 2 "Validity_Error" 1 "Validity_DataValid" 0 "Validity_DataNotValid" ;
VAL_ 1541 Trailer4Data_Validity 3 "Validity_NotAvailable" 2 "Validity_Error" 1 "Validity_DataValid" 0 "Validity_DataNotValid" ;
VAL_ 1541 Trailer5Data_Validity 3 "Validity_NotAvailable" 2 "Validity_Error" 1 "Validity_DataValid" 0 "Validity_DataNotValid" ;
VAL_ 1541 Trailer3Data_Validity 3 "Validity_NotAvailable" 2 "Validity_Error" 1 "Validity_DataValid" 0 "Validity_DataNotValid" ;
VAL_ 1541 Trailer2Data_Validity 3 "Validity_NotAvailable" 2 "Validity_Error" 1 "Validity_DataValid" 0 "Validity_DataNotValid" ;
VAL_ 1265 Trailer1GeometricData_Index 255 "TrailerGeometricDataIndex_NotAvailable" 254 "TrailerGeometricDataIndex_Error" 38 "TrailerGeometricDataIndex_TrailerHeightRear" 37 "TrailerGeometricDataIndex_ChassisHeight" 36 "TrailerGeometricDataIndex_TrailerHeightFront" 35 "TrailerGeometricDataIndex_LoadingHeightFront" 34 "TrailerGeometricDataIndex_LoadingHeightRear" 33 "TrailerGeometricDataIndex_CouplingHeight2" 32 "TrailerGeometricDataIndex_CouplingHeight1" 31 "TrailerGeometricDataIndex_TotalLengthOfTrailer" 30 "TrailerGeometricDataIndex_DistanceFirstToSecondCouplingPoint" 29 "TrailerGeometricDataIndex_WheelBaseAxle19ToAxle20" 28 "TrailerGeometricDataIndex_WheelBaseAxle18ToAxle19" 27 "TrailerGeometricDataIndex_WheelBaseAxle17ToAxle18" 26 "TrailerGeometricDataIndex_WheelBaseAxle16ToAxle17" 25 "TrailerGeometricDataIndex_WheelBaseAxle15ToAxle16" 24 "TrailerGeometricDataIndex_WheelBaseAxle14ToAxle15" 23 "TrailerGeometricDataIndex_WheelBaseAxle13ToAxle14" 22 "TrailerGeometricDataIndex_WheelBaseAxle12ToAxle13" 21 "TrailerGeometricDataIndex_WheelBaseAxle11ToAxle12" 20 "TrailerGeometricDataIndex_WheelBaseAxle10ToAxle11" 19 "TrailerGeometricDataIndex_WheelBaseAxle9ToAxle10" 18 "TrailerGeometricDataIndex_WheelBaseAxle8ToAxle9" 17 "TrailerGeometricDataIndex_WheelBaseAxle7ToAxle8" 16 "TrailerGeometricDataIndex_WheelBaseAxle6ToAxle7" 15 "TrailerGeometricDataIndex_WheelBaseAxle5ToAxle6" 14 "TrailerGeometricDataIndex_WheelBaseAxle4ToAxle5" 13 "TrailerGeometricDataIndex_WheelBaseAxle3ToAxle4" 12 "TrailerGeometricDataIndex_WheelBaseAxle2ToAxle3" 11 "TrailerGeometricDataIndex_WheelBaseAxle1ToAxle2" 10 "TrailerGeometricDataIndex_AxleNumberOfLiftAxle5" 9 "TrailerGeometricDataIndex_AxleNumberOfLiftAxle4" 8 "TrailerGeometricDataIndex_AxleNumberOfLiftAxle3" 7 "TrailerGeometricDataIndex_AxleNumberOfLiftAxle2" 6 "TrailerGeometricDataIndex_AxleNumberOfLiftAxle1" 5 "TrailerGeometricDataIndex_NumberOfLiftAxles" 4 "TrailerGeometricDataIndex_NumberOfFrontAxles" 3 "TrailerGeometricDataIndex_NumberOfAxles" 2 "TrailerGeometricDataIndex_TrackWidth" 1 "TrailerGeometricDataIndex_DistanceCouplingToAxle1" 0 "TrailerGeometricDataIndex_TypeOfTrailer" ;
VAL_ 1265 Trailer5GeometricData_Index 255 "TrailerGeometricDataIndex_NotAvailable" 254 "TrailerGeometricDataIndex_Error" 38 "TrailerGeometricDataIndex_TrailerHeightRear" 37 "TrailerGeometricDataIndex_ChassisHeight" 36 "TrailerGeometricDataIndex_TrailerHeightFront" 35 "TrailerGeometricDataIndex_LoadingHeightFront" 34 "TrailerGeometricDataIndex_LoadingHeightRear" 33 "TrailerGeometricDataIndex_CouplingHeight2" 32 "TrailerGeometricDataIndex_CouplingHeight1" 31 "TrailerGeometricDataIndex_TotalLengthOfTrailer" 30 "TrailerGeometricDataIndex_DistanceFirstToSecondCouplingPoint" 29 "TrailerGeometricDataIndex_WheelBaseAxle19ToAxle20" 28 "TrailerGeometricDataIndex_WheelBaseAxle18ToAxle19" 27 "TrailerGeometricDataIndex_WheelBaseAxle17ToAxle18" 26 "TrailerGeometricDataIndex_WheelBaseAxle16ToAxle17" 25 "TrailerGeometricDataIndex_WheelBaseAxle15ToAxle16" 24 "TrailerGeometricDataIndex_WheelBaseAxle14ToAxle15" 23 "TrailerGeometricDataIndex_WheelBaseAxle13ToAxle14" 22 "TrailerGeometricDataIndex_WheelBaseAxle12ToAxle13" 21 "TrailerGeometricDataIndex_WheelBaseAxle11ToAxle12" 20 "TrailerGeometricDataIndex_WheelBaseAxle10ToAxle11" 19 "TrailerGeometricDataIndex_WheelBaseAxle9ToAxle10" 18 "TrailerGeometricDataIndex_WheelBaseAxle8ToAxle9" 17 "TrailerGeometricDataIndex_WheelBaseAxle7ToAxle8" 16 "TrailerGeometricDataIndex_WheelBaseAxle6ToAxle7" 15 "TrailerGeometricDataIndex_WheelBaseAxle5ToAxle6" 14 "TrailerGeometricDataIndex_WheelBaseAxle4ToAxle5" 13 "TrailerGeometricDataIndex_WheelBaseAxle3ToAxle4" 12 "TrailerGeometricDataIndex_WheelBaseAxle2ToAxle3" 11 "TrailerGeometricDataIndex_WheelBaseAxle1ToAxle2" 10 "TrailerGeometricDataIndex_AxleNumberOfLiftAxle5" 9 "TrailerGeometricDataIndex_AxleNumberOfLiftAxle4" 8 "TrailerGeometricDataIndex_AxleNumberOfLiftAxle3" 7 "TrailerGeometricDataIndex_AxleNumberOfLiftAxle2" 6 "TrailerGeometricDataIndex_AxleNumberOfLiftAxle1" 5 "TrailerGeometricDataIndex_NumberOfLiftAxles" 4 "TrailerGeometricDataIndex_NumberOfFrontAxles" 3 "TrailerGeometricDataIndex_NumberOfAxles" 2 "TrailerGeometricDataIndex_TrackWidth" 1 "TrailerGeometricDataIndex_DistanceCouplingToAxle1" 0 "TrailerGeometricDataIndex_TypeOfTrailer" ;
VAL_ 1265 Trailer4GeometricData_Index 255 "TrailerGeometricDataIndex_NotAvailable" 254 "TrailerGeometricDataIndex_Error" 38 "TrailerGeometricDataIndex_TrailerHeightRear" 37 "TrailerGeometricDataIndex_ChassisHeight" 36 "TrailerGeometricDataIndex_TrailerHeightFront" 35 "TrailerGeometricDataIndex_LoadingHeightFront" 34 "TrailerGeometricDataIndex_LoadingHeightRear" 33 "TrailerGeometricDataIndex_CouplingHeight2" 32 "TrailerGeometricDataIndex_CouplingHeight1" 31 "TrailerGeometricDataIndex_TotalLengthOfTrailer" 30 "TrailerGeometricDataIndex_DistanceFirstToSecondCouplingPoint" 29 "TrailerGeometricDataIndex_WheelBaseAxle19ToAxle20" 28 "TrailerGeometricDataIndex_WheelBaseAxle18ToAxle19" 27 "TrailerGeometricDataIndex_WheelBaseAxle17ToAxle18" 26 "TrailerGeometricDataIndex_WheelBaseAxle16ToAxle17" 25 "TrailerGeometricDataIndex_WheelBaseAxle15ToAxle16" 24 "TrailerGeometricDataIndex_WheelBaseAxle14ToAxle15" 23 "TrailerGeometricDataIndex_WheelBaseAxle13ToAxle14" 22 "TrailerGeometricDataIndex_WheelBaseAxle12ToAxle13" 21 "TrailerGeometricDataIndex_WheelBaseAxle11ToAxle12" 20 "TrailerGeometricDataIndex_WheelBaseAxle10ToAxle11" 19 "TrailerGeometricDataIndex_WheelBaseAxle9ToAxle10" 18 "TrailerGeometricDataIndex_WheelBaseAxle8ToAxle9" 17 "TrailerGeometricDataIndex_WheelBaseAxle7ToAxle8" 16 "TrailerGeometricDataIndex_WheelBaseAxle6ToAxle7" 15 "TrailerGeometricDataIndex_WheelBaseAxle5ToAxle6" 14 "TrailerGeometricDataIndex_WheelBaseAxle4ToAxle5" 13 "TrailerGeometricDataIndex_WheelBaseAxle3ToAxle4" 12 "TrailerGeometricDataIndex_WheelBaseAxle2ToAxle3" 11 "TrailerGeometricDataIndex_WheelBaseAxle1ToAxle2" 10 "TrailerGeometricDataIndex_AxleNumberOfLiftAxle5" 9 "TrailerGeometricDataIndex_AxleNumberOfLiftAxle4" 8 "TrailerGeometricDataIndex_AxleNumberOfLiftAxle3" 7 "TrailerGeometricDataIndex_AxleNumberOfLiftAxle2" 6 "TrailerGeometricDataIndex_AxleNumberOfLiftAxle1" 5 "TrailerGeometricDataIndex_NumberOfLiftAxles" 4 "TrailerGeometricDataIndex_NumberOfFrontAxles" 3 "TrailerGeometricDataIndex_NumberOfAxles" 2 "TrailerGeometricDataIndex_TrackWidth" 1 "TrailerGeometricDataIndex_DistanceCouplingToAxle1" 0 "TrailerGeometricDataIndex_TypeOfTrailer" ;
VAL_ 1265 Trailer2GeometricData_Index 255 "TrailerGeometricDataIndex_NotAvailable" 254 "TrailerGeometricDataIndex_Error" 38 "TrailerGeometricDataIndex_TrailerHeightRear" 37 "TrailerGeometricDataIndex_ChassisHeight" 36 "TrailerGeometricDataIndex_TrailerHeightFront" 35 "TrailerGeometricDataIndex_LoadingHeightFront" 34 "TrailerGeometricDataIndex_LoadingHeightRear" 33 "TrailerGeometricDataIndex_CouplingHeight2" 32 "TrailerGeometricDataIndex_CouplingHeight1" 31 "TrailerGeometricDataIndex_TotalLengthOfTrailer" 30 "TrailerGeometricDataIndex_DistanceFirstToSecondCouplingPoint" 29 "TrailerGeometricDataIndex_WheelBaseAxle19ToAxle20" 28 "TrailerGeometricDataIndex_WheelBaseAxle18ToAxle19" 27 "TrailerGeometricDataIndex_WheelBaseAxle17ToAxle18" 26 "TrailerGeometricDataIndex_WheelBaseAxle16ToAxle17" 25 "TrailerGeometricDataIndex_WheelBaseAxle15ToAxle16" 24 "TrailerGeometricDataIndex_WheelBaseAxle14ToAxle15" 23 "TrailerGeometricDataIndex_WheelBaseAxle13ToAxle14" 22 "TrailerGeometricDataIndex_WheelBaseAxle12ToAxle13" 21 "TrailerGeometricDataIndex_WheelBaseAxle11ToAxle12" 20 "TrailerGeometricDataIndex_WheelBaseAxle10ToAxle11" 19 "TrailerGeometricDataIndex_WheelBaseAxle9ToAxle10" 18 "TrailerGeometricDataIndex_WheelBaseAxle8ToAxle9" 17 "TrailerGeometricDataIndex_WheelBaseAxle7ToAxle8" 16 "TrailerGeometricDataIndex_WheelBaseAxle6ToAxle7" 15 "TrailerGeometricDataIndex_WheelBaseAxle5ToAxle6" 14 "TrailerGeometricDataIndex_WheelBaseAxle4ToAxle5" 13 "TrailerGeometricDataIndex_WheelBaseAxle3ToAxle4" 12 "TrailerGeometricDataIndex_WheelBaseAxle2ToAxle3" 11 "TrailerGeometricDataIndex_WheelBaseAxle1ToAxle2" 10 "TrailerGeometricDataIndex_AxleNumberOfLiftAxle5" 9 "TrailerGeometricDataIndex_AxleNumberOfLiftAxle4" 8 "TrailerGeometricDataIndex_AxleNumberOfLiftAxle3" 7 "TrailerGeometricDataIndex_AxleNumberOfLiftAxle2" 6 "TrailerGeometricDataIndex_AxleNumberOfLiftAxle1" 5 "TrailerGeometricDataIndex_NumberOfLiftAxles" 4 "TrailerGeometricDataIndex_NumberOfFrontAxles" 3 "TrailerGeometricDataIndex_NumberOfAxles" 2 "TrailerGeometricDataIndex_TrackWidth" 1 "TrailerGeometricDataIndex_DistanceCouplingToAxle1" 0 "TrailerGeometricDataIndex_TypeOfTrailer" ;
VAL_ 1265 Trailer3GeometricData_Index 255 "TrailerGeometricDataIndex_NotAvailable" 254 "TrailerGeometricDataIndex_Error" 38 "TrailerGeometricDataIndex_TrailerHeightRear" 37 "TrailerGeometricDataIndex_ChassisHeight" 36 "TrailerGeometricDataIndex_TrailerHeightFront" 35 "TrailerGeometricDataIndex_LoadingHeightFront" 34 "TrailerGeometricDataIndex_LoadingHeightRear" 33 "TrailerGeometricDataIndex_CouplingHeight2" 32 "TrailerGeometricDataIndex_CouplingHeight1" 31 "TrailerGeometricDataIndex_TotalLengthOfTrailer" 30 "TrailerGeometricDataIndex_DistanceFirstToSecondCouplingPoint" 29 "TrailerGeometricDataIndex_WheelBaseAxle19ToAxle20" 28 "TrailerGeometricDataIndex_WheelBaseAxle18ToAxle19" 27 "TrailerGeometricDataIndex_WheelBaseAxle17ToAxle18" 26 "TrailerGeometricDataIndex_WheelBaseAxle16ToAxle17" 25 "TrailerGeometricDataIndex_WheelBaseAxle15ToAxle16" 24 "TrailerGeometricDataIndex_WheelBaseAxle14ToAxle15" 23 "TrailerGeometricDataIndex_WheelBaseAxle13ToAxle14" 22 "TrailerGeometricDataIndex_WheelBaseAxle12ToAxle13" 21 "TrailerGeometricDataIndex_WheelBaseAxle11ToAxle12" 20 "TrailerGeometricDataIndex_WheelBaseAxle10ToAxle11" 19 "TrailerGeometricDataIndex_WheelBaseAxle9ToAxle10" 18 "TrailerGeometricDataIndex_WheelBaseAxle8ToAxle9" 17 "TrailerGeometricDataIndex_WheelBaseAxle7ToAxle8" 16 "TrailerGeometricDataIndex_WheelBaseAxle6ToAxle7" 15 "TrailerGeometricDataIndex_WheelBaseAxle5ToAxle6" 14 "TrailerGeometricDataIndex_WheelBaseAxle4ToAxle5" 13 "TrailerGeometricDataIndex_WheelBaseAxle3ToAxle4" 12 "TrailerGeometricDataIndex_WheelBaseAxle2ToAxle3" 11 "TrailerGeometricDataIndex_WheelBaseAxle1ToAxle2" 10 "TrailerGeometricDataIndex_AxleNumberOfLiftAxle5" 9 "TrailerGeometricDataIndex_AxleNumberOfLiftAxle4" 8 "TrailerGeometricDataIndex_AxleNumberOfLiftAxle3" 7 "TrailerGeometricDataIndex_AxleNumberOfLiftAxle2" 6 "TrailerGeometricDataIndex_AxleNumberOfLiftAxle1" 5 "TrailerGeometricDataIndex_NumberOfLiftAxles" 4 "TrailerGeometricDataIndex_NumberOfFrontAxles" 3 "TrailerGeometricDataIndex_NumberOfAxles" 2 "TrailerGeometricDataIndex_TrackWidth" 1 "TrailerGeometricDataIndex_DistanceCouplingToAxle1" 0 "TrailerGeometricDataIndex_TypeOfTrailer" ;
VAL_ 929 Trailer2LiftAxle1Pos 3 "TrailerLiftAxlePos_NotAvailable" 2 "TrailerLiftAxlePos_Error" 1 "TrailerLiftAxlePos_AxleLifted" 0 "TrailerLiftAxlePos_AxleDown" ;
VAL_ 929 Trailer1LiftAxle1Pos 3 "TrailerLiftAxlePos_NotAvailable" 2 "TrailerLiftAxlePos_Error" 1 "TrailerLiftAxlePos_AxleLifted" 0 "TrailerLiftAxlePos_AxleDown" ;
VAL_ 929 Trailer5LiftAxle1Pos 3 "TrailerLiftAxlePos_NotAvailable" 2 "TrailerLiftAxlePos_Error" 1 "TrailerLiftAxlePos_AxleLifted" 0 "TrailerLiftAxlePos_AxleDown" ;
VAL_ 929 Trailer2LiftAxle2Pos 3 "TrailerLiftAxlePos_NotAvailable" 2 "TrailerLiftAxlePos_Error" 1 "TrailerLiftAxlePos_AxleLifted" 0 "TrailerLiftAxlePos_AxleDown" ;
VAL_ 929 Trailer4LiftAxle2Pos 3 "TrailerLiftAxlePos_NotAvailable" 2 "TrailerLiftAxlePos_Error" 1 "TrailerLiftAxlePos_AxleLifted" 0 "TrailerLiftAxlePos_AxleDown" ;
VAL_ 929 Trailer1LiftAxle2Pos 3 "TrailerLiftAxlePos_NotAvailable" 2 "TrailerLiftAxlePos_Error" 1 "TrailerLiftAxlePos_AxleLifted" 0 "TrailerLiftAxlePos_AxleDown" ;
VAL_ 929 TrailerWithoutABS 3 "TrailerWithoutABS_NotAvailableOrNotInstalled" 2 "TrailerWithoutABS_ErrorIndicator" 1 "TrailerWithoutABS_YesTrailerWithoutABS" 0 "TrailerWithoutABS_NoNoTrailerPresentOraTrailerWithABS" ;
VAL_ 929 Trailer5LiftAxle2Pos 3 "TrailerLiftAxlePos_NotAvailable" 2 "TrailerLiftAxlePos_Error" 1 "TrailerLiftAxlePos_AxleLifted" 0 "TrailerLiftAxlePos_AxleDown" ;
VAL_ 929 Trailer4LiftAxle1Pos 3 "TrailerLiftAxlePos_NotAvailable" 2 "TrailerLiftAxlePos_Error" 1 "TrailerLiftAxlePos_AxleLifted" 0 "TrailerLiftAxlePos_AxleDown" ;
VAL_ 929 Trailer3LiftAxle2Pos 3 "TrailerLiftAxlePos_NotAvailable" 2 "TrailerLiftAxlePos_Error" 1 "TrailerLiftAxlePos_AxleLifted" 0 "TrailerLiftAxlePos_AxleDown" ;
VAL_ 929 Trailer3LiftAxle1Pos 3 "TrailerLiftAxlePos_NotAvailable" 2 "TrailerLiftAxlePos_Error" 1 "TrailerLiftAxlePos_AxleLifted" 0 "TrailerLiftAxlePos_AxleDown" ;
VAL_ 929 SRadarLoggingTrigger 7 "SensorLoggingTrigger_NotAvailable" 6 "SensorLoggingTrigger_Error" 5 "SensorLoggingTrigger_Trigger5" 4 "SensorLoggingTrigger_Trigger4" 3 "SensorLoggingTrigger_Trigger3" 2 "SensorLoggingTrigger_Trigger2" 1 "SensorLoggingTrigger_Trigger1" 0 "SensorLoggingTrigger_NoTrigger" ;
VAL_ 547 LiftAxle1PositionStatus 7 "LiftAxlePositionStatus_NotAvailable" 6 "LiftAxlePositionStatus_Error" 5 "LiftAxlePositionStatus_Reserved_01" 4 "LiftAxlePositionStatus_Reserved" 3 "LiftAxlePositionStatus_Lifting" 2 "LiftAxlePositionStatus_Lowering" 1 "LiftAxlePositionStatus_Lifted" 0 "LiftAxlePositionStatus_Lowered" ;
VAL_ 547 VehicleMode 15 "VehicleMode_NotAvailable" 14 "VehicleMode_Error" 13 "VehicleMode_Spare_7" 12 "VehicleMode_Spare_6" 11 "VehicleMode_Spare_5" 10 "VehicleMode_Spare_4" 9 "VehicleMode_Spare_3" 8 "VehicleMode_Spare_2" 7 "VehicleMode_Spare_1" 6 "VehicleMode_Running" 5 "VehicleMode_Cranking" 4 "VehicleMode_PreRunning" 3 "VehicleMode_Accessory" 2 "VehicleMode_Living" 1 "VehicleMode_Parked" 0 "VehicleMode_Hibernate" ;
VAL_ 547 TrailerConnected 3 "NoYes_NotAvailable" 2 "NoYes_Error" 1 "NoYes_Yes" 0 "NoYes_No" ;
VAL_ 547 SideSensorPowerMode 3 "Request_NotAvailable" 2 "Request_Error" 1 "Request_RequestActive" 0 "Request_NotRequested" ;
VAL_ 547 LiftAxle2PositionStatus 7 "LiftAxlePositionStatus_NotAvailable" 6 "LiftAxlePositionStatus_Error" 5 "LiftAxlePositionStatus_Reserved_01" 4 "LiftAxlePositionStatus_Reserved" 3 "LiftAxlePositionStatus_Lifting" 2 "LiftAxlePositionStatus_Lowering" 1 "LiftAxlePositionStatus_Lifted" 0 "LiftAxlePositionStatus_Lowered" ;
VAL_ 547 WiperModeStatus 7 "WiperModeStatus_NotAvailable" 6 "WiperModeStatus_ErrorIndicator" 5 "WiperModeStatus_Spare02" 4 "WiperModeStatus_Spare01" 3 "WiperModeStatus_Spare" 2 "WiperModeStatus_HighSpeedWiping" 1 "WiperModeStatus_LowSpeedWiping" 0 "WiperModeStatus_WiperOff" ;
SIG_GROUP_ 277 EgoMotionRaw_sg 1 : EgoMotionRaw_RAxleLeftWSpeed EgoMotionRaw_RelLvlRrAxleLeft EgoMotionRaw_RelLvlFrAxleRight EgoMotionRaw_AccPedalPos EgoMotionRaw_BrakePedalPosition EgoMotionRaw_FrAxleLeftWSpeed EgoMotionRaw_FrontWheelAngle EgoMotionRaw_ASREngineA EgoMotionRaw_ASRBrakeA EgoMotionRaw_ABSActive EgoMotionRaw_VDCFullyOperational EgoMotionRaw_ROPEngineActive EgoMotionRaw_YCBrakeActive EgoMotionRaw_GrossCombVehWeight EgoMotionRaw_RelLvlFrAxleLeft EgoMotionRaw_Counter EgoMotionRaw_RAxleRightWSpeed EgoMotionRaw_TrailerConStatus EgoMotionRaw_FrAxleRightWSpeed EgoMotionRaw_SteeringWheelAngle EgoMotionRaw_ABSOp EgoMotionRaw_CRC EgoMotionRaw_ROPBrakeActive EgoMotionRaw_RelLvlRrAxleRight EgoMotionRaw_YCEngineActive EgoMotionRaw_SteeringWheelRatio EgoMotionRaw_AccKckDwn;
SIG_GROUP_ 1541 Trailer1Data_sg 1 : Trailer1Data_Validity Trailer1Data_Length Trailer1Data_Wheelbase Trailer1Data_TotAxleCount Trailer1Data_DistToCouplingP Trailer1Data_FrAxleCount Trailer1Data_Type Trailer1Data_DrawbarLength;
SIG_GROUP_ 1541 Trailer5Data_sg 1 : Trailer5Data_TotAxleCount Trailer5Data_DistToCouplingP Trailer5Data_Type Trailer5Data_Validity Trailer5Data_FrAxleCount Trailer5Data_Wheelbase Trailer5Data_Length Trailer5Data_DrawbarLength;
SIG_GROUP_ 1541 Trailer3Data_sg 1 : Trailer3Data_FrAxleCount Trailer3Data_Wheelbase Trailer3Data_Length Trailer3Data_DistToCouplingP Trailer3Data_DrawbarLength Trailer3Data_Validity Trailer3Data_TotAxleCount Trailer3Data_Type;
SIG_GROUP_ 1541 Trailer2Data_sg 1 : Trailer2Data_DistToCouplingP Trailer2Data_Wheelbase Trailer2Data_DrawbarLength Trailer2Data_TotAxleCount Trailer2Data_Validity Trailer2Data_FrAxleCount Trailer2Data_Type Trailer2Data_Length;
SIG_GROUP_ 1541 Trailer4Data_sg 1 : Trailer4Data_Validity Trailer4Data_Type Trailer4Data_TotAxleCount Trailer4Data_Length Trailer4Data_Wheelbase Trailer4Data_DistToCouplingP Trailer4Data_FrAxleCount Trailer4Data_DrawbarLength;
SIG_GROUP_ 1543 VIN_DACU_sg 1 : VIN_DACU_Byte06 VIN_DACU_Byte08 VIN_DACU_Byte00 VIN_DACU_Byte16 VIN_DACU_Byte04 VIN_DACU_Byte10 VIN_DACU_Byte14 VIN_DACU_Byte12 VIN_DACU_Byte07 VIN_DACU_Byte15 VIN_DACU_Byte09 VIN_DACU_Byte05 VIN_DACU_Byte02 VIN_DACU_Byte11 VIN_DACU_Byte01 VIN_DACU_Byte03 VIN_DACU_Byte13;
SIG_GROUP_ 1265 Trailer3GeometricData_sg 1 : Trailer3GeometricData_Content Trailer3GeometricData_Index;
SIG_GROUP_ 1265 Trailer1GeometricData_sg 1 : Trailer1GeometricData_Content Trailer1GeometricData_Index;
SIG_GROUP_ 1265 Trailer2GeometricData_sg 1 : Trailer2GeometricData_Content Trailer2GeometricData_Index;
SIG_GROUP_ 1265 Trailer4GeometricData_sg 1 : Trailer4GeometricData_Content Trailer4GeometricData_Index;
SIG_GROUP_ 1265 Trailer5GeometricData_sg 1 : Trailer5GeometricData_Index Trailer5GeometricData_Content;
SIG_GROUP_ 1552 DACUSwVersion_sg 1 : DACUSwVersion_Substring3 DACUSwVersion_Substring1 DACUSwVersion_Substring4 DACUSwVersion_Substring7 DACUSwVersion_Substring0 DACUSwVersion_Substring6 DACUSwVersion_Substring2 DACUSwVersion_Substring5;
